VERSION ""

NS_ :

BS_:

BU_: VMCU TECU OBDScanT2 IC3 HPCU EMS ECUspare2 ECUspare1 DACU CIOM BBM

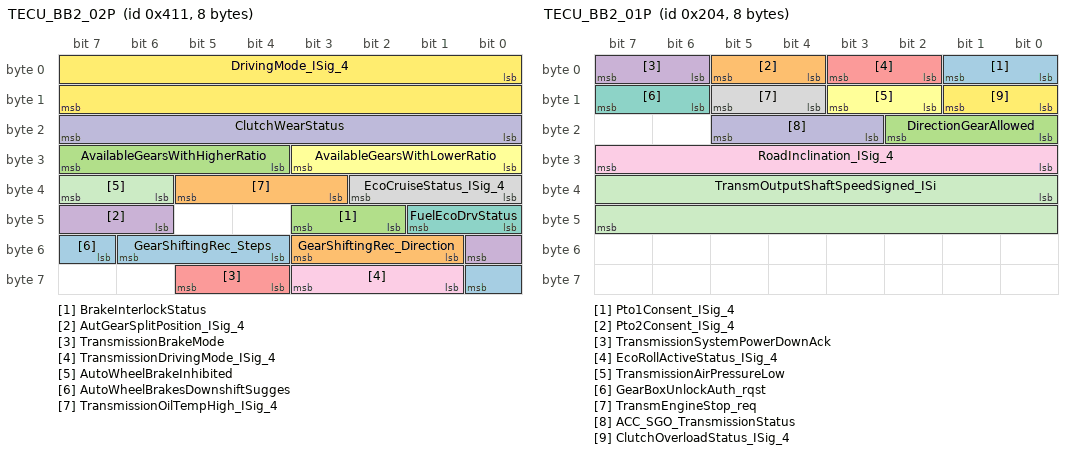
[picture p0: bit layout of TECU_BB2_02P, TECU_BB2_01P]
BO_ 1041 TECU_BB2_02P: 8 TECU
 SG_ GearShiftingRec_Steps : 52|3@1+ (1,0) [0|0] ""  IC3
 SG_ GearShiftingRec_Direction : 49|3@1+ (1,0) [0|0] ""  IC3
 SG_ BrakeInterlockStatus : 42|2@1+ (1,0) [0|0] ""  IC3,VMCU
 SG_ AutGearSplitPosition_ISig_4 : 46|3@1+ (1,0) [0|0] ""  IC3,BBM
 SG_ TransmissionBrakeMode : 60|2@1+ (1,0) [0|0] ""  IC3
 SG_ AvailableGearsWithLowerRatio : 24|4@1+ (1,0) [0|15] "Count"  IC3
 SG_ FuelEcoDrvStatus : 40|2@1+ (1,0) [0|0] ""  VMCU
 SG_ EcoCruiseStatus_ISig_4 : 32|3@1+ (1,0) [0|0] ""  IC3,EMS
 SG_ TransmissionDrivingMode_ISig_4 : 57|3@1+ (1,0) [0|0] ""  VMCU,DACU,IC3
 SG_ ClutchWearStatus : 16|8@1+ (0.4,0) [0|102] "Percent"  VMCU
 SG_ AutoWheelBrakeInhibited : 38|2@1+ (1,0) [0|0] ""  EMS
 SG_ DrivingMode_ISig_4 : 0|16@1+ (1,0) [0|0] ""  VMCU,IC3
 SG_ AutoWheelBrakesDownshiftSugges : 55|2@1+ (1,0) [0|0] ""  IC3
 SG_ TransmissionOilTempHigh_ISig_4 : 35|3@1+ (1,0) [0|0] ""  BBM,IC3
 SG_ AvailableGearsWithHigherRatio : 28|4@1+ (1,0) [0|15] "Count"  VMCU,IC3

BO_ 516 TECU_BB2_01P: 8 TECU
 SG_ Pto1Consent_ISig_4 : 0|2@1+ (1,0) [0|0] ""  BBM,VMCU
 SG_ Pto2Consent_ISig_4 : 4|2@1+ (1,0) [0|0] ""  BBM,VMCU
 SG_ DirectionGearAllowed : 16|3@1+ (1,0) [0|0] ""  VMCU
 SG_ TransmissionSystemPowerDownAck : 6|2@1+ (1,0) [0|0] ""  VMCU
 SG_ EcoRollActiveStatus_ISig_4 : 2|2@1+ (1,0) [0|0] ""  IC3,VMCU
 SG_ TransmissionAirPressureLow : 10|2@1+ (1,0) [0|0] ""  IC3
 SG_ GearBoxUnlockAuth_rqst : 14|2@1+ (1,0) [0|0] ""  CIOM
 SG_ TransmEngineStop_req : 12|2@1+ (1,0) [0|0] ""  EMS
 SG_ RoadInclination_ISig_4 : 24|8@1+ (0.2,-25) [-25|26] "Percent"  IC3,VMCU,EMS,DACU
 SG_ ACC_SGO_TransmissionStatus : 19|3@1+ (1,0) [0|0] ""  EMS,DACU
 SG_ TransmOutputShaftSpeedSigned_ISi : 32|16@1+ (0.125,-4000) [-4000|4191.875] "rpm"  DACU,VMCU
 SG_ ClutchOverloadStatus_ISig_4 : 8|2@1+ (1,0) [0|0] ""  IC3,BBM

BO_ 1792 Reserved_LogSync_BB2_01S: 8 Vector__XXX

BO_ 2365530173 Reserved_CANid_02_BB2: 8 Vector__XXX

BO_ 2365530429 Reserved_CANid_01_BB2: 8 Vector__XXX

BO_ 2671834660 PhysDiagRespMsg_F6_24_BB2: 8 VMCU
 SG_ PhysDiagRespSig_F6_24_ISig_4 : 0|64@1+ (1,0) [0|0] ""  CIOM

BO_ 2671834640 PhysDiagRespMsg_F6_10_BB2: 8 EMS
 SG_ PhysDiagRespSig_F6_10_ISig_4 : 0|64@1+ (1,0) [0|0] ""  CIOM

BO_ 2671833839 PhysDiagRespMsg_F2_EF_BB2: 8 HPCU
 SG_ PhysDiagRespSig_F2_EF_ISig_4 : 0|64@1+ (1,0) [0|0] ""  VMCU

BO_ 2671833830 PhysDiagRespMsg_F2_E6_BB2: 8 BBM
 SG_ PhysDiagRespSig_F2_E6_ISig_4 : 0|64@1+ (1,0) [0|0] ""  VMCU

BO_ 2671833829 PhysDiagRespMsg_F2_E5_BB2: 8 BBM
 SG_ PhysDiagRespSig_F2_E5_ISig_4 : 0|64@1+ (1,0) [0|0] ""  VMCU

BO_ 2671833794 PhysDiagRespMsg_F2_C2_BB2: 8 HPCU
 SG_ PhysDiagRespSig_F2_C2_ISig_4 : 0|64@1+ (1,0) [0|0] ""  VMCU

BO_ 2671833792 PhysDiagRespMsg_F2_C0_BB2: 8 CIOM
 SG_ PhysDiagRespSig_F2_C0_ISig_4 : 0|64@1+ (1,0) [0|0] ""  VMCU

BO_ 2671833762 PhysDiagRespMsg_F2_A2_BB2: 8 CIOM
 SG_ PhysDiagRespSig_F2_A2_ISig_4 : 0|64@1+ (1,0) [0|0] ""  VMCU

BO_ 2671833761 PhysDiagRespMsg_F2_A1_BB2: 8 CIOM
 SG_ PhysDiagRespSig_F2_A1_ISig_4 : 0|64@1+ (1,0) [0|0] ""  VMCU

BO_ 2671833760 PhysDiagRespMsg_F2_A0_BB2: 8 CIOM
 SG_ PhysDiagRespSig_F2_A0_ISig_4 : 0|64@1+ (1,0) [0|0] ""  VMCU

BO_ 2671833752 PhysDiagRespMsg_F2_98_BB2: 8 CIOM
 SG_ PhysDiagRespSig_F2_98_ISig_4 : 0|64@1+ (1,0) [0|0] ""  VMCU

BO_ 2671833740 PhysDiagRespMsg_F2_8C_BB2: 8 DACU
 SG_ PhysDiagRespSig_F2_8C_ISig_4 : 0|64@1+ (1,0) [0|0] ""  VMCU

BO_ 2671833731 PhysDiagRespMsg_F2_83_BB2: 8 IC3
 SG_ PhysDiagRespSig_F2_83_ISig_4 : 0|64@1+ (1,0) [0|0] ""  VMCU

BO_ 2671833730 PhysDiagRespMsg_F2_82_BB2: 8 IC3
 SG_ PhysDiagRespSig_F2_82_ISig_4 : 0|64@1+ (1,0) [0|0] ""  VMCU

BO_ 2671833700 PhysDiagRespMsg_F2_64_BB2: 8 IC3
 SG_ PhysDiagRespSig_F2_64_ISig_4 : 0|64@1+ (1,0) [0|0] ""  VMCU

BO_ 2671833697 PhysDiagRespMsg_F2_61_BB2: 8 IC3
 SG_ PhysDiagRespSig_F2_61_ISig_4 : 0|64@1+ (1,0) [0|0] ""  VMCU

BO_ 2671833696 PhysDiagRespMsg_F2_60_BB2: 8 IC3
 SG_ PhysDiagRespSig_F2_60_ISig_4 : 0|64@1+ (1,0) [0|0] ""  VMCU

BO_ 2671833683 PhysDiagRespMsg_F2_53_BB2: 8 CIOM
 SG_ PhysDiagRespSig_F2_53_ISig_4 : 0|64@1+ (1,0) [0|0] ""  VMCU

BO_ 2671833682 PhysDiagRespMsg_F2_52_BB2: 8 DACU
 SG_ PhysDiagRespSig_F2_52_ISig_4 : 0|64@1+ (1,0) [0|0] ""  VMCU

BO_ 2671833681 PhysDiagRespMsg_F2_51_BB2: 8 DACU
 SG_ PhysDiagRespSig_F2_51_ISig_4 : 0|64@1+ (1,0) [0|0] ""  VMCU

BO_ 2671833680 PhysDiagRespMsg_F2_50_BB2: 8 DACU
 SG_ PhysDiagRespSig_F2_50_ISig_4 : 0|64@1+ (1,0) [0|0] ""  VMCU

BO_ 2671833665 PhysDiagRespMsg_F2_41_BB2: 8 IC3
 SG_ PhysDiagRespSig_F2_41_ISig_4 : 0|64@1+ (1,0) [0|0] ""  VMCU

BO_ 2671833664 PhysDiagRespMsg_F2_40_BB2: 8 CIOM
 SG_ PhysDiagRespSig_F2_40_ISig_4 : 0|64@1+ (1,0) [0|0] ""  VMCU

BO_ 2671833638 PhysDiagRespMsg_F2_26_BB2: 8 CIOM
 SG_ PhysDiagRespSig_F2_26_ISig_4 : 0|64@1+ (1,0) [0|0] ""  VMCU

BO_ 2671833624 PhysDiagRespMsg_F2_18_BB2: 8 TECU
 SG_ PhysDiagRespSig_F2_18_ISig_4 : 0|64@1+ (1,0) [0|0] ""  VMCU

BO_ 2671833616 PhysDiagRespMsg_F2_10_BB2: 8 EMS
 SG_ PhysDiagRespSig_F2_10_ISig_4 : 0|64@1+ (1,0) [0|0] ""  VMCU

BO_ 2564485459 PhysDiagRespMsg_F1_53_BB2: 8 CIOM
 SG_ PhysDiagRespSig_F1_53_ISig_4 : 0|64@1+ (1,0) [0|0] ""  VMCU

BO_ 2564485392 PhysDiagRespMsg_F1_10_BB2_extra: 8 EMS
 SG_ PhysDiagRespSig_F1_10_extra : 0|64@1+ (1,0) [0|0] ""  OBDScanT2

BO_ 2671833360 PhysDiagRespMsg_F1_10_BB2: 8 EMS
 SG_ PhysDiagRespSig_F1_10_ISig_4 : 0|64@1+ (1,0) [0|0] ""  VMCU

BO_ 2671833074 PhysDiagReqMsg_EF_F2_BB2: 8 VMCU
 SG_ PhysDiagReqSig_EF_F2_ISig_4 : 0|64@1+ (1,0) [0|0] ""  HPCU

BO_ 2671830770 PhysDiagReqMsg_E6_F2_BB2: 8 VMCU
 SG_ PhysDiagReqSig_E6_F2_ISig_4 : 0|64@1+ (1,0) [0|0] ""  BBM

BO_ 2671830514 PhysDiagReqMsg_E5_F2_BB2: 8 VMCU
 SG_ PhysDiagReqSig_E5_F2_ISig_4 : 0|64@1+ (1,0) [0|0] ""  BBM

BO_ 2671821554 PhysDiagReqMsg_C2_F2_BB2: 8 VMCU
 SG_ PhysDiagReqSig_C2_F2_ISig_4 : 0|64@1+ (1,0) [0|0] ""  HPCU

BO_ 2671821042 PhysDiagReqMsg_C0_F2_BB2: 8 VMCU
 SG_ PhysDiagReqSig_C0_F2_ISig_4 : 0|64@1+ (1,0) [0|0] ""  CIOM

BO_ 2671813362 PhysDiagReqMsg_A2_F2_BB2: 8 VMCU
 SG_ PhysDiagReqSig_A2_F2_ISig_4 : 0|64@1+ (1,0) [0|0] ""  CIOM

BO_ 2671813106 PhysDiagReqMsg_A1_F2_BB2: 8 VMCU
 SG_ PhysDiagReqSig_A1_F2_ISig_4 : 0|64@1+ (1,0) [0|0] ""  CIOM

BO_ 2671812850 PhysDiagReqMsg_A0_F2_BB2: 8 VMCU
 SG_ PhysDiagReqSig_A0_F2_ISig_4 : 0|64@1+ (1,0) [0|0] ""  CIOM

BO_ 2671810802 PhysDiagReqMsg_98_F2_BB2: 8 VMCU
 SG_ PhysDiagReqSig_98_F2_ISig_4 : 0|64@1+ (1,0) [0|0] ""  CIOM

BO_ 2671807730 PhysDiagReqMsg_8C_F2_BB2: 8 VMCU
 SG_ PhysDiagReqSig_8C_F2_ISig_4 : 0|64@1+ (1,0) [0|0] ""  DACU

BO_ 2671805426 PhysDiagReqMsg_83_F2_BB2: 8 VMCU
 SG_ PhysDiagReqSig_83_F2_ISig_4 : 0|64@1+ (1,0) [0|0] ""  IC3

BO_ 2671805170 PhysDiagReqMsg_82_F2_BB2: 8 VMCU
 SG_ PhysDiagReqSig_82_F2_ISig_4 : 0|64@1+ (1,0) [0|0] ""  IC3

BO_ 2671797490 PhysDiagReqMsg_64_F2_BB2: 8 VMCU
 SG_ PhysDiagReqSig_64_F2_ISig_4 : 0|64@1+ (1,0) [0|0] ""  IC3

BO_ 2671796722 PhysDiagReqMsg_61_F2_BB2: 8 VMCU
 SG_ PhysDiagReqSig_61_F2_ISig_4 : 0|64@1+ (1,0) [0|0] ""  IC3

BO_ 2671796466 PhysDiagReqMsg_60_F2_BB2: 8 VMCU
 SG_ PhysDiagReqSig_60_F2_ISig_4 : 0|64@1+ (1,0) [0|0] ""  IC3

BO_ 2671793138 PhysDiagReqMsg_53_F2_BB2: 8 VMCU
 SG_ PhysDiagReqSig_53_F2_ISig_4 : 0|64@1+ (1,0) [0|0] ""  CIOM

BO_ 2564445169 PhysDiagReqMsg_53_F1_BB2: 8 VMCU
 SG_ PhysDiagReqSig_53_F1_ISig_4 : 0|64@1+ (1,0) [0|0] ""  CIOM

BO_ 2671792882 PhysDiagReqMsg_52_F2_BB2: 8 VMCU
 SG_ PhysDiagReqSig_52_F2_ISig_4 : 0|64@1+ (1,0) [0|0] ""  DACU

BO_ 2671792626 PhysDiagReqMsg_51_F2_BB2: 8 VMCU
 SG_ PhysDiagReqSig_51_F2_ISig_4 : 0|64@1+ (1,0) [0|0] ""  DACU

BO_ 2671792370 PhysDiagReqMsg_50_F2_BB2: 8 VMCU
 SG_ PhysDiagReqSig_50_F2_ISig_4 : 0|64@1+ (1,0) [0|0] ""  DACU

BO_ 2671788530 PhysDiagReqMsg_41_F2_BB2: 8 VMCU
 SG_ PhysDiagReqSig_41_F2_ISig_4 : 0|64@1+ (1,0) [0|0] ""  IC3

BO_ 2671788274 PhysDiagReqMsg_40_F2_BB2: 8 VMCU
 SG_ PhysDiagReqSig_40_F2_ISig_4 : 0|64@1+ (1,0) [0|0] ""  CIOM

BO_ 2671781618 PhysDiagReqMsg_26_F2_BB2: 8 VMCU
 SG_ PhysDiagReqSig_26_F2_ISig_4 : 0|64@1+ (1,0) [0|0] ""  CIOM

BO_ 2671781110 PhysDiagReqMsg_24_F6_BB2: 8 CIOM
 SG_ PhysDiagReqSig_24_F6_ISig_4 : 0|64@1+ (1,0) [0|0] ""  VMCU

BO_ 2671778034 PhysDiagReqMsg_18_F2_BB2: 8 VMCU
 SG_ PhysDiagReqSig_18_F2_ISig_4 : 0|64@1+ (1,0) [0|0] ""  TECU

BO_ 2671775990 PhysDiagReqMsg_10_F6_BB2: 8 CIOM
 SG_ PhysDiagReqSig_10_F6_ISig_4 : 0|64@1+ (1,0) [0|0] ""  EMS

BO_ 2671775986 PhysDiagReqMsg_10_F2_BB2: 8 VMCU
 SG_ PhysDiagReqSig_10_F2_ISig_4 : 0|64@1+ (1,0) [0|0] ""  EMS

BO_ 2564428017 PhysDiagReqMsg_10_F1_BB2_extra: 8 OBDScanT2
 SG_ PhysDiagReqSig_10_F1_extra : 0|64@1+ (1,0) [0|0] ""  EMS

BO_ 2671775985 PhysDiagReqMsg_10_F1_BB2: 8 VMCU
 SG_ PhysDiagReqSig_10_F1_ISig_4 : 0|64@1+ (1,0) [0|0] ""  EMS

BO_ 2564502513 OBDFuncDiagMsg_BB2_extra: 8 OBDScanT2
 SG_ FuncDiagDataOBD_extra : 0|64@1+ (1,0) [0|0] ""  EMS

BO_ 2671850481 OBDFuncDiagMsg_BB2: 8 VMCU
 SG_ FuncDiagDataOBD_ISig_4 : 0|64@1+ (1,0) [0|0] ""  EMS

BO_ 2671850486 OBDFuncDiagMsgF6_BB2: 8 CIOM
 SG_ FuncDiagDataOBDF6_ISig_4 : 0|64@1+ (1,0) [0|0] ""  EMS,VMCU

BO_ 2633990180 NmAsr_VMCU_BB2: 1 VMCU

BO_ 2633990168 NmAsr_TECU_BB2: 1 TECU

BO_ 2633990383 NmAsr_HPCU_BB2: 1 HPCU

BO_ 2633990240 NmAsr_HMIIOM_BB2: 1 IC3

BO_ 2633990160 NmAsr_EMS_BB2: 1 EMS

BO_ 2633990224 NmAsr_DACU_BB2: 1 DACU

BO_ 2633990208 NmAsr_CIOM_BB2: 1 CIOM

BO_ 2633990374 NmAsr_BBM_BB2: 1 BBM

BO_ 2671902708 IntTesterTGW2FuncDiagMsg_BB2: 8 IC3
 SG_ FuncDiagDataIntTesterTGW2_ISig_4 : 0|64@1+ (1,0) [0|0] ""  EMS,HPCU,BBM,DACU,CIOM,TECU,VMCU

BO_ 1280 IC3_BB2_FAKE1: 8 IC3
 SG_ ExteriorLightsAFSAllowedFAKE : 2|2@1+ (1,0) [0|0] ""  VMCU
 SG_ CamerasPowerSupply_rqstFAKE : 0|2@1+ (1,0) [0|0] ""  VMCU

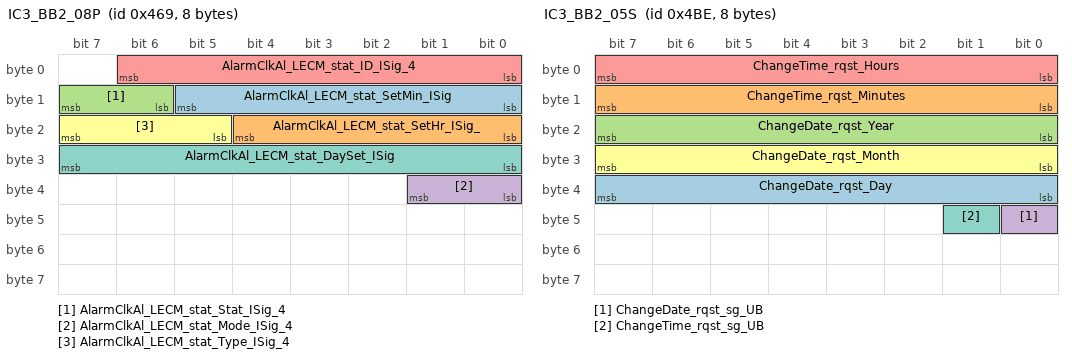
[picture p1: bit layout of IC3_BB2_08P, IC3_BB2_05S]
BO_ 1129 IC3_BB2_08P: 8 IC3
 SG_ AlarmClkAl_LECM_stat_SetMin_ISig : 8|6@1+ (1,0) [0|63] "min"  CIOM
 SG_ AlarmClkAl_LECM_stat_SetHr_ISig_ : 16|5@1+ (1,0) [0|31] "h"  CIOM
 SG_ AlarmClkAl_LECM_stat_Stat_ISig_4 : 14|2@1+ (1,0) [0|0] ""  CIOM
 SG_ AlarmClkAl_LECM_stat_Mode_ISig_4 : 32|2@1+ (1,0) [0|0] ""  CIOM
 SG_ AlarmClkAl_LECM_stat_ID_ISig_4 : 0|7@1+ (1,0) [0|0] ""  CIOM
 SG_ AlarmClkAl_LECM_stat_Type_ISig_4 : 21|3@1+ (1,0) [0|0] ""  CIOM
 SG_ AlarmClkAl_LECM_stat_DaySet_ISig : 24|8@1+ (1,0) [0|255] ""  CIOM

BO_ 1395 IC3_BB2_07S_FCM: 8 CIOM
 SG_ IC3_BB2_07S_FCS : 0|64@1+ (1,0) [0|0] ""  IC3

BO_ 1394 IC3_BB2_07S: 36 IC3
 SG_ DisplayText_stat_ISig_4 : 0|288@1+ (1,0) [0|0] ""  CIOM

BO_ 1444 IC3_BB2_06S_FCM: 8 VMCU
 SG_ IC3_BB2_06S_FCS : 0|64@1+ (1,0) [0|0] ""  IC3

BO_ 1443 IC3_BB2_06S: 21 IC3
 SG_ SaveTrlrName_rqst_Request : 160|2@1+ (1,0) [0|0] ""  VMCU
 SG_ SaveTrlrName_rqst_sg_UB : 167|1@1+ (1,0) [0|0] ""  VMCU
 SG_ SaveTrlrName_rqst_NewName : 0|160@1+ (1,0) [0|0] ""  VMCU
 SG_ SaveTrlrName_rqst_Position : 162|5@1+ (1,0) [0|0] ""  VMCU

BO_ 1214 IC3_BB2_05S: 8 IC3
 SG_ ChangeDate_rqst_Day : 32|8@1+ (1,0) [0|255] "Days"  VMCU
 SG_ ChangeTime_rqst_Minutes : 8|8@1+ (1,0) [0|255] "min"  VMCU
 SG_ ChangeDate_rqst_Year : 16|8@1+ (1,1985) [1985|2240] "Years"  VMCU
 SG_ ChangeDate_rqst_sg_UB : 40|1@1+ (1,0) [0|0] ""  VMCU
 SG_ ChangeTime_rqst_Hours : 0|8@1+ (1,0) [0|255] "h"  VMCU
 SG_ ChangeDate_rqst_Month : 24|8@1+ (1,0) [0|255] "Months"  VMCU
 SG_ ChangeTime_rqst_sg_UB : 41|1@1+ (1,0) [0|0] ""  VMCU

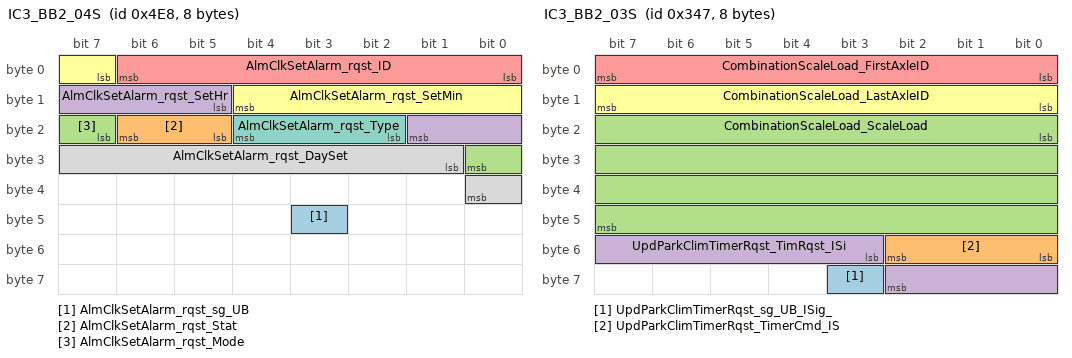
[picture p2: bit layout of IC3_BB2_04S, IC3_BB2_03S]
BO_ 1256 IC3_BB2_04S: 8 IC3
 SG_ AlmClkSetAlarm_rqst_sg_UB : 43|1@1+ (1,0) [0|0] ""  VMCU
 SG_ AlmClkSetAlarm_rqst_Stat : 21|2@1+ (1,0) [0|0] ""  VMCU
 SG_ AlmClkSetAlarm_rqst_Mode : 23|2@1+ (1,0) [0|0] ""  VMCU
 SG_ AlmClkSetAlarm_rqst_SetHr : 13|5@1+ (1,0) [0|31] "h"  VMCU
 SG_ AlmClkSetAlarm_rqst_ID : 0|7@1+ (1,0) [0|0] ""  VMCU
 SG_ AlmClkSetAlarm_rqst_SetMin : 7|6@1+ (1,0) [0|63] "min"  VMCU
 SG_ AlmClkSetAlarm_rqst_Type : 18|3@1+ (1,0) [0|0] ""  VMCU
 SG_ AlmClkSetAlarm_rqst_DaySet : 25|8@1+ (1,0) [0|255] ""  VMCU

BO_ 839 IC3_BB2_03S: 8 IC3
 SG_ UpdParkClimTimerRqst_sg_UB_ISig_ : 59|1@1+ (1,0) [0|0] ""  CIOM
 SG_ UpdParkClimTimerRqst_TimerCmd_IS : 48|3@1+ (1,0) [0|0] ""  CIOM
 SG_ CombinationScaleLoad_ScaleLoad : 16|32@1+ (1,0) [0|4294967295] "kg"  VMCU
 SG_ UpdParkClimTimerRqst_TimRqst_ISi : 51|8@1+ (1,0) [0|0] ""  CIOM
 SG_ CombinationScaleLoad_FirstAxleID : 0|8@1+ (1,0) [0|255] "NotApplicable"  VMCU
 SG_ CombinationScaleLoad_LastAxleID : 8|8@1+ (1,0) [0|255] "NotApplicable"  VMCU

BO_ 838 IC3_BB2_02P: 8 IC3
 SG_ PhoneButtonIndication_cmd : 39|2@1+ (1,0) [0|0] ""  CIOM
 SG_ AirbagTelltale_stat_ISig_4 : 17|2@1+ (1,0) [0|0] ""  CIOM
 SG_ AudioSystemStatus_ISig_4 : 52|2@1+ (1,0) [0|0] ""  CIOM
 SG_ AudioSourceUsbAvailable_ISig_4 : 21|2@1+ (1,0) [0|0] ""  CIOM
 SG_ AQSModeRqst_ISig_4 : 9|3@1+ (1,0) [0|0] ""  CIOM
 SG_ PresetIndicationCmd_ISig_4 : 41|6@1+ (1,0) [0|63] "Enumeration"  CIOM
 SG_ AudioSourceCdAvailable_ISig_4 : 50|2@1+ (1,0) [0|0] ""  CIOM
 SG_ AudioVolumeIndicationCmd_ISig_4 : 31|6@1+ (1,0) [0|63] "Step"  CIOM
 SG_ AudioSourceStatus2_ISig_4 : 59|4@1+ (1,0) [0|0] ""  CIOM
 SG_ BTStatus : 54|2@1+ (1,0) [0|0] ""  CIOM
 SG_ VCSystPowerSupply_rqst : 15|2@1+ (1,0) [0|0] ""  VMCU
 SG_ AudioSourceBtStreamAvailable_ISi : 37|2@1+ (1,0) [0|0] ""  CIOM
 SG_ AudioMuteStat_ISig_4 : 56|3@1+ (1,0) [0|0] ""  CIOM
 SG_ ISeeEnableRequest : 19|2@1+ (1,0) [0|0] ""  TECU
 SG_ ACModeRqst_ISig_4 : 0|3@1+ (1,0) [0|0] ""  CIOM
 SG_ AudioSourceStatus_ISig_4 : 47|3@1+ (1,0) [0|0] ""  CIOM
 SG_ CalDataLoad_rqst_VehicleID : 28|3@1+ (1,0) [0|0] ""  VMCU
 SG_ AudioSourceIpodAvailable_ISig_4 : 3|2@1+ (1,0) [0|0] ""  CIOM
 SG_ CalDataLoad_rqst_AxleID : 24|4@1+ (1,0) [0|0] ""  VMCU
 SG_ AutoBlowerLevelRqst_ISig_4 : 12|3@1+ (1,0) [0|0] ""  CIOM
 SG_ AutoDefogModeRqst_ISig_4 : 6|3@1+ (1,0) [0|0] ""  CIOM

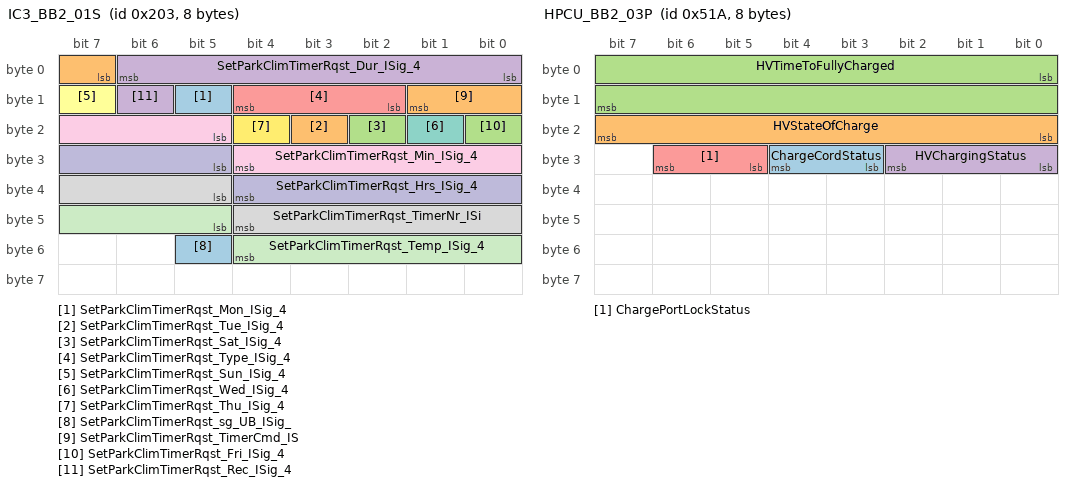
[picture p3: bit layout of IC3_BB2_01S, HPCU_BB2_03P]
BO_ 515 IC3_BB2_01S: 8 IC3
 SG_ SetParkClimTimerRqst_Mon_ISig_4 : 13|1@1+ (1,0) [0|0] ""  CIOM
 SG_ SetParkClimTimerRqst_Tue_ISig_4 : 19|1@1+ (1,0) [0|0] ""  CIOM
 SG_ SetParkClimTimerRqst_Sat_ISig_4 : 18|1@1+ (1,0) [0|0] ""  CIOM
 SG_ SetParkClimTimerRqst_Dur_ISig_4 : 0|7@1+ (1,0) [0|127] "min"  CIOM
 SG_ SetParkClimTimerRqst_Type_ISig_4 : 10|3@1+ (1,0) [0|0] ""  CIOM
 SG_ SetParkClimTimerRqst_Sun_ISig_4 : 15|1@1+ (1,0) [0|0] ""  CIOM
 SG_ SetParkClimTimerRqst_Wed_ISig_4 : 17|1@1+ (1,0) [0|0] ""  CIOM
 SG_ SetParkClimTimerRqst_TimerNr_ISi : 37|8@1+ (1,0) [0|0] ""  CIOM
 SG_ SetParkClimTimerRqst_Min_ISig_4 : 21|8@1+ (1,0) [0|255] "min"  CIOM
 SG_ SetParkClimTimerRqst_Hrs_ISig_4 : 29|8@1+ (1,0) [0|255] "h"  CIOM
 SG_ SetParkClimTimerRqst_Temp_ISig_4 : 45|8@1+ (0.5,0) [0|127.5] "DegreeC"  CIOM
 SG_ SetParkClimTimerRqst_Thu_ISig_4 : 20|1@1+ (1,0) [0|0] ""  CIOM
 SG_ SetParkClimTimerRqst_sg_UB_ISig_ : 53|1@1+ (1,0) [0|0] ""  CIOM
 SG_ SetParkClimTimerRqst_TimerCmd_IS : 7|3@1+ (1,0) [0|0] ""  CIOM
 SG_ SetParkClimTimerRqst_Fri_ISig_4 : 16|1@1+ (1,0) [0|0] ""  CIOM
 SG_ SetParkClimTimerRqst_Rec_ISig_4 : 14|1@1+ (1,0) [0|0] ""  CIOM

BO_ 1306 HPCU_BB2_03P: 8 HPCU
 SG_ ChargeCordStatus : 27|2@1+ (1,0) [0|0] ""  IC3,VMCU
 SG_ HVStateOfCharge : 16|8@1+ (1,0) [0|255] "Percent"  IC3
 SG_ HVTimeToFullyCharged : 0|16@1+ (1,0) [0|65535] "s"  IC3
 SG_ HVChargingStatus : 24|3@1+ (1,0) [0|0] ""  IC3
 SG_ ChargePortLockStatus : 29|2@1+ (1,0) [0|0] ""  IC3

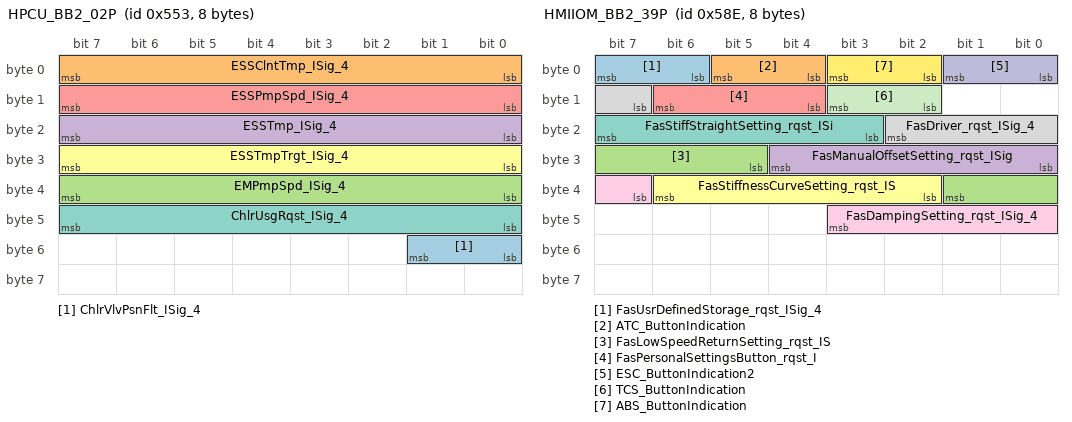
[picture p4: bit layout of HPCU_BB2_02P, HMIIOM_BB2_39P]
BO_ 1363 HPCU_BB2_02P: 8 HPCU
 SG_ ChlrVlvPsnFlt_ISig_4 : 48|2@1+ (1,0) [0|0] ""  CIOM
 SG_ ESSClntTmp_ISig_4 : 0|8@1+ (1,0) [0|255] "DegreeC"  CIOM
 SG_ EMPmpSpd_ISig_4 : 32|8@1+ (1,0) [0|255] "Percent"  CIOM
 SG_ ESSTmp_ISig_4 : 16|8@1+ (1,-60) [-60|195] "DegreeC"  CIOM
 SG_ ESSPmpSpd_ISig_4 : 8|8@1+ (1,0) [0|255] "Percent"  CIOM
 SG_ ESSTmpTrgt_ISig_4 : 24|8@1+ (1,0) [0|255] "DegreeC"  CIOM
 SG_ ChlrUsgRqst_ISig_4 : 40|8@1+ (1,0) [0|255] "Percent"  CIOM

BO_ 1110 HPCU_BB2_01P: 8 HPCU
 SG_ EpsPowerSupplyAck : 2|2@1+ (1,0) [0|0] ""  VMCU
 SG_ ReqEpsAlive : 0|2@1+ (1,0) [0|0] ""  VMCU

BO_ 1477 HMIIOM_BB2_S28_FCM: 8 TECU
 SG_ HMIIOM_BB2_S28_FCS : 0|64@1+ (1,0) [0|0] ""  IC3

BO_ 1422 HMIIOM_BB2_39P: 8 IC3
 SG_ FasUsrDefinedStorage_rqst_ISig_4 : 6|2@1+ (1,0) [0|0] ""  VMCU
 SG_ ATC_ButtonIndication : 4|2@1+ (1,0) [0|0] ""  CIOM
 SG_ FasLowSpeedReturnSetting_rqst_IS : 29|5@1+ (1,-10) [-10|21] ""  VMCU
 SG_ FasManualOffsetSetting_rqst_ISig : 24|5@1+ (1,-10) [-10|21] ""  VMCU
 SG_ FasPersonalSettingsButton_rqst_I : 12|3@1+ (1,0) [0|0] ""  VMCU
 SG_ FasStiffnessCurveSetting_rqst_IS : 34|5@1+ (1,-10) [-10|21] ""  VMCU
 SG_ FasStiffStraightSetting_rqst_ISi : 19|5@1+ (1,-10) [-10|21] ""  VMCU
 SG_ FasDriver_rqst_ISig_4 : 15|4@1+ (1,0) [0|0] ""  VMCU
 SG_ FasDampingSetting_rqst_ISig_4 : 39|5@1+ (1,-10) [-10|21] ""  VMCU
 SG_ ESC_ButtonIndication2 : 0|2@1+ (1,0) [0|0] ""  CIOM
 SG_ TCS_ButtonIndication : 10|2@1+ (1,0) [0|0] ""  CIOM
 SG_ ABS_ButtonIndication : 2|2@1+ (1,0) [0|0] ""  CIOM

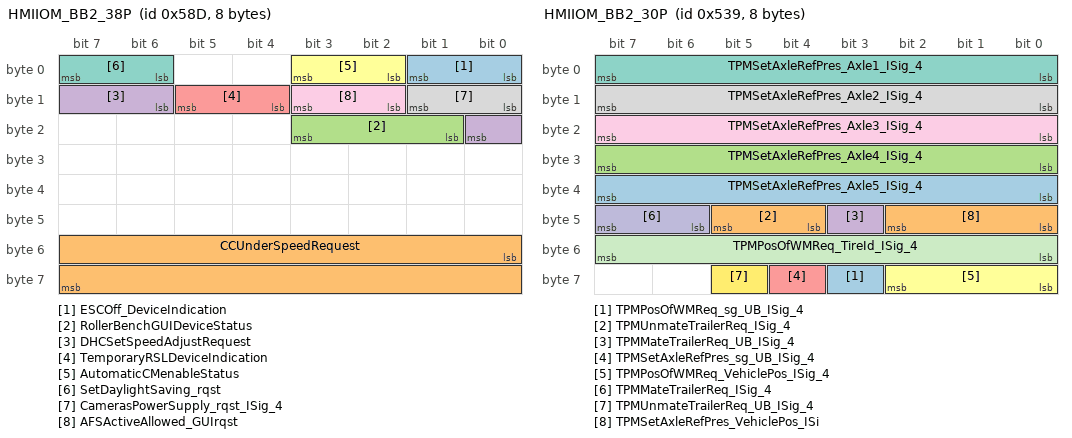
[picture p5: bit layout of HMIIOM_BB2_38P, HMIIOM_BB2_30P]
BO_ 1421 HMIIOM_BB2_38P: 8 IC3
 SG_ ESCOff_DeviceIndication : 0|2@1+ (1,0) [0|0] ""  CIOM
 SG_ CCUnderSpeedRequest : 48|16@1+ (0.00390625,0) [0|255.99609375] "Km_per_h"  VMCU
 SG_ RollerBenchGUIDeviceStatus : 17|3@1+ (1,0) [0|0] ""  CIOM
 SG_ DHCSetSpeedAdjustRequest : 14|3@1+ (1,0) [0|0] ""  VMCU
 SG_ TemporaryRSLDeviceIndication : 12|2@1+ (1,0) [0|0] ""  CIOM
 SG_ AutomaticCMenableStatus : 2|2@1+ (1,0) [0|0] ""  DACU
 SG_ SetDaylightSaving_rqst : 6|2@1+ (1,0) [0|0] ""  VMCU
 SG_ CamerasPowerSupply_rqst_ISig_4 : 8|2@1+ (1,0) [0|0] ""  VMCU
 SG_ AFSActiveAllowed_GUIrqst : 10|2@1+ (1,0) [0|0] ""  VMCU

BO_ 518 HMIIOM_BB2_37S: 8 IC3
 SG_ AdasisMapData_ISig_4 : 7|64@0+ (1,0) [0|0] ""  TECU,DACU

BO_ 1397 HMIIOM_BB2_36S_FCM: 8 CIOM
 SG_ HMIIOM_BB2_36S_FCS : 0|64@1+ (1,0) [0|0] ""  IC3

BO_ 1396 HMIIOM_BB2_36S: 36 IC3
 SG_ SEM_DisplayText_stat_ISig_4 : 0|288@1+ (1,0) [0|0] ""  CIOM

BO_ 952 HMIIOM_BB2_35S_FCM: 8 CIOM
 SG_ HMIIOM_BB2_35S_FCS : 0|64@1+ (1,0) [0|0] ""  IC3

BO_ 949 HMIIOM_BB2_35S: 98 IC3
 SG_ MediaSourcesListRsp_sg_UB_ISig_4 : 782|1@1+ (1,0) [0|0] ""  CIOM
 SG_ MediaSourcesListRsp_SrcAttrib_IS : 392|384@1+ (1,0) [0|0] ""  CIOM
 SG_ MediaSourcesListRsp_SInfo_ISig_4 : 780|2@1+ (1,0) [0|0] ""  CIOM
 SG_ MediaSourcesListRsp_Name_ISig_4 : 8|384@1+ (1,0) [0|0] ""  CIOM
 SG_ MediaSourcesListRsp_PCI_ISig_4 : 0|8@1+ (1,0) [0|255] ""  CIOM
 SG_ MediaSourcesListRsp_ItemID_ISig_ : 776|4@1+ (1,0) [0|0] ""  CIOM

BO_ 967 HMIIOM_BB2_34S: 8 IC3
 SG_ MediaSourcesListNPRsp_ISig_4 : 0|8@1+ (1,0) [0|255] ""  CIOM
 SG_ MediaSourcesListNPRsp_UB_ISig_4 : 8|1@1+ (1,0) [0|0] ""  CIOM

BO_ 822 HMIIOM_BB2_33P: 8 IC3
 SG_ SEMMediaSourceAvail_Source04_ISi : 4|1@1+ (1,0) [0|0] ""  CIOM
 SG_ SEMMediaSourceAvail_Source10_ISi : 10|1@1+ (1,0) [0|0] ""  CIOM
 SG_ SEMMediaSourceAvail_SInfo_ISig_4 : 14|2@1+ (1,0) [0|0] ""  CIOM
 SG_ SEM_PresetIndicationCmd_ISig_4 : 25|6@1+ (1,0) [0|63] "Enumeration"  CIOM
 SG_ SEMMediaSourceAvail_Source09_ISi : 9|1@1+ (1,0) [0|0] ""  CIOM
 SG_ SEMMediaSourceAvail_Source12_ISi : 12|1@1+ (1,0) [0|0] ""  CIOM
 SG_ SEMMediaSourceAvail_Source07_ISi : 7|1@1+ (1,0) [0|0] ""  CIOM
 SG_ SEMMediaSourceAvail_Source03_ISi : 3|1@1+ (1,0) [0|0] ""  CIOM
 SG_ SEMMediaSourceAvail_Source11_ISi : 11|1@1+ (1,0) [0|0] ""  CIOM
 SG_ SEM_AudioVolValIndCmd_ISig_4 : 19|6@1+ (1,0) [0|63] "Step"  CIOM
 SG_ SEMMediaSourceAvail_Source02_ISi : 2|1@1+ (1,0) [0|0] ""  CIOM
 SG_ AudioSourceStat_ISig_4 : 31|4@1+ (1,0) [0|0] ""  CIOM
 SG_ SEMMediaSourceAvail_Source06_ISi : 6|1@1+ (1,0) [0|0] ""  CIOM
 SG_ SEMMediaSourceAvail_Source00_ISi : 0|1@1+ (1,0) [0|0] ""  CIOM
 SG_ SEMMediaSourceAvail_Source01_ISi : 1|1@1+ (1,0) [0|0] ""  CIOM
 SG_ SEMMediaSourceAvail_Source08_ISi : 8|1@1+ (1,0) [0|0] ""  CIOM
 SG_ SEM_AudioMuteStat_ISig_4 : 16|3@1+ (1,0) [0|0] ""  CIOM
 SG_ SEMMediaSourceAvail_Source13_ISi : 13|1@1+ (1,0) [0|0] ""  CIOM
 SG_ SEMMediaSourceAvail_Source05_ISi : 5|1@1+ (1,0) [0|0] ""  CIOM

BO_ 1337 HMIIOM_BB2_30P: 8 IC3
 SG_ TPMPosOfWMReq_sg_UB_ISig_4 : 59|1@1+ (1,0) [0|0] ""  VMCU
 SG_ TPMUnmateTrailerReq_ISig_4 : 44|2@1+ (1,0) [0|0] ""  VMCU
 SG_ TPMSetAxleRefPres_Axle4_ISig_4 : 24|8@1+ (10,0) [0|2550] "kPa"  VMCU
 SG_ TPMMateTrailerReq_UB_ISig_4 : 43|1@1+ (1,0) [0|0] ""  VMCU
 SG_ TPMSetAxleRefPres_sg_UB_ISig_4 : 60|1@1+ (1,0) [0|0] ""  VMCU
 SG_ TPMPosOfWMReq_VehiclePos_ISig_4 : 56|3@1+ (1,0) [0|0] ""  VMCU
 SG_ TPMSetAxleRefPres_Axle1_ISig_4 : 0|8@1+ (10,0) [0|2550] "kPa"  VMCU
 SG_ TPMSetAxleRefPres_Axle2_ISig_4 : 8|8@1+ (10,0) [0|2550] "kPa"  VMCU
 SG_ TPMSetAxleRefPres_Axle3_ISig_4 : 16|8@1+ (10,0) [0|2550] "kPa"  VMCU
 SG_ TPMMateTrailerReq_ISig_4 : 46|2@1+ (1,0) [0|0] ""  VMCU
 SG_ TPMPosOfWMReq_TireId_ISig_4 : 48|8@1+ (1,0) [0|255] "NotApplicable"  VMCU
 SG_ TPMUnmateTrailerReq_UB_ISig_4 : 61|1@1+ (1,0) [0|0] ""  VMCU
 SG_ TPMSetAxleRefPres_Axle5_ISig_4 : 32|8@1+ (10,0) [0|2550] "kPa"  VMCU
 SG_ TPMSetAxleRefPres_VehiclePos_ISi : 40|3@1+ (1,0) [0|0] ""  VMCU

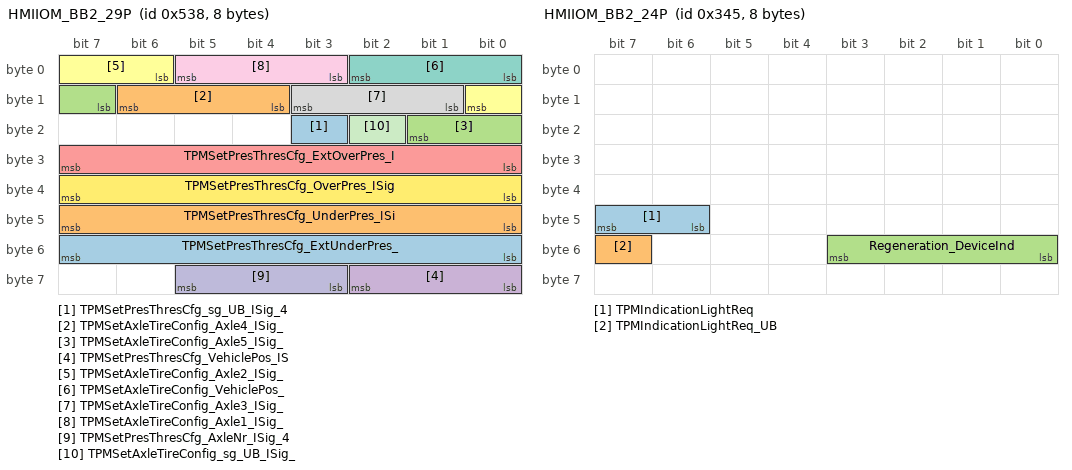
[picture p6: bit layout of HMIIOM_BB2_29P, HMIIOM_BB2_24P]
BO_ 1336 HMIIOM_BB2_29P: 8 IC3
 SG_ TPMSetPresThresCfg_sg_UB_ISig_4 : 19|1@1+ (1,0) [0|0] ""  VMCU
 SG_ TPMSetAxleTireConfig_Axle4_ISig_ : 12|3@1+ (1,0) [0|0] ""  VMCU
 SG_ TPMSetAxleTireConfig_Axle5_ISig_ : 15|3@1+ (1,0) [0|0] ""  VMCU
 SG_ TPMSetPresThresCfg_VehiclePos_IS : 56|3@1+ (1,0) [0|0] ""  VMCU
 SG_ TPMSetPresThresCfg_ExtOverPres_I : 24|8@1+ (1,-125) [-125|130] "Percent"  VMCU
 SG_ TPMSetAxleTireConfig_Axle2_ISig_ : 6|3@1+ (1,0) [0|0] ""  VMCU
 SG_ TPMSetAxleTireConfig_VehiclePos_ : 0|3@1+ (1,0) [0|0] ""  VMCU
 SG_ TPMSetAxleTireConfig_Axle3_ISig_ : 9|3@1+ (1,0) [0|0] ""  VMCU
 SG_ TPMSetAxleTireConfig_Axle1_ISig_ : 3|3@1+ (1,0) [0|0] ""  VMCU
 SG_ TPMSetPresThresCfg_AxleNr_ISig_4 : 59|3@1+ (1,0) [0|0] ""  VMCU
 SG_ TPMSetAxleTireConfig_sg_UB_ISig_ : 18|1@1+ (1,0) [0|0] ""  VMCU
 SG_ TPMSetPresThresCfg_OverPres_ISig : 32|8@1+ (1,-125) [-125|130] "Percent"  VMCU
 SG_ TPMSetPresThresCfg_ExtUnderPres_ : 48|8@1+ (1,-125) [-125|130] "Percent"  VMCU
 SG_ TPMSetPresThresCfg_UnderPres_ISi : 40|8@1+ (1,-125) [-125|130] "Percent"  VMCU

BO_ 1476 HMIIOM_BB2_28S: 284 IC3
 SG_ HillDataPkgTGW_ISig_4 : 0|2272@1+ (1,0) [0|0] ""  TECU

BO_ 837 HMIIOM_BB2_24P: 8 IC3
 SG_ TPMIndicationLightReq : 46|2@1+ (1,0) [0|0] ""  VMCU
 SG_ TPMIndicationLightReq_UB : 55|1@1+ (1,0) [0|0] ""  VMCU
 SG_ Regeneration_DeviceInd : 48|4@1+ (1,0) [0|0] ""  CIOM

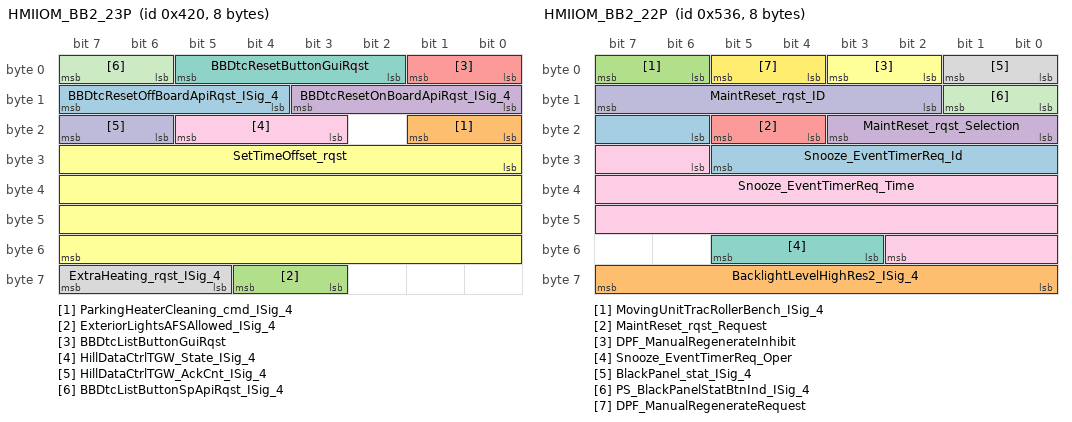
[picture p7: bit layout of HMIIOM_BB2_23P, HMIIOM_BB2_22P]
BO_ 1056 HMIIOM_BB2_23P: 8 IC3
 SG_ BBDtcResetOffBoardApiRqst_ISig_4 : 12|4@1+ (1,0) [0|0] ""  BBM
 SG_ ParkingHeaterCleaning_cmd_ISig_4 : 16|2@1+ (1,0) [0|0] ""  CIOM
 SG_ ExteriorLightsAFSAllowed_ISig_4 : 59|2@1+ (1,0) [0|0] ""  VMCU
 SG_ BBDtcResetOnBoardApiRqst_ISig_4 : 8|4@1+ (1,0) [0|0] ""  BBM
 SG_ BBDtcListButtonGuiRqst : 0|2@1+ (1,0) [0|0] ""  BBM
 SG_ SetTimeOffset_rqst : 24|32@1+ (1,-86400) [-86400|4294880895] "s"  VMCU
 SG_ BBDtcResetButtonGuiRqst : 2|4@1+ (1,0) [0|0] ""  BBM
 SG_ ExtraHeating_rqst_ISig_4 : 61|3@1+ (1,0) [0|0] ""  CIOM
 SG_ HillDataCtrlTGW_State_ISig_4 : 19|3@1+ (1,0) [0|0] ""  TECU
 SG_ HillDataCtrlTGW_AckCnt_ISig_4 : 22|2@1+ (1,0) [0|3] ""  TECU
 SG_ BBDtcListButtonSpApiRqst_ISig_4 : 6|2@1+ (1,0) [0|0] ""  BBM

BO_ 1334 HMIIOM_BB2_22P: 8 IC3
 SG_ Snooze_EventTimerReq_Id : 22|8@1+ (1,0) [0|0] ""  VMCU
 SG_ BacklightLevelHighRes2_ISig_4 : 56|8@1+ (0.4,0) [0|102] "Percent"  CIOM,BBM,VMCU
 SG_ MovingUnitTracRollerBench_ISig_4 : 6|2@1+ (1,0) [0|0] ""  CIOM
 SG_ MaintReset_rqst_Selection : 16|4@1+ (1,0) [0|15] "Enumeration"  VMCU
 SG_ MaintReset_rqst_Request : 20|2@1+ (1,0) [0|0] ""  VMCU
 SG_ DPF_ManualRegenerateInhibit : 2|2@1+ (1,0) [0|0] ""  EMS
 SG_ Snooze_EventTimerReq_Oper : 51|3@1+ (1,0) [0|0] ""  VMCU
 SG_ BlackPanel_stat_ISig_4 : 0|2@1+ (1,0) [0|0] ""  VMCU,CIOM
 SG_ Snooze_EventTimerReq_Time : 30|21@1+ (1,0) [0|2097151] "s"  VMCU
 SG_ MaintReset_rqst_ID : 10|6@1+ (1,0) [0|63] "Enumeration"  VMCU
 SG_ PS_BlackPanelStatBtnInd_ISig_4 : 8|2@1+ (1,0) [0|0] ""  CIOM
 SG_ DPF_ManualRegenerateRequest : 4|2@1+ (1,0) [0|0] ""  EMS

BO_ 1344 HMIIOM_BB2_20S_FCM: 8 CIOM
 SG_ HMIIOM_BB2_20S_FCS : 0|64@1+ (1,0) [0|0] ""  IC3

BO_ 1343 HMIIOM_BB2_20S: 11 IC3
 SG_ ECU3VIN_stat : 0|88@1+ (1,0) [0|0] ""  CIOM

BO_ 1379 HMIIOM_BB2_19P_VMCU_FCM: 8 VMCU
 SG_ HMIIOM_BB2_19P_FCS_563 : 0|64@1+ (1,0) [0|0] ""  IC3

BO_ 1377 HMIIOM_BB2_19P_VMCU: 21 IC3
 SG_ GPSData_Longitude_ISig_4_561 : 0|32@1+ (1E-007,-210) [-210|219.4967295] "deg"  VMCU
 SG_ GPSData_sg_UB_ISig_4_561 : 163|1@1+ (1,0) [0|1] ""  VMCU
 SG_ GPSData_Direction_ISig_4_561 : 96|16@1+ (0.0078125,0) [0|511.9921875] "deg"  VMCU
 SG_ GPSData_Latitude_ISig_4_561 : 32|32@1+ (1E-007,-210) [-210|219.4967295] "deg"  VMCU
 SG_ GPSData_Altitude_ISig_4_561 : 144|16@1+ (0.125,-2500) [-2500|5691.875] "m"  VMCU
 SG_ GPSData_HDOP_ISig_4_561 : 112|16@1+ (0.01,0) [0|655.35] ""  VMCU
 SG_ GPSData_Time_ISig_4_561 : 64|32@1+ (1,0) [0|4294967295] "s"  VMCU
 SG_ GPSData_VehSpeed_ISig_4_561 : 128|16@1+ (0.00390625,0) [0|255.99609375] "Km_per_h"  VMCU
 SG_ GPSData_AntennaStat_ISig_4_561 : 160|3@1+ (1,0) [0|0] ""  VMCU

BO_ 1376 HMIIOM_BB2_19P_TECU_FCM: 8 TECU
 SG_ HMIIOM_BB2_19P_FCS_560 : 0|64@1+ (1,0) [0|0] ""  IC3

BO_ 1375 HMIIOM_BB2_19P_TECU: 21 IC3
 SG_ GPSData_HDOP_ISig_4_55f : 112|16@1+ (0.01,0) [0|655.35] ""  TECU
 SG_ GPSData_VehSpeed_ISig_4_55f : 128|16@1+ (0.00390625,0) [0|255.99609375] "Km_per_h"  TECU
 SG_ GPSData_Direction_ISig_4_55f : 96|16@1+ (0.0078125,0) [0|511.9921875] "deg"  TECU
 SG_ GPSData_Longitude_ISig_4_55f : 0|32@1+ (1E-007,-210) [-210|219.4967295] "deg"  TECU
 SG_ GPSData_sg_UB_ISig_4_55f : 163|1@1+ (1,0) [0|1] ""  TECU
 SG_ GPSData_Time_ISig_4_55f : 64|32@1+ (1,0) [0|4294967295] "s"  TECU
 SG_ GPSData_Latitude_ISig_4_55f : 32|32@1+ (1E-007,-210) [-210|219.4967295] "deg"  TECU
 SG_ GPSData_AntennaStat_ISig_4_55f : 160|3@1+ (1,0) [0|0] ""  TECU
 SG_ GPSData_Altitude_ISig_4_55f : 144|16@1+ (0.125,-2500) [-2500|5691.875] "m"  TECU

BO_ 1415 HMIIOM_BB2_19P_EMS_FCM: 8 EMS
 SG_ HMIIOM_BB2_19P_FCS_587 : 0|64@1+ (1,0) [0|0] ""  IC3

CM_ SG_ 1041 AvailableGearsWithLowerRatio "14 Error ; 15 Not available";
CM_ SG_ 1041 ClutchWearStatus "254 Error ; 255 Not available";
CM_ SG_ 1041 AvailableGearsWithHigherRatio "14 Error ; 15 Not available";
CM_ SG_ 516 RoadInclination_ISig_4 "254 Error ; 255 Not available";
CM_ BO_ 2365530173 "Request to reserve CANid from Powertrain (ACM ECU)";
CM_ BO_ 2365530429 "Request to reserve CANid from Powertrain (ACM ECU)";
CM_ BO_ 2671833696 "Note: old interface for HMIIOM, can be deleted when IC3 is configured with address 0x61.";
CM_ BO_ 2671796466 "Note: old interface for HMIIOM, can be deleted when IC3 is configured with address 0x61.";
CM_ SG_ 838 PresetIndicationCmd_ISig_4 "62 Error ; 63 Not Available";
CM_ SG_ 1422 FasLowSpeedReturnSetting_rqst_IS "21-29 spare
30 Error
31 NotAvailbale";
CM_ SG_ 1422 FasManualOffsetSetting_rqst_ISig "21-29 spare
30 Error
31 NotAvailbale";
CM_ SG_ 1422 FasStiffnessCurveSetting_rqst_IS "21-29 spare
30 Error
31 NotAvailbale";
CM_ SG_ 1422 FasStiffStraightSetting_rqst_ISi "21-29 spare
30 Error
31 NotAvailbale";
CM_ SG_ 1422 FasDampingSetting_rqst_ISig_4 "21-29 spare
30 Error
31 NotAvailbale";
CM_ SG_ 1377 GPSData_Longitude_ISig_4_561 "4261412864-4278190079 Error ; 4278190080-4294967295 Not available";
CM_ SG_ 1377 GPSData_Latitude_ISig_4_561 "4261412864-4278190079 Error ; 4278190080-4294967295 Not available";
CM_ SG_ 1377 GPSData_Time_ISig_4_561 "4261412864 - 4278190079 Error ; 4278190080 - 4294967295 Not available";
CM_ SG_ 1377 GPSData_VehSpeed_ISig_4_561 "65024 - 65279 Error ; 65280 - 65535 Not available";
CM_ SG_ 1375 GPSData_VehSpeed_ISig_4_55f "65024 - 65279 Error ; 65280 - 65535 Not available";
CM_ SG_ 1375 GPSData_Longitude_ISig_4_55f "4261412864-4278190079 Error ; 4278190080-4294967295 Not available";
CM_ SG_ 1375 GPSData_Time_ISig_4_55f "4261412864 - 4278190079 Error ; 4278190080 - 4294967295 Not available";
CM_ SG_ 1375 GPSData_Latitude_ISig_4_55f "4261412864-4278190079 Error ; 4278190080-4294967295 Not available";
BA_DEF_ BO_  "GenMsgStartDelayTime" INT 0 0;
BA_DEF_ BO_  "GenMsgDelayTime" INT 0 0;
BA_DEF_ BO_  "GenMsgCycleTime" INT 0 0;
BA_DEF_ BO_  "GenMsgSendType" ENUM  "Cyclic","NotUsed","NotUsed","NotUsed","NotUsed","NotUsed","NotUsed","IfActive","NoMsgSendType","NotUsed";
BA_DEF_ SG_  "GenSigStartValue" INT 0 0;
BA_DEF_ SG_  "GenSigCycleTimeActive" INT 0 0;
BA_DEF_ SG_  "GenSigCycleTime" INT 0 0;
BA_DEF_ SG_  "GenSigSendType" ENUM  "Cyclic","OnWrite","OnWriteWithRepetition","OnChange","OnChangeWithRepetition","IfActive","IfActiveWithRepetition","NoSigSendType","NotUsed","NotUsed","NotUsed","NotUsed","NotUsed";
BA_DEF_ BO_  "VFrameFormat" ENUM  "StandardCAN","ExtendedCAN","reserved","J1939PG","reserved","reserved","reserved","reserved","reserved","reserved","reserved","reserved","reserved","reserved","StandardCAN_FD","ExtendedCAN_FD";
BA_DEF_ SG_  "SigType" ENUM  "Default","Range","RangeSigned","ASCII","Discrete","Control","ReferencePGN","DTC","StringDelimiter","StringLength","StringLengthControl";
BA_DEF_ SG_  "SeToolVersion_SIGNAL" STRING ;
BA_DEF_ SG_  "SeToolUniqueID_SIGNAL" STRING ;
BA_DEF_ SG_  "SeToolOwnerSigGroup_SIGNAL" STRING ;
BA_DEF_ SG_  "SeToolOwnerSigGroupID_SIGNAL" STRING ;
BA_DEF_ SG_  "SeToolName_SIGNAL" STRING ;
BA_DEF_ SG_  "SeToolItemID_SIGNAL" STRING ;
BA_DEF_ SG_  "SeToolAncestorID_SIGNAL" STRING ;
BA_DEF_ SG_  "Platform_VMCU1_Sig" ENUM  "No","Yes";
BA_DEF_ SG_  "Platform_FactoryIf_Sig" ENUM  "No","Yes";
BA_DEF_ BO_  "NmAsrMessage" ENUM  "No","Yes";
BA_DEF_ SG_  "NeedsUpdateBit" ENUM  "No","Yes";
BA_DEF_ SG_  "MmAnSignal" ENUM  "No","Yes";
BA_DEF_ SG_  "GenSigMaxLatency" INT 0 65535;
BA_DEF_ SG_  "GenSigILSupport" ENUM  "Yes","No";
BA_DEF_ BO_  "GenMsgILSupport" ENUM  "No","Yes";
BA_DEF_ BO_  "DiagUUDTResponse" ENUM  "No","Yes";
BA_DEF_ BO_  "DiagState" ENUM  "No","Yes";
BA_DEF_ BO_  "DiagResponse" ENUM  "No","Yes";
BA_DEF_ BO_  "DiagRequest" ENUM  "No","Yes";
BA_DEF_ BO_  "DiagConnection" HEX 0 65535;
BA_DEF_ BO_  "CanTpSTmin" INT 0 255;
BA_DEF_ BO_  "CanTpFcFrameId" HEX 0 2147483647;
BA_DEF_ BO_  "CanTpBs" INT 0 255;
BA_DEF_ SG_  "SystemSignalLongSymbol" STRING ;
BA_DEF_REL_ BU_SG_REL_  "GenSigTimeoutTime" INT 0 65535;
BA_DEF_REL_ BU_SG_REL_  "GenSigFirstTimeoutTime" INT 0 65535;
BA_DEF_DEF_  "GenMsgStartDelayTime" 0;
BA_DEF_DEF_  "GenMsgDelayTime" 0;
BA_DEF_DEF_  "GenMsgCycleTime" 0;
BA_DEF_DEF_  "GenMsgSendType" "Cyclic";
BA_DEF_DEF_  "GenSigStartValue" 0;
BA_DEF_DEF_  "GenSigCycleTimeActive" 0;
BA_DEF_DEF_  "GenSigCycleTime" 0;
BA_DEF_DEF_  "GenSigSendType" "Cyclic";
BA_DEF_DEF_  "VFrameFormat" "ExtendedCAN";
BA_DEF_DEF_  "SigType" "Default";
BA_DEF_DEF_  "SeToolVersion_SIGNAL" "";
BA_DEF_DEF_  "SeToolUniqueID_SIGNAL" "";
BA_DEF_DEF_  "SeToolOwnerSigGroup_SIGNAL" "";
BA_DEF_DEF_  "SeToolOwnerSigGroupID_SIGNAL" "";
BA_DEF_DEF_  "SeToolName_SIGNAL" "";
BA_DEF_DEF_  "SeToolItemID_SIGNAL" "";
BA_DEF_DEF_  "SeToolAncestorID_SIGNAL" "";
BA_DEF_DEF_  "Platform_VMCU1_Sig" "No";
BA_DEF_DEF_  "Platform_FactoryIf_Sig" "No";
BA_DEF_DEF_  "NmAsrMessage" "No";
BA_DEF_DEF_  "NeedsUpdateBit" "No";
BA_DEF_DEF_  "MmAnSignal" "No";
BA_DEF_DEF_  "GenSigMaxLatency" 0;
BA_DEF_DEF_  "GenSigILSupport" "Yes";
BA_DEF_DEF_  "GenMsgILSupport" "Yes";
BA_DEF_DEF_  "DiagUUDTResponse" "No";
BA_DEF_DEF_  "DiagState" "No";
BA_DEF_DEF_  "DiagResponse" "No";
BA_DEF_DEF_  "DiagRequest" "No";
BA_DEF_DEF_  "DiagConnection" 0;
BA_DEF_DEF_  "CanTpSTmin" 0;
BA_DEF_DEF_  "CanTpFcFrameId" 2147483647;
BA_DEF_DEF_  "CanTpBs" 255;
BA_DEF_DEF_REL_ "GenSigTimeoutTime" 0;
BA_DEF_DEF_REL_ "GenSigFirstTimeoutTime" 0;
BA_DEF_DEF_  "SystemSignalLongSymbol" "";
BA_ "VFrameFormat" BO_ 1041 0;
BA_ "GenMsgCycleTime" BO_ 1041 100;
BA_ "GenMsgStartDelayTime" BO_ 1041 10;
BA_ "VFrameFormat" BO_ 516 0;
BA_ "GenMsgCycleTime" BO_ 516 25;
BA_ "GenMsgStartDelayTime" BO_ 516 5;
BA_ "VFrameFormat" BO_ 1792 0;
BA_ "DiagConnection" BO_ 2671834660 63012;
BA_ "DiagResponse" BO_ 2671834660 1;
BA_ "GenMsgILSupport" BO_ 2671834660 0;
BA_ "GenMsgSendType" BO_ 2671834660 8;
BA_ "DiagConnection" BO_ 2671834640 62992;
BA_ "DiagResponse" BO_ 2671834640 1;
BA_ "GenMsgILSupport" BO_ 2671834640 0;
BA_ "GenMsgSendType" BO_ 2671834640 8;
BA_ "DiagConnection" BO_ 2671833839 62191;
BA_ "DiagResponse" BO_ 2671833839 1;
BA_ "GenMsgILSupport" BO_ 2671833839 0;
BA_ "GenMsgSendType" BO_ 2671833839 8;
BA_ "DiagConnection" BO_ 2671833830 62182;
BA_ "DiagResponse" BO_ 2671833830 1;
BA_ "GenMsgILSupport" BO_ 2671833830 0;
BA_ "GenMsgSendType" BO_ 2671833830 8;
BA_ "DiagConnection" BO_ 2671833829 62181;
BA_ "DiagResponse" BO_ 2671833829 1;
BA_ "GenMsgILSupport" BO_ 2671833829 0;
BA_ "GenMsgSendType" BO_ 2671833829 8;
BA_ "DiagConnection" BO_ 2671833794 62146;
BA_ "DiagResponse" BO_ 2671833794 1;
BA_ "GenMsgILSupport" BO_ 2671833794 0;
BA_ "GenMsgSendType" BO_ 2671833794 8;
BA_ "DiagConnection" BO_ 2671833792 62144;
BA_ "DiagResponse" BO_ 2671833792 1;
BA_ "GenMsgILSupport" BO_ 2671833792 0;
BA_ "GenMsgSendType" BO_ 2671833792 8;
BA_ "DiagConnection" BO_ 2671833762 62114;
BA_ "DiagResponse" BO_ 2671833762 1;
BA_ "GenMsgILSupport" BO_ 2671833762 0;
BA_ "GenMsgSendType" BO_ 2671833762 8;
BA_ "DiagConnection" BO_ 2671833761 62113;
BA_ "DiagResponse" BO_ 2671833761 1;
BA_ "GenMsgILSupport" BO_ 2671833761 0;
BA_ "GenMsgSendType" BO_ 2671833761 8;
BA_ "DiagConnection" BO_ 2671833760 62112;
BA_ "DiagResponse" BO_ 2671833760 1;
BA_ "GenMsgILSupport" BO_ 2671833760 0;
BA_ "GenMsgSendType" BO_ 2671833760 8;
BA_ "DiagConnection" BO_ 2671833752 62104;
BA_ "DiagResponse" BO_ 2671833752 1;
BA_ "GenMsgILSupport" BO_ 2671833752 0;
BA_ "GenMsgSendType" BO_ 2671833752 8;
BA_ "DiagConnection" BO_ 2671833740 62092;
BA_ "DiagResponse" BO_ 2671833740 1;
BA_ "GenMsgILSupport" BO_ 2671833740 0;
BA_ "GenMsgSendType" BO_ 2671833740 8;
BA_ "DiagConnection" BO_ 2671833731 62083;
BA_ "DiagResponse" BO_ 2671833731 1;
BA_ "GenMsgILSupport" BO_ 2671833731 0;
BA_ "GenMsgSendType" BO_ 2671833731 8;
BA_ "DiagConnection" BO_ 2671833730 62082;
BA_ "DiagResponse" BO_ 2671833730 1;
BA_ "GenMsgILSupport" BO_ 2671833730 0;
BA_ "GenMsgSendType" BO_ 2671833730 8;
BA_ "DiagConnection" BO_ 2671833700 62052;
BA_ "DiagResponse" BO_ 2671833700 1;
BA_ "GenMsgILSupport" BO_ 2671833700 0;
BA_ "GenMsgSendType" BO_ 2671833700 8;
BA_ "DiagConnection" BO_ 2671833697 62049;
BA_ "DiagResponse" BO_ 2671833697 1;
BA_ "GenMsgILSupport" BO_ 2671833697 0;
BA_ "GenMsgSendType" BO_ 2671833697 8;
BA_ "DiagConnection" BO_ 2671833696 62048;
BA_ "DiagResponse" BO_ 2671833696 1;
BA_ "GenMsgILSupport" BO_ 2671833696 0;
BA_ "GenMsgSendType" BO_ 2671833696 8;
BA_ "DiagConnection" BO_ 2671833683 62035;
BA_ "DiagResponse" BO_ 2671833683 1;
BA_ "GenMsgILSupport" BO_ 2671833683 0;
BA_ "GenMsgSendType" BO_ 2671833683 8;
BA_ "DiagConnection" BO_ 2671833682 62034;
BA_ "DiagResponse" BO_ 2671833682 1;
BA_ "GenMsgILSupport" BO_ 2671833682 0;
BA_ "GenMsgSendType" BO_ 2671833682 8;
BA_ "DiagConnection" BO_ 2671833681 62033;
BA_ "DiagResponse" BO_ 2671833681 1;
BA_ "GenMsgILSupport" BO_ 2671833681 0;
BA_ "GenMsgSendType" BO_ 2671833681 8;
BA_ "DiagConnection" BO_ 2671833680 62032;
BA_ "DiagResponse" BO_ 2671833680 1;
BA_ "GenMsgILSupport" BO_ 2671833680 0;
BA_ "GenMsgSendType" BO_ 2671833680 8;
BA_ "DiagConnection" BO_ 2671833665 62017;
BA_ "DiagResponse" BO_ 2671833665 1;
BA_ "GenMsgILSupport" BO_ 2671833665 0;
BA_ "GenMsgSendType" BO_ 2671833665 8;
BA_ "DiagConnection" BO_ 2671833664 62016;
BA_ "DiagResponse" BO_ 2671833664 1;
BA_ "GenMsgILSupport" BO_ 2671833664 0;
BA_ "GenMsgSendType" BO_ 2671833664 8;
BA_ "DiagConnection" BO_ 2671833638 61990;
BA_ "DiagResponse" BO_ 2671833638 1;
BA_ "GenMsgILSupport" BO_ 2671833638 0;
BA_ "GenMsgSendType" BO_ 2671833638 8;
BA_ "DiagConnection" BO_ 2671833624 61976;
BA_ "DiagResponse" BO_ 2671833624 1;
BA_ "GenMsgILSupport" BO_ 2671833624 0;
BA_ "GenMsgSendType" BO_ 2671833624 8;
BA_ "DiagConnection" BO_ 2671833616 61968;
BA_ "DiagResponse" BO_ 2671833616 1;
BA_ "GenMsgILSupport" BO_ 2671833616 0;
BA_ "GenMsgSendType" BO_ 2671833616 8;
BA_ "DiagConnection" BO_ 2564485459 61779;
BA_ "DiagResponse" BO_ 2564485459 1;
BA_ "GenMsgILSupport" BO_ 2564485459 0;
BA_ "GenMsgSendType" BO_ 2564485459 8;
BA_ "DiagConnection" BO_ 2564485392 63504;
BA_ "DiagResponse" BO_ 2564485392 1;
BA_ "GenMsgILSupport" BO_ 2564485392 0;
BA_ "GenMsgSendType" BO_ 2564485392 8;
BA_ "DiagConnection" BO_ 2671833360 61712;
BA_ "DiagResponse" BO_ 2671833360 1;
BA_ "GenMsgILSupport" BO_ 2671833360 0;
BA_ "GenMsgSendType" BO_ 2671833360 8;
BA_ "DiagConnection" BO_ 2671833074 62191;
BA_ "DiagRequest" BO_ 2671833074 1;
BA_ "GenMsgILSupport" BO_ 2671833074 0;
BA_ "GenMsgSendType" BO_ 2671833074 8;
BA_ "DiagConnection" BO_ 2671830770 62182;
BA_ "DiagRequest" BO_ 2671830770 1;
BA_ "GenMsgILSupport" BO_ 2671830770 0;
BA_ "GenMsgSendType" BO_ 2671830770 8;
BA_ "DiagConnection" BO_ 2671830514 62181;
BA_ "DiagRequest" BO_ 2671830514 1;
BA_ "GenMsgILSupport" BO_ 2671830514 0;
BA_ "GenMsgSendType" BO_ 2671830514 8;
BA_ "DiagConnection" BO_ 2671821554 62146;
BA_ "DiagRequest" BO_ 2671821554 1;
BA_ "GenMsgILSupport" BO_ 2671821554 0;
BA_ "GenMsgSendType" BO_ 2671821554 8;
BA_ "DiagConnection" BO_ 2671821042 62144;
BA_ "DiagRequest" BO_ 2671821042 1;
BA_ "GenMsgILSupport" BO_ 2671821042 0;
BA_ "GenMsgSendType" BO_ 2671821042 8;
BA_ "DiagConnection" BO_ 2671813362 62114;
BA_ "DiagRequest" BO_ 2671813362 1;
BA_ "GenMsgILSupport" BO_ 2671813362 0;
BA_ "GenMsgSendType" BO_ 2671813362 8;
BA_ "DiagConnection" BO_ 2671813106 62113;
BA_ "DiagRequest" BO_ 2671813106 1;
BA_ "GenMsgILSupport" BO_ 2671813106 0;
BA_ "GenMsgSendType" BO_ 2671813106 8;
BA_ "DiagConnection" BO_ 2671812850 62112;
BA_ "DiagRequest" BO_ 2671812850 1;
BA_ "GenMsgILSupport" BO_ 2671812850 0;
BA_ "GenMsgSendType" BO_ 2671812850 8;
BA_ "DiagConnection" BO_ 2671810802 62104;
BA_ "DiagRequest" BO_ 2671810802 1;
BA_ "GenMsgILSupport" BO_ 2671810802 0;
BA_ "GenMsgSendType" BO_ 2671810802 8;
BA_ "DiagConnection" BO_ 2671807730 62092;
BA_ "DiagRequest" BO_ 2671807730 1;
BA_ "GenMsgILSupport" BO_ 2671807730 0;
BA_ "GenMsgSendType" BO_ 2671807730 8;
BA_ "DiagConnection" BO_ 2671805426 62083;
BA_ "DiagRequest" BO_ 2671805426 1;
BA_ "GenMsgILSupport" BO_ 2671805426 0;
BA_ "GenMsgSendType" BO_ 2671805426 8;
BA_ "DiagConnection" BO_ 2671805170 62082;
BA_ "DiagRequest" BO_ 2671805170 1;
BA_ "GenMsgILSupport" BO_ 2671805170 0;
BA_ "GenMsgSendType" BO_ 2671805170 8;
BA_ "DiagConnection" BO_ 2671797490 62052;
BA_ "DiagRequest" BO_ 2671797490 1;
BA_ "GenMsgILSupport" BO_ 2671797490 0;
BA_ "GenMsgSendType" BO_ 2671797490 8;
BA_ "DiagConnection" BO_ 2671796722 62049;
BA_ "DiagRequest" BO_ 2671796722 1;
BA_ "GenMsgILSupport" BO_ 2671796722 0;
BA_ "GenMsgSendType" BO_ 2671796722 8;
BA_ "DiagConnection" BO_ 2671796466 62048;
BA_ "DiagRequest" BO_ 2671796466 1;
BA_ "GenMsgILSupport" BO_ 2671796466 0;
BA_ "GenMsgSendType" BO_ 2671796466 8;
BA_ "DiagConnection" BO_ 2671793138 62035;
BA_ "DiagRequest" BO_ 2671793138 1;
BA_ "GenMsgILSupport" BO_ 2671793138 0;
BA_ "GenMsgSendType" BO_ 2671793138 8;
BA_ "DiagConnection" BO_ 2564445169 61779;
BA_ "DiagRequest" BO_ 2564445169 1;
BA_ "GenMsgILSupport" BO_ 2564445169 0;
BA_ "GenMsgSendType" BO_ 2564445169 8;
BA_ "DiagConnection" BO_ 2671792882 62034;
BA_ "DiagRequest" BO_ 2671792882 1;
BA_ "GenMsgILSupport" BO_ 2671792882 0;
BA_ "GenMsgSendType" BO_ 2671792882 8;
BA_ "DiagConnection" BO_ 2671792626 62033;
BA_ "DiagRequest" BO_ 2671792626 1;
BA_ "GenMsgILSupport" BO_ 2671792626 0;
BA_ "GenMsgSendType" BO_ 2671792626 8;
BA_ "DiagConnection" BO_ 2671792370 62032;
BA_ "DiagRequest" BO_ 2671792370 1;
BA_ "GenMsgILSupport" BO_ 2671792370 0;
BA_ "GenMsgSendType" BO_ 2671792370 8;
BA_ "DiagConnection" BO_ 2671788530 62017;
BA_ "DiagRequest" BO_ 2671788530 1;
BA_ "GenMsgILSupport" BO_ 2671788530 0;
BA_ "GenMsgSendType" BO_ 2671788530 8;
BA_ "DiagConnection" BO_ 2671788274 62016;
BA_ "DiagRequest" BO_ 2671788274 1;
BA_ "GenMsgILSupport" BO_ 2671788274 0;
BA_ "GenMsgSendType" BO_ 2671788274 8;
BA_ "DiagConnection" BO_ 2671781618 61990;
BA_ "DiagRequest" BO_ 2671781618 1;
BA_ "GenMsgILSupport" BO_ 2671781618 0;
BA_ "GenMsgSendType" BO_ 2671781618 8;
BA_ "DiagConnection" BO_ 2671781110 63012;
BA_ "DiagRequest" BO_ 2671781110 1;
BA_ "GenMsgILSupport" BO_ 2671781110 0;
BA_ "GenMsgSendType" BO_ 2671781110 8;
BA_ "DiagConnection" BO_ 2671778034 61976;
BA_ "DiagRequest" BO_ 2671778034 1;
BA_ "GenMsgILSupport" BO_ 2671778034 0;
BA_ "GenMsgSendType" BO_ 2671778034 8;
BA_ "DiagConnection" BO_ 2671775990 62992;
BA_ "DiagRequest" BO_ 2671775990 1;
BA_ "GenMsgILSupport" BO_ 2671775990 0;
BA_ "GenMsgSendType" BO_ 2671775990 8;
BA_ "DiagConnection" BO_ 2671775986 61968;
BA_ "DiagRequest" BO_ 2671775986 1;
BA_ "GenMsgILSupport" BO_ 2671775986 0;
BA_ "GenMsgSendType" BO_ 2671775986 8;
BA_ "DiagConnection" BO_ 2564428017 63504;
BA_ "DiagRequest" BO_ 2564428017 1;
BA_ "GenMsgILSupport" BO_ 2564428017 0;
BA_ "GenMsgSendType" BO_ 2564428017 8;
BA_ "DiagConnection" BO_ 2671775985 61712;
BA_ "DiagRequest" BO_ 2671775985 1;
BA_ "GenMsgILSupport" BO_ 2671775985 0;
BA_ "GenMsgSendType" BO_ 2671775985 8;
BA_ "DiagConnection" BO_ 2564502513 63504;
BA_ "DiagState" BO_ 2564502513 1;
BA_ "GenMsgILSupport" BO_ 2564502513 0;
BA_ "GenMsgSendType" BO_ 2564502513 8;
BA_ "DiagConnection" BO_ 2671850481 61712;
BA_ "DiagState" BO_ 2671850481 1;
BA_ "GenMsgILSupport" BO_ 2671850481 0;
BA_ "GenMsgSendType" BO_ 2671850481 8;
BA_ "DiagConnection" BO_ 2671850486 62992;
BA_ "DiagState" BO_ 2671850486 1;
BA_ "GenMsgILSupport" BO_ 2671850486 0;
BA_ "GenMsgSendType" BO_ 2671850486 8;
BA_ "GenMsgILSupport" BO_ 2633990180 0;
BA_ "NmAsrMessage" BO_ 2633990180 1;
BA_ "GenMsgSendType" BO_ 2633990180 8;
BA_ "GenMsgILSupport" BO_ 2633990168 0;
BA_ "NmAsrMessage" BO_ 2633990168 1;
BA_ "GenMsgSendType" BO_ 2633990168 8;
BA_ "GenMsgILSupport" BO_ 2633990383 0;
BA_ "NmAsrMessage" BO_ 2633990383 1;
BA_ "GenMsgSendType" BO_ 2633990383 8;
BA_ "GenMsgILSupport" BO_ 2633990240 0;
BA_ "NmAsrMessage" BO_ 2633990240 1;
BA_ "GenMsgSendType" BO_ 2633990240 8;
BA_ "GenMsgILSupport" BO_ 2633990160 0;
BA_ "NmAsrMessage" BO_ 2633990160 1;
BA_ "GenMsgSendType" BO_ 2633990160 8;
BA_ "GenMsgILSupport" BO_ 2633990224 0;
BA_ "NmAsrMessage" BO_ 2633990224 1;
BA_ "GenMsgSendType" BO_ 2633990224 8;
BA_ "GenMsgILSupport" BO_ 2633990208 0;
BA_ "NmAsrMessage" BO_ 2633990208 1;
BA_ "GenMsgSendType" BO_ 2633990208 8;
BA_ "GenMsgILSupport" BO_ 2633990374 0;
BA_ "NmAsrMessage" BO_ 2633990374 1;
BA_ "GenMsgSendType" BO_ 2633990374 8;
BA_ "DiagConnection" BO_ 2671902708 62468;
BA_ "DiagState" BO_ 2671902708 1;
BA_ "GenMsgILSupport" BO_ 2671902708 0;
BA_ "GenMsgSendType" BO_ 2671902708 8;
BA_ "VFrameFormat" BO_ 1280 0;
BA_ "GenMsgCycleTime" BO_ 1280 500;
BA_ "GenMsgStartDelayTime" BO_ 1280 125;
BA_ "VFrameFormat" BO_ 1129 0;
BA_ "GenMsgCycleTime" BO_ 1129 150;
BA_ "GenMsgILSupport" BO_ 1395 0;
BA_ "VFrameFormat" BO_ 1395 0;
BA_ "GenMsgSendType" BO_ 1395 8;
BA_ "CanTpFcFrameId" BO_ 1394 1395;
BA_ "VFrameFormat" BO_ 1394 0;
BA_ "GenMsgSendType" BO_ 1394 8;
BA_ "GenMsgDelayTime" BO_ 1394 150;
BA_ "GenMsgStartDelayTime" BO_ 1394 50;
BA_ "GenMsgILSupport" BO_ 1444 0;
BA_ "VFrameFormat" BO_ 1444 0;
BA_ "GenMsgSendType" BO_ 1444 8;
BA_ "CanTpFcFrameId" BO_ 1443 1444;
BA_ "VFrameFormat" BO_ 1443 0;
BA_ "GenMsgSendType" BO_ 1443 8;
BA_ "GenMsgDelayTime" BO_ 1443 200;
BA_ "VFrameFormat" BO_ 1214 0;
BA_ "GenMsgSendType" BO_ 1214 8;
BA_ "GenMsgDelayTime" BO_ 1214 200;
BA_ "VFrameFormat" BO_ 1256 0;
BA_ "GenMsgSendType" BO_ 1256 8;
BA_ "GenMsgDelayTime" BO_ 1256 200;
BA_ "VFrameFormat" BO_ 839 0;
BA_ "GenMsgCycleTime" BO_ 839 250;
BA_ "GenMsgStartDelayTime" BO_ 839 20;
BA_ "VFrameFormat" BO_ 838 0;
BA_ "GenMsgCycleTime" BO_ 838 50;
BA_ "GenMsgStartDelayTime" BO_ 838 10;
BA_ "VFrameFormat" BO_ 515 0;
BA_ "GenMsgSendType" BO_ 515 8;
BA_ "GenMsgStartDelayTime" BO_ 515 20;
BA_ "VFrameFormat" BO_ 1306 0;
BA_ "GenMsgCycleTime" BO_ 1306 500;
BA_ "GenMsgStartDelayTime" BO_ 1306 10;
BA_ "VFrameFormat" BO_ 1363 0;
BA_ "GenMsgCycleTime" BO_ 1363 1000;
BA_ "GenMsgStartDelayTime" BO_ 1363 25;
BA_ "VFrameFormat" BO_ 1110 0;
BA_ "GenMsgCycleTime" BO_ 1110 100;
BA_ "GenMsgStartDelayTime" BO_ 1110 5;
BA_ "CanTpSTmin" BO_ 1477 5;
BA_ "GenMsgILSupport" BO_ 1477 0;
BA_ "VFrameFormat" BO_ 1477 0;
BA_ "GenMsgSendType" BO_ 1477 8;
BA_ "VFrameFormat" BO_ 1422 0;
BA_ "GenMsgCycleTime" BO_ 1422 1000;
BA_ "GenMsgStartDelayTime" BO_ 1422 50;
BA_ "VFrameFormat" BO_ 1421 0;
BA_ "GenMsgCycleTime" BO_ 1421 100;
BA_ "GenMsgStartDelayTime" BO_ 1421 50;
BA_ "VFrameFormat" BO_ 518 0;
BA_ "GenMsgSendType" BO_ 518 8;
BA_ "GenMsgDelayTime" BO_ 518 20;
BA_ "GenMsgILSupport" BO_ 1397 0;
BA_ "VFrameFormat" BO_ 1397 0;
BA_ "GenMsgSendType" BO_ 1397 8;
BA_ "CanTpFcFrameId" BO_ 1396 1397;
BA_ "VFrameFormat" BO_ 1396 0;
BA_ "GenMsgSendType" BO_ 1396 8;
BA_ "GenMsgDelayTime" BO_ 1396 150;
BA_ "GenMsgILSupport" BO_ 952 0;
BA_ "VFrameFormat" BO_ 952 0;
BA_ "GenMsgSendType" BO_ 952 8;
BA_ "CanTpFcFrameId" BO_ 949 952;
BA_ "VFrameFormat" BO_ 949 0;
BA_ "GenMsgSendType" BO_ 949 8;
BA_ "GenMsgDelayTime" BO_ 949 100;
BA_ "VFrameFormat" BO_ 967 0;
BA_ "GenMsgSendType" BO_ 967 8;
BA_ "GenMsgDelayTime" BO_ 967 50;
BA_ "VFrameFormat" BO_ 822 0;
BA_ "GenMsgCycleTime" BO_ 822 50;
BA_ "GenMsgStartDelayTime" BO_ 822 25;
BA_ "VFrameFormat" BO_ 1337 0;
BA_ "GenMsgCycleTime" BO_ 1337 500;
BA_ "GenMsgStartDelayTime" BO_ 1337 285;
BA_ "VFrameFormat" BO_ 1336 0;
BA_ "GenMsgCycleTime" BO_ 1336 500;
BA_ "GenMsgStartDelayTime" BO_ 1336 100;
BA_ "CanTpFcFrameId" BO_ 1476 1477;
BA_ "CanTpSTmin" BO_ 1476 5;
BA_ "VFrameFormat" BO_ 1476 0;
BA_ "GenMsgSendType" BO_ 1476 8;
BA_ "GenMsgDelayTime" BO_ 1476 2400;
BA_ "GenMsgStartDelayTime" BO_ 1476 50;
BA_ "VFrameFormat" BO_ 837 0;
BA_ "GenMsgCycleTime" BO_ 837 50;
BA_ "VFrameFormat" BO_ 1056 0;
BA_ "GenMsgCycleTime" BO_ 1056 150;
BA_ "GenMsgStartDelayTime" BO_ 1056 35;
BA_ "VFrameFormat" BO_ 1334 0;
BA_ "GenMsgCycleTime" BO_ 1334 500;
BA_ "GenMsgDelayTime" BO_ 1334 100;
BA_ "GenMsgStartDelayTime" BO_ 1334 250;
BA_ "GenMsgILSupport" BO_ 1344 0;
BA_ "VFrameFormat" BO_ 1344 0;
BA_ "GenMsgSendType" BO_ 1344 8;
BA_ "CanTpFcFrameId" BO_ 1343 1344;
BA_ "VFrameFormat" BO_ 1343 0;
BA_ "GenMsgSendType" BO_ 1343 8;
BA_ "GenMsgDelayTime" BO_ 1343 110;
BA_ "GenMsgStartDelayTime" BO_ 1343 50;
BA_ "GenMsgILSupport" BO_ 1379 0;
BA_ "VFrameFormat" BO_ 1379 0;
BA_ "GenMsgSendType" BO_ 1379 8;
BA_ "CanTpFcFrameId" BO_ 1377 1379;
BA_ "VFrameFormat" BO_ 1377 0;
BA_ "GenMsgSendType" BO_ 1377 8;
BA_ "GenMsgDelayTime" BO_ 1377 50;
BA_ "GenMsgStartDelayTime" BO_ 1377 5;
BA_ "GenMsgILSupport" BO_ 1376 0;
BA_ "VFrameFormat" BO_ 1376 0;
BA_ "GenMsgSendType" BO_ 1376 8;
BA_ "CanTpFcFrameId" BO_ 1375 1376;
BA_ "VFrameFormat" BO_ 1375 0;
BA_ "GenMsgSendType" BO_ 1375 8;
BA_ "GenMsgDelayTime" BO_ 1375 50;
BA_ "GenMsgStartDelayTime" BO_ 1375 5;
BA_ "GenMsgILSupport" BO_ 1415 0;
BA_ "VFrameFormat" BO_ 1415 0;
BA_ "GenMsgSendType" BO_ 1415 8;
BA_ "GenSigCycleTime" SG_ 1041 GearShiftingRec_Steps 100;
BA_ "GenSigCycleTimeActive" SG_ 1041 GearShiftingRec_Steps 100;
BA_ "GenSigStartValue" SG_ 1041 GearShiftingRec_Steps 7;
BA_ "GenSigCycleTime" SG_ 1041 GearShiftingRec_Direction 100;
BA_ "GenSigCycleTimeActive" SG_ 1041 GearShiftingRec_Direction 100;
BA_ "GenSigStartValue" SG_ 1041 GearShiftingRec_Direction 7;
BA_ "GenSigCycleTime" SG_ 1041 BrakeInterlockStatus 100;
BA_ "GenSigCycleTimeActive" SG_ 1041 BrakeInterlockStatus 100;
BA_ "Platform_VMCU1_Sig" SG_ 1041 BrakeInterlockStatus 1;
BA_ "GenSigCycleTime" SG_ 1041 AutGearSplitPosition_ISig_4 100;
BA_ "GenSigCycleTimeActive" SG_ 1041 AutGearSplitPosition_ISig_4 100;
BA_ "GenSigStartValue" SG_ 1041 AutGearSplitPosition_ISig_4 7;
BA_ "Platform_VMCU1_Sig" SG_ 1041 AutGearSplitPosition_ISig_4 1;
BA_ "GenSigCycleTime" SG_ 1041 TransmissionBrakeMode 100;
BA_ "GenSigCycleTimeActive" SG_ 1041 TransmissionBrakeMode 100;
BA_ "GenSigStartValue" SG_ 1041 TransmissionBrakeMode 3;
BA_ "GenSigCycleTime" SG_ 1041 AvailableGearsWithLowerRatio 100;
BA_ "GenSigCycleTimeActive" SG_ 1041 AvailableGearsWithLowerRatio 100;
BA_ "GenSigStartValue" SG_ 1041 AvailableGearsWithLowerRatio 15;
BA_ "GenSigMaxLatency" SG_ 1041 AvailableGearsWithLowerRatio 26;
BA_ "Platform_VMCU1_Sig" SG_ 1041 AvailableGearsWithLowerRatio 1;
BA_ "SeToolAncestorID_SIGNAL" SG_ 1041 AvailableGearsWithLowerRatio "x0000001D0416F544";
BA_ "SeToolItemID_SIGNAL" SG_ 1041 AvailableGearsWithLowerRatio "x0000001D0436DC28";
BA_ "SeToolName_SIGNAL" SG_ 1041 AvailableGearsWithLowerRatio "NumberOfAvailableGearsWithLowerRatio";
BA_ "SeToolVersion_SIGNAL" SG_ 1041 AvailableGearsWithLowerRatio "2";
BA_ "GenSigCycleTime" SG_ 1041 FuelEcoDrvStatus 100;
BA_ "GenSigCycleTimeActive" SG_ 1041 FuelEcoDrvStatus 100;
BA_ "GenSigStartValue" SG_ 1041 FuelEcoDrvStatus 3;
BA_ "Platform_VMCU1_Sig" SG_ 1041 FuelEcoDrvStatus 1;
BA_ "GenSigCycleTime" SG_ 1041 EcoCruiseStatus_ISig_4 100;
BA_ "GenSigCycleTimeActive" SG_ 1041 EcoCruiseStatus_ISig_4 100;
BA_ "GenSigStartValue" SG_ 1041 EcoCruiseStatus_ISig_4 7;
BA_ "Platform_VMCU1_Sig" SG_ 1041 EcoCruiseStatus_ISig_4 1;
BA_ "GenSigCycleTime" SG_ 1041 TransmissionDrivingMode_ISig_4 100;
BA_ "GenSigCycleTimeActive" SG_ 1041 TransmissionDrivingMode_ISig_4 100;
BA_ "GenSigStartValue" SG_ 1041 TransmissionDrivingMode_ISig_4 7;
BA_ "GenSigCycleTime" SG_ 1041 ClutchWearStatus 100;
BA_ "GenSigCycleTimeActive" SG_ 1041 ClutchWearStatus 100;
BA_ "GenSigStartValue" SG_ 1041 ClutchWearStatus 255;
BA_ "GenSigMaxLatency" SG_ 1041 ClutchWearStatus 26;
BA_ "Platform_VMCU1_Sig" SG_ 1041 ClutchWearStatus 1;
BA_ "SeToolAncestorID_SIGNAL" SG_ 1041 ClutchWearStatus "x0000001D0419DCE7";
BA_ "SeToolItemID_SIGNAL" SG_ 1041 ClutchWearStatus "x0000001D0419DCE7";
BA_ "SeToolName_SIGNAL" SG_ 1041 ClutchWearStatus "ClutchWearStatus";
BA_ "SeToolVersion_SIGNAL" SG_ 1041 ClutchWearStatus "1";
BA_ "GenSigCycleTime" SG_ 1041 AutoWheelBrakeInhibited 100;
BA_ "GenSigCycleTimeActive" SG_ 1041 AutoWheelBrakeInhibited 100;
BA_ "GenSigStartValue" SG_ 1041 AutoWheelBrakeInhibited 3;
BA_ "Platform_VMCU1_Sig" SG_ 1041 AutoWheelBrakeInhibited 1;
BA_ "GenSigCycleTime" SG_ 1041 DrivingMode_ISig_4 100;
BA_ "GenSigCycleTimeActive" SG_ 1041 DrivingMode_ISig_4 100;
BA_ "GenSigMaxLatency" SG_ 1041 DrivingMode_ISig_4 26;
BA_ "Platform_VMCU1_Sig" SG_ 1041 DrivingMode_ISig_4 1;
BA_ "SigType" SG_ 1041 DrivingMode_ISig_4 3;
BA_ "SeToolAncestorID_SIGNAL" SG_ 1041 DrivingMode_ISig_4 "x0000001D0413D7DC";
BA_ "SeToolItemID_SIGNAL" SG_ 1041 DrivingMode_ISig_4 "x0000001D0435EBD7";
BA_ "SeToolName_SIGNAL" SG_ 1041 DrivingMode_ISig_4 "DrivingMode";
BA_ "SeToolVersion_SIGNAL" SG_ 1041 DrivingMode_ISig_4 "4";
BA_ "GenSigCycleTime" SG_ 1041 AutoWheelBrakesDownshiftSugges 100;
BA_ "GenSigCycleTimeActive" SG_ 1041 AutoWheelBrakesDownshiftSugges 100;
BA_ "GenSigStartValue" SG_ 1041 AutoWheelBrakesDownshiftSugges 3;
BA_ "GenSigCycleTime" SG_ 1041 TransmissionOilTempHigh_ISig_4 100;
BA_ "GenSigCycleTimeActive" SG_ 1041 TransmissionOilTempHigh_ISig_4 100;
BA_ "GenSigStartValue" SG_ 1041 TransmissionOilTempHigh_ISig_4 7;
BA_ "GenSigMaxLatency" SG_ 1041 TransmissionOilTempHigh_ISig_4 26;
BA_ "Platform_VMCU1_Sig" SG_ 1041 TransmissionOilTempHigh_ISig_4 1;
BA_ "SeToolAncestorID_SIGNAL" SG_ 1041 TransmissionOilTempHigh_ISig_4 "x0000001D0415A8B5";
BA_ "SeToolItemID_SIGNAL" SG_ 1041 TransmissionOilTempHigh_ISig_4 "x0000001D04239BC4";
BA_ "SeToolName_SIGNAL" SG_ 1041 TransmissionOilTempHigh_ISig_4 "TransmissionOilTempHigh";
BA_ "SeToolVersion_SIGNAL" SG_ 1041 TransmissionOilTempHigh_ISig_4 "2";
BA_ "GenSigCycleTime" SG_ 1041 AvailableGearsWithHigherRatio 100;
BA_ "GenSigCycleTimeActive" SG_ 1041 AvailableGearsWithHigherRatio 100;
BA_ "GenSigStartValue" SG_ 1041 AvailableGearsWithHigherRatio 15;
BA_ "GenSigMaxLatency" SG_ 1041 AvailableGearsWithHigherRatio 26;
BA_ "Platform_VMCU1_Sig" SG_ 1041 AvailableGearsWithHigherRatio 1;
BA_ "SeToolAncestorID_SIGNAL" SG_ 1041 AvailableGearsWithHigherRatio "x0000001D0416F542";
BA_ "SeToolItemID_SIGNAL" SG_ 1041 AvailableGearsWithHigherRatio "x0000001D0436D7D6";
BA_ "SeToolName_SIGNAL" SG_ 1041 AvailableGearsWithHigherRatio "NumberOfAvailableGearsWithHigherRatio";
BA_ "SeToolVersion_SIGNAL" SG_ 1041 AvailableGearsWithHigherRatio "2";
BA_ "GenSigCycleTime" SG_ 516 Pto1Consent_ISig_4 100;
BA_ "GenSigCycleTimeActive" SG_ 516 Pto1Consent_ISig_4 100;
BA_ "GenSigStartValue" SG_ 516 Pto1Consent_ISig_4 3;
BA_ "GenSigMaxLatency" SG_ 516 Pto1Consent_ISig_4 26;
BA_ "Platform_VMCU1_Sig" SG_ 516 Pto1Consent_ISig_4 1;
BA_ "SeToolAncestorID_SIGNAL" SG_ 516 Pto1Consent_ISig_4 "x0000001D04156EBD";
BA_ "SeToolItemID_SIGNAL" SG_ 516 Pto1Consent_ISig_4 "x0000001D043A5CEC";
BA_ "SeToolName_SIGNAL" SG_ 516 Pto1Consent_ISig_4 "Pto1Consent";
BA_ "SeToolVersion_SIGNAL" SG_ 516 Pto1Consent_ISig_4 "2";
BA_ "GenSigCycleTime" SG_ 516 Pto2Consent_ISig_4 100;
BA_ "GenSigCycleTimeActive" SG_ 516 Pto2Consent_ISig_4 100;
BA_ "GenSigStartValue" SG_ 516 Pto2Consent_ISig_4 3;
BA_ "GenSigMaxLatency" SG_ 516 Pto2Consent_ISig_4 26;
BA_ "Platform_VMCU1_Sig" SG_ 516 Pto2Consent_ISig_4 1;
BA_ "SeToolAncestorID_SIGNAL" SG_ 516 Pto2Consent_ISig_4 "x0000001D04156EBF";
BA_ "SeToolItemID_SIGNAL" SG_ 516 Pto2Consent_ISig_4 "x0000001D043A5D14";
BA_ "SeToolName_SIGNAL" SG_ 516 Pto2Consent_ISig_4 "Pto2Consent";
BA_ "SeToolVersion_SIGNAL" SG_ 516 Pto2Consent_ISig_4 "2";
BA_ "GenSigCycleTime" SG_ 516 DirectionGearAllowed 100;
BA_ "GenSigCycleTimeActive" SG_ 516 DirectionGearAllowed 100;
BA_ "GenSigStartValue" SG_ 516 DirectionGearAllowed 7;
BA_ "GenSigMaxLatency" SG_ 516 DirectionGearAllowed 26;
BA_ "Platform_VMCU1_Sig" SG_ 516 DirectionGearAllowed 1;
BA_ "SeToolAncestorID_SIGNAL" SG_ 516 DirectionGearAllowed "x0000001D0416F6B7";
BA_ "SeToolItemID_SIGNAL" SG_ 516 DirectionGearAllowed "x0000001D0416F6B7";
BA_ "SeToolName_SIGNAL" SG_ 516 DirectionGearAllowed "DirectionGearAllowed";
BA_ "SeToolVersion_SIGNAL" SG_ 516 DirectionGearAllowed "1";
BA_ "GenSigCycleTime" SG_ 516 TransmissionSystemPowerDownAck 100;
BA_ "GenSigCycleTimeActive" SG_ 516 TransmissionSystemPowerDownAck 100;
BA_ "GenSigStartValue" SG_ 516 TransmissionSystemPowerDownAck 3;
BA_ "GenSigMaxLatency" SG_ 516 TransmissionSystemPowerDownAck 26;
BA_ "Platform_VMCU1_Sig" SG_ 516 TransmissionSystemPowerDownAck 1;
BA_ "SeToolAncestorID_SIGNAL" SG_ 516 TransmissionSystemPowerDownAck "x0000001D0437CB4B";
BA_ "SeToolItemID_SIGNAL" SG_ 516 TransmissionSystemPowerDownAck "x0000001D0437CB4B";
BA_ "SeToolName_SIGNAL" SG_ 516 TransmissionSystemPowerDownAck "TransmissionSystemPowerDownAck";
BA_ "SeToolVersion_SIGNAL" SG_ 516 TransmissionSystemPowerDownAck "1";
BA_ "GenSigCycleTime" SG_ 516 EcoRollActiveStatus_ISig_4 100;
BA_ "GenSigCycleTimeActive" SG_ 516 EcoRollActiveStatus_ISig_4 100;
BA_ "GenSigStartValue" SG_ 516 EcoRollActiveStatus_ISig_4 3;
BA_ "GenSigMaxLatency" SG_ 516 EcoRollActiveStatus_ISig_4 26;
BA_ "Platform_VMCU1_Sig" SG_ 516 EcoRollActiveStatus_ISig_4 1;
BA_ "SeToolAncestorID_SIGNAL" SG_ 516 EcoRollActiveStatus_ISig_4 "x0000001D043EEFC6";
BA_ "SeToolItemID_SIGNAL" SG_ 516 EcoRollActiveStatus_ISig_4 "x0000001D043EEFC6";
BA_ "SeToolName_SIGNAL" SG_ 516 EcoRollActiveStatus_ISig_4 "Eco-RollActiveStatus";
BA_ "SeToolVersion_SIGNAL" SG_ 516 EcoRollActiveStatus_ISig_4 "1";
BA_ "GenSigCycleTime" SG_ 516 TransmissionAirPressureLow 100;
BA_ "GenSigCycleTimeActive" SG_ 516 TransmissionAirPressureLow 100;
BA_ "GenSigStartValue" SG_ 516 TransmissionAirPressureLow 3;
BA_ "GenSigMaxLatency" SG_ 516 TransmissionAirPressureLow 26;
BA_ "Platform_VMCU1_Sig" SG_ 516 TransmissionAirPressureLow 1;
BA_ "SeToolAncestorID_SIGNAL" SG_ 516 TransmissionAirPressureLow "x0000001D04215F7D";
BA_ "SeToolItemID_SIGNAL" SG_ 516 TransmissionAirPressureLow "x0000001D04215F7D";
BA_ "SeToolName_SIGNAL" SG_ 516 TransmissionAirPressureLow "TransmissionAirPressureLow";
BA_ "SeToolVersion_SIGNAL" SG_ 516 TransmissionAirPressureLow "1";
BA_ "GenSigCycleTime" SG_ 516 GearBoxUnlockAuth_rqst 100;
BA_ "GenSigCycleTimeActive" SG_ 516 GearBoxUnlockAuth_rqst 100;
BA_ "GenSigStartValue" SG_ 516 GearBoxUnlockAuth_rqst 3;
BA_ "GenSigCycleTime" SG_ 516 TransmEngineStop_req 100;
BA_ "GenSigCycleTimeActive" SG_ 516 TransmEngineStop_req 100;
BA_ "GenSigStartValue" SG_ 516 TransmEngineStop_req 3;
BA_ "GenSigMaxLatency" SG_ 516 TransmEngineStop_req 26;
BA_ "Platform_VMCU1_Sig" SG_ 516 TransmEngineStop_req 1;
BA_ "GenSigCycleTime" SG_ 516 RoadInclination_ISig_4 100;
BA_ "GenSigCycleTimeActive" SG_ 516 RoadInclination_ISig_4 100;
BA_ "GenSigStartValue" SG_ 516 RoadInclination_ISig_4 255;
BA_ "GenSigMaxLatency" SG_ 516 RoadInclination_ISig_4 26;
BA_ "Platform_VMCU1_Sig" SG_ 516 RoadInclination_ISig_4 1;
BA_ "SeToolAncestorID_SIGNAL" SG_ 516 RoadInclination_ISig_4 "x0000001D043FA322";
BA_ "SeToolItemID_SIGNAL" SG_ 516 RoadInclination_ISig_4 "x0000001D043FA322";
BA_ "SeToolName_SIGNAL" SG_ 516 RoadInclination_ISig_4 "RoadInclination";
BA_ "SeToolVersion_SIGNAL" SG_ 516 RoadInclination_ISig_4 "1";
BA_ "GenSigCycleTime" SG_ 516 ACC_SGO_TransmissionStatus 100;
BA_ "GenSigCycleTimeActive" SG_ 516 ACC_SGO_TransmissionStatus 100;
BA_ "GenSigStartValue" SG_ 516 ACC_SGO_TransmissionStatus 7;
BA_ "Platform_VMCU1_Sig" SG_ 516 ACC_SGO_TransmissionStatus 1;
BA_ "GenSigCycleTime" SG_ 516 TransmOutputShaftSpeedSigned_ISi 100;
BA_ "GenSigCycleTimeActive" SG_ 516 TransmOutputShaftSpeedSigned_ISi 100;
BA_ "GenSigStartValue" SG_ 516 TransmOutputShaftSpeedSigned_ISi 65535;
BA_ "SystemSignalLongSymbol" SG_ 516 TransmOutputShaftSpeedSigned_ISi "TransmOutputShaftSpeedSigned_ISig_4";
BA_ "GenSigCycleTime" SG_ 516 ClutchOverloadStatus_ISig_4 100;
BA_ "GenSigCycleTimeActive" SG_ 516 ClutchOverloadStatus_ISig_4 100;
BA_ "GenSigStartValue" SG_ 516 ClutchOverloadStatus_ISig_4 3;
BA_ "GenSigMaxLatency" SG_ 516 ClutchOverloadStatus_ISig_4 26;
BA_ "Platform_VMCU1_Sig" SG_ 516 ClutchOverloadStatus_ISig_4 1;
BA_ "SeToolAncestorID_SIGNAL" SG_ 516 ClutchOverloadStatus_ISig_4 "x0000001D041744A1";
BA_ "SeToolItemID_SIGNAL" SG_ 516 ClutchOverloadStatus_ISig_4 "x0000001D041744A1";
BA_ "SeToolName_SIGNAL" SG_ 516 ClutchOverloadStatus_ISig_4 "ClutchOverloadStatus";
BA_ "SeToolVersion_SIGNAL" SG_ 516 ClutchOverloadStatus_ISig_4 "1";
BA_ "GenSigSendType" SG_ 2671834660 PhysDiagRespSig_F6_24_ISig_4 7;
BA_ "GenSigSendType" SG_ 2671834640 PhysDiagRespSig_F6_10_ISig_4 7;
BA_ "GenSigSendType" SG_ 2671833839 PhysDiagRespSig_F2_EF_ISig_4 7;
BA_ "GenSigSendType" SG_ 2671833830 PhysDiagRespSig_F2_E6_ISig_4 7;
BA_ "Platform_VMCU1_Sig" SG_ 2671833830 PhysDiagRespSig_F2_E6_ISig_4 1;
BA_ "GenSigSendType" SG_ 2671833829 PhysDiagRespSig_F2_E5_ISig_4 7;
BA_ "GenSigSendType" SG_ 2671833794 PhysDiagRespSig_F2_C2_ISig_4 7;
BA_ "GenSigSendType" SG_ 2671833792 PhysDiagRespSig_F2_C0_ISig_4 7;
BA_ "Platform_VMCU1_Sig" SG_ 2671833792 PhysDiagRespSig_F2_C0_ISig_4 1;
BA_ "GenSigSendType" SG_ 2671833762 PhysDiagRespSig_F2_A2_ISig_4 7;
BA_ "Platform_VMCU1_Sig" SG_ 2671833762 PhysDiagRespSig_F2_A2_ISig_4 1;
BA_ "GenSigSendType" SG_ 2671833761 PhysDiagRespSig_F2_A1_ISig_4 7;
BA_ "Platform_VMCU1_Sig" SG_ 2671833761 PhysDiagRespSig_F2_A1_ISig_4 1;
BA_ "GenSigSendType" SG_ 2671833760 PhysDiagRespSig_F2_A0_ISig_4 7;
BA_ "Platform_VMCU1_Sig" SG_ 2671833760 PhysDiagRespSig_F2_A0_ISig_4 1;
BA_ "GenSigSendType" SG_ 2671833752 PhysDiagRespSig_F2_98_ISig_4 7;
BA_ "Platform_VMCU1_Sig" SG_ 2671833752 PhysDiagRespSig_F2_98_ISig_4 1;
BA_ "GenSigSendType" SG_ 2671833740 PhysDiagRespSig_F2_8C_ISig_4 7;
BA_ "GenSigSendType" SG_ 2671833731 PhysDiagRespSig_F2_83_ISig_4 7;
BA_ "GenSigSendType" SG_ 2671833730 PhysDiagRespSig_F2_82_ISig_4 7;
BA_ "Platform_VMCU1_Sig" SG_ 2671833730 PhysDiagRespSig_F2_82_ISig_4 1;
BA_ "GenSigSendType" SG_ 2671833700 PhysDiagRespSig_F2_64_ISig_4 7;
BA_ "GenSigSendType" SG_ 2671833697 PhysDiagRespSig_F2_61_ISig_4 7;
BA_ "Platform_VMCU1_Sig" SG_ 2671833697 PhysDiagRespSig_F2_61_ISig_4 1;
BA_ "GenSigSendType" SG_ 2671833696 PhysDiagRespSig_F2_60_ISig_4 7;
BA_ "Platform_VMCU1_Sig" SG_ 2671833696 PhysDiagRespSig_F2_60_ISig_4 1;
BA_ "GenSigSendType" SG_ 2671833683 PhysDiagRespSig_F2_53_ISig_4 7;
BA_ "Platform_VMCU1_Sig" SG_ 2671833683 PhysDiagRespSig_F2_53_ISig_4 1;
BA_ "GenSigSendType" SG_ 2671833682 PhysDiagRespSig_F2_52_ISig_4 7;
BA_ "Platform_VMCU1_Sig" SG_ 2671833682 PhysDiagRespSig_F2_52_ISig_4 1;
BA_ "GenSigSendType" SG_ 2671833681 PhysDiagRespSig_F2_51_ISig_4 7;
BA_ "Platform_VMCU1_Sig" SG_ 2671833681 PhysDiagRespSig_F2_51_ISig_4 1;
BA_ "GenSigSendType" SG_ 2671833680 PhysDiagRespSig_F2_50_ISig_4 7;
BA_ "Platform_VMCU1_Sig" SG_ 2671833680 PhysDiagRespSig_F2_50_ISig_4 1;
BA_ "GenSigSendType" SG_ 2671833665 PhysDiagRespSig_F2_41_ISig_4 7;
BA_ "Platform_VMCU1_Sig" SG_ 2671833665 PhysDiagRespSig_F2_41_ISig_4 1;
BA_ "GenSigSendType" SG_ 2671833664 PhysDiagRespSig_F2_40_ISig_4 7;
BA_ "Platform_VMCU1_Sig" SG_ 2671833664 PhysDiagRespSig_F2_40_ISig_4 1;
BA_ "GenSigSendType" SG_ 2671833638 PhysDiagRespSig_F2_26_ISig_4 7;
BA_ "Platform_VMCU1_Sig" SG_ 2671833638 PhysDiagRespSig_F2_26_ISig_4 1;
BA_ "GenSigSendType" SG_ 2671833624 PhysDiagRespSig_F2_18_ISig_4 7;
BA_ "Platform_VMCU1_Sig" SG_ 2671833624 PhysDiagRespSig_F2_18_ISig_4 1;
BA_ "GenSigSendType" SG_ 2671833616 PhysDiagRespSig_F2_10_ISig_4 7;
BA_ "Platform_VMCU1_Sig" SG_ 2671833616 PhysDiagRespSig_F2_10_ISig_4 1;
BA_ "GenSigSendType" SG_ 2564485459 PhysDiagRespSig_F1_53_ISig_4 7;
BA_ "Platform_VMCU1_Sig" SG_ 2564485459 PhysDiagRespSig_F1_53_ISig_4 1;
BA_ "GenSigSendType" SG_ 2564485392 PhysDiagRespSig_F1_10_extra 7;
BA_ "Platform_VMCU1_Sig" SG_ 2564485392 PhysDiagRespSig_F1_10_extra 1;
BA_ "GenSigSendType" SG_ 2671833360 PhysDiagRespSig_F1_10_ISig_4 7;
BA_ "Platform_VMCU1_Sig" SG_ 2671833360 PhysDiagRespSig_F1_10_ISig_4 1;
BA_ "GenSigSendType" SG_ 2671833074 PhysDiagReqSig_EF_F2_ISig_4 7;
BA_ "GenSigSendType" SG_ 2671830770 PhysDiagReqSig_E6_F2_ISig_4 7;
BA_ "Platform_VMCU1_Sig" SG_ 2671830770 PhysDiagReqSig_E6_F2_ISig_4 1;
BA_ "GenSigSendType" SG_ 2671830514 PhysDiagReqSig_E5_F2_ISig_4 7;
BA_ "GenSigSendType" SG_ 2671821554 PhysDiagReqSig_C2_F2_ISig_4 7;
BA_ "GenSigSendType" SG_ 2671821042 PhysDiagReqSig_C0_F2_ISig_4 7;
BA_ "Platform_VMCU1_Sig" SG_ 2671821042 PhysDiagReqSig_C0_F2_ISig_4 1;
BA_ "GenSigSendType" SG_ 2671813362 PhysDiagReqSig_A2_F2_ISig_4 7;
BA_ "Platform_VMCU1_Sig" SG_ 2671813362 PhysDiagReqSig_A2_F2_ISig_4 1;
BA_ "GenSigSendType" SG_ 2671813106 PhysDiagReqSig_A1_F2_ISig_4 7;
BA_ "Platform_VMCU1_Sig" SG_ 2671813106 PhysDiagReqSig_A1_F2_ISig_4 1;
BA_ "GenSigSendType" SG_ 2671812850 PhysDiagReqSig_A0_F2_ISig_4 7;
BA_ "Platform_VMCU1_Sig" SG_ 2671812850 PhysDiagReqSig_A0_F2_ISig_4 1;
BA_ "GenSigSendType" SG_ 2671810802 PhysDiagReqSig_98_F2_ISig_4 7;
BA_ "Platform_VMCU1_Sig" SG_ 2671810802 PhysDiagReqSig_98_F2_ISig_4 1;
BA_ "GenSigSendType" SG_ 2671807730 PhysDiagReqSig_8C_F2_ISig_4 7;
BA_ "GenSigSendType" SG_ 2671805426 PhysDiagReqSig_83_F2_ISig_4 7;
BA_ "GenSigSendType" SG_ 2671805170 PhysDiagReqSig_82_F2_ISig_4 7;
BA_ "Platform_VMCU1_Sig" SG_ 2671805170 PhysDiagReqSig_82_F2_ISig_4 1;
BA_ "GenSigSendType" SG_ 2671797490 PhysDiagReqSig_64_F2_ISig_4 7;
BA_ "GenSigSendType" SG_ 2671796722 PhysDiagReqSig_61_F2_ISig_4 7;
BA_ "Platform_VMCU1_Sig" SG_ 2671796722 PhysDiagReqSig_61_F2_ISig_4 1;
BA_ "GenSigSendType" SG_ 2671796466 PhysDiagReqSig_60_F2_ISig_4 7;
BA_ "Platform_VMCU1_Sig" SG_ 2671796466 PhysDiagReqSig_60_F2_ISig_4 1;
BA_ "GenSigSendType" SG_ 2671793138 PhysDiagReqSig_53_F2_ISig_4 7;
BA_ "Platform_VMCU1_Sig" SG_ 2671793138 PhysDiagReqSig_53_F2_ISig_4 1;
BA_ "GenSigSendType" SG_ 2564445169 PhysDiagReqSig_53_F1_ISig_4 7;
BA_ "Platform_VMCU1_Sig" SG_ 2564445169 PhysDiagReqSig_53_F1_ISig_4 1;
BA_ "GenSigSendType" SG_ 2671792882 PhysDiagReqSig_52_F2_ISig_4 7;
BA_ "Platform_VMCU1_Sig" SG_ 2671792882 PhysDiagReqSig_52_F2_ISig_4 1;
BA_ "GenSigSendType" SG_ 2671792626 PhysDiagReqSig_51_F2_ISig_4 7;
BA_ "Platform_VMCU1_Sig" SG_ 2671792626 PhysDiagReqSig_51_F2_ISig_4 1;
BA_ "GenSigSendType" SG_ 2671792370 PhysDiagReqSig_50_F2_ISig_4 7;
BA_ "Platform_VMCU1_Sig" SG_ 2671792370 PhysDiagReqSig_50_F2_ISig_4 1;
BA_ "GenSigSendType" SG_ 2671788530 PhysDiagReqSig_41_F2_ISig_4 7;
BA_ "Platform_VMCU1_Sig" SG_ 2671788530 PhysDiagReqSig_41_F2_ISig_4 1;
BA_ "GenSigSendType" SG_ 2671788274 PhysDiagReqSig_40_F2_ISig_4 7;
BA_ "Platform_VMCU1_Sig" SG_ 2671788274 PhysDiagReqSig_40_F2_ISig_4 1;
BA_ "GenSigSendType" SG_ 2671781618 PhysDiagReqSig_26_F2_ISig_4 7;
BA_ "Platform_VMCU1_Sig" SG_ 2671781618 PhysDiagReqSig_26_F2_ISig_4 1;
BA_ "GenSigSendType" SG_ 2671781110 PhysDiagReqSig_24_F6_ISig_4 7;
BA_ "GenSigSendType" SG_ 2671778034 PhysDiagReqSig_18_F2_ISig_4 7;
BA_ "Platform_VMCU1_Sig" SG_ 2671778034 PhysDiagReqSig_18_F2_ISig_4 1;
BA_ "GenSigSendType" SG_ 2671775990 PhysDiagReqSig_10_F6_ISig_4 7;
BA_ "GenSigSendType" SG_ 2671775986 PhysDiagReqSig_10_F2_ISig_4 7;
BA_ "Platform_VMCU1_Sig" SG_ 2671775986 PhysDiagReqSig_10_F2_ISig_4 1;
BA_ "GenSigSendType" SG_ 2564428017 PhysDiagReqSig_10_F1_extra 7;
BA_ "Platform_VMCU1_Sig" SG_ 2564428017 PhysDiagReqSig_10_F1_extra 1;
BA_ "GenSigSendType" SG_ 2671775985 PhysDiagReqSig_10_F1_ISig_4 7;
BA_ "Platform_VMCU1_Sig" SG_ 2671775985 PhysDiagReqSig_10_F1_ISig_4 1;
BA_ "GenSigSendType" SG_ 2564502513 FuncDiagDataOBD_extra 7;
BA_ "Platform_VMCU1_Sig" SG_ 2564502513 FuncDiagDataOBD_extra 1;
BA_ "GenSigSendType" SG_ 2671850481 FuncDiagDataOBD_ISig_4 7;
BA_ "Platform_VMCU1_Sig" SG_ 2671850481 FuncDiagDataOBD_ISig_4 1;
BA_ "GenSigSendType" SG_ 2671850486 FuncDiagDataOBDF6_ISig_4 7;
BA_ "GenSigSendType" SG_ 2671902708 FuncDiagDataIntTesterTGW2_ISig_4 7;
BA_ "Platform_VMCU1_Sig" SG_ 2671902708 FuncDiagDataIntTesterTGW2_ISig_4 1;
BA_ "GenSigCycleTime" SG_ 1280 ExteriorLightsAFSAllowedFAKE 100;
BA_ "GenSigCycleTimeActive" SG_ 1280 ExteriorLightsAFSAllowedFAKE 100;
BA_ "GenSigStartValue" SG_ 1280 ExteriorLightsAFSAllowedFAKE 3;
BA_ "GenSigCycleTime" SG_ 1280 CamerasPowerSupply_rqstFAKE 100;
BA_ "GenSigCycleTimeActive" SG_ 1280 CamerasPowerSupply_rqstFAKE 100;
BA_ "GenSigStartValue" SG_ 1280 CamerasPowerSupply_rqstFAKE 3;
BA_ "GenSigCycleTime" SG_ 1129 AlarmClkAl_LECM_stat_SetMin_ISig 100;
BA_ "GenSigCycleTimeActive" SG_ 1129 AlarmClkAl_LECM_stat_SetMin_ISig 100;
BA_ "GenSigStartValue" SG_ 1129 AlarmClkAl_LECM_stat_SetMin_ISig 63;
BA_ "SystemSignalLongSymbol" SG_ 1129 AlarmClkAl_LECM_stat_SetMin_ISig "AlarmClkAl_LECM_stat_SetMin_ISig_4";
BA_ "GenSigCycleTime" SG_ 1129 AlarmClkAl_LECM_stat_SetHr_ISig_ 100;
BA_ "GenSigCycleTimeActive" SG_ 1129 AlarmClkAl_LECM_stat_SetHr_ISig_ 100;
BA_ "GenSigStartValue" SG_ 1129 AlarmClkAl_LECM_stat_SetHr_ISig_ 31;
BA_ "SystemSignalLongSymbol" SG_ 1129 AlarmClkAl_LECM_stat_SetHr_ISig_ "AlarmClkAl_LECM_stat_SetHr_ISig_4";
BA_ "GenSigCycleTime" SG_ 1129 AlarmClkAl_LECM_stat_Stat_ISig_4 100;
BA_ "GenSigCycleTimeActive" SG_ 1129 AlarmClkAl_LECM_stat_Stat_ISig_4 100;
BA_ "GenSigCycleTime" SG_ 1129 AlarmClkAl_LECM_stat_Mode_ISig_4 100;
BA_ "GenSigCycleTimeActive" SG_ 1129 AlarmClkAl_LECM_stat_Mode_ISig_4 100;
BA_ "GenSigCycleTime" SG_ 1129 AlarmClkAl_LECM_stat_ID_ISig_4 100;
BA_ "GenSigCycleTimeActive" SG_ 1129 AlarmClkAl_LECM_stat_ID_ISig_4 100;
BA_ "GenSigStartValue" SG_ 1129 AlarmClkAl_LECM_stat_ID_ISig_4 127;
BA_ "GenSigCycleTime" SG_ 1129 AlarmClkAl_LECM_stat_Type_ISig_4 100;
BA_ "GenSigCycleTimeActive" SG_ 1129 AlarmClkAl_LECM_stat_Type_ISig_4 100;
BA_ "GenSigStartValue" SG_ 1129 AlarmClkAl_LECM_stat_Type_ISig_4 7;
BA_ "GenSigCycleTime" SG_ 1129 AlarmClkAl_LECM_stat_DaySet_ISig 100;
BA_ "GenSigCycleTimeActive" SG_ 1129 AlarmClkAl_LECM_stat_DaySet_ISig 100;
BA_ "SystemSignalLongSymbol" SG_ 1129 AlarmClkAl_LECM_stat_DaySet_ISig "AlarmClkAl_LECM_stat_DaySet_ISig_4";
BA_ "GenSigSendType" SG_ 1395 IC3_BB2_07S_FCS 7;
BA_ "GenSigSendType" SG_ 1394 DisplayText_stat_ISig_4 1;
BA_ "GenSigMaxLatency" SG_ 1394 DisplayText_stat_ISig_4 77;
BA_ "GenSigSendType" SG_ 1444 IC3_BB2_06S_FCS 7;
BA_ "GenSigSendType" SG_ 1443 SaveTrlrName_rqst_Request 1;
BA_ "GenSigStartValue" SG_ 1443 SaveTrlrName_rqst_Request 3;
BA_ "GenSigMaxLatency" SG_ 1443 SaveTrlrName_rqst_Request 1000;
BA_ "NeedsUpdateBit" SG_ 1443 SaveTrlrName_rqst_Request 1;
BA_ "GenSigSendType" SG_ 1443 SaveTrlrName_rqst_sg_UB 7;
BA_ "GenSigSendType" SG_ 1443 SaveTrlrName_rqst_NewName 1;
BA_ "GenSigMaxLatency" SG_ 1443 SaveTrlrName_rqst_NewName 1000;
BA_ "NeedsUpdateBit" SG_ 1443 SaveTrlrName_rqst_NewName 1;
BA_ "GenSigSendType" SG_ 1443 SaveTrlrName_rqst_Position 1;
BA_ "GenSigStartValue" SG_ 1443 SaveTrlrName_rqst_Position 31;
BA_ "GenSigMaxLatency" SG_ 1443 SaveTrlrName_rqst_Position 1000;
BA_ "NeedsUpdateBit" SG_ 1443 SaveTrlrName_rqst_Position 1;
BA_ "GenSigSendType" SG_ 1214 ChangeDate_rqst_Day 1;
BA_ "GenSigCycleTime" SG_ 1214 ChangeDate_rqst_Day 100;
BA_ "GenSigCycleTimeActive" SG_ 1214 ChangeDate_rqst_Day 100;
BA_ "GenSigStartValue" SG_ 1214 ChangeDate_rqst_Day 255;
BA_ "GenSigMaxLatency" SG_ 1214 ChangeDate_rqst_Day 200;
BA_ "NeedsUpdateBit" SG_ 1214 ChangeDate_rqst_Day 1;
BA_ "GenSigSendType" SG_ 1214 ChangeTime_rqst_Minutes 1;
BA_ "GenSigCycleTime" SG_ 1214 ChangeTime_rqst_Minutes 100;
BA_ "GenSigCycleTimeActive" SG_ 1214 ChangeTime_rqst_Minutes 100;
BA_ "GenSigStartValue" SG_ 1214 ChangeTime_rqst_Minutes 255;
BA_ "GenSigSendType" SG_ 1214 ChangeDate_rqst_Year 1;
BA_ "GenSigCycleTime" SG_ 1214 ChangeDate_rqst_Year 100;
BA_ "GenSigCycleTimeActive" SG_ 1214 ChangeDate_rqst_Year 100;
BA_ "GenSigStartValue" SG_ 1214 ChangeDate_rqst_Year 255;
BA_ "GenSigMaxLatency" SG_ 1214 ChangeDate_rqst_Year 200;
BA_ "NeedsUpdateBit" SG_ 1214 ChangeDate_rqst_Year 1;
BA_ "GenSigSendType" SG_ 1214 ChangeDate_rqst_sg_UB 7;
BA_ "GenSigSendType" SG_ 1214 ChangeTime_rqst_Hours 1;
BA_ "GenSigCycleTime" SG_ 1214 ChangeTime_rqst_Hours 100;
BA_ "GenSigCycleTimeActive" SG_ 1214 ChangeTime_rqst_Hours 100;
BA_ "GenSigStartValue" SG_ 1214 ChangeTime_rqst_Hours 255;
BA_ "GenSigSendType" SG_ 1214 ChangeDate_rqst_Month 1;
BA_ "GenSigCycleTime" SG_ 1214 ChangeDate_rqst_Month 100;
BA_ "GenSigCycleTimeActive" SG_ 1214 ChangeDate_rqst_Month 100;
BA_ "GenSigStartValue" SG_ 1214 ChangeDate_rqst_Month 255;
BA_ "GenSigMaxLatency" SG_ 1214 ChangeDate_rqst_Month 200;
BA_ "NeedsUpdateBit" SG_ 1214 ChangeDate_rqst_Month 1;
BA_ "GenSigSendType" SG_ 1214 ChangeTime_rqst_sg_UB 7;
BA_ "GenSigSendType" SG_ 1256 AlmClkSetAlarm_rqst_sg_UB 7;
BA_ "GenSigSendType" SG_ 1256 AlmClkSetAlarm_rqst_Stat 1;
BA_ "GenSigCycleTime" SG_ 1256 AlmClkSetAlarm_rqst_Stat 100;
BA_ "GenSigCycleTimeActive" SG_ 1256 AlmClkSetAlarm_rqst_Stat 100;
BA_ "GenSigStartValue" SG_ 1256 AlmClkSetAlarm_rqst_Stat 3;
BA_ "GenSigMaxLatency" SG_ 1256 AlmClkSetAlarm_rqst_Stat 210;
BA_ "NeedsUpdateBit" SG_ 1256 AlmClkSetAlarm_rqst_Stat 1;
BA_ "GenSigSendType" SG_ 1256 AlmClkSetAlarm_rqst_Mode 1;
BA_ "GenSigCycleTime" SG_ 1256 AlmClkSetAlarm_rqst_Mode 100;
BA_ "GenSigCycleTimeActive" SG_ 1256 AlmClkSetAlarm_rqst_Mode 100;
BA_ "GenSigStartValue" SG_ 1256 AlmClkSetAlarm_rqst_Mode 3;
BA_ "GenSigMaxLatency" SG_ 1256 AlmClkSetAlarm_rqst_Mode 210;
BA_ "NeedsUpdateBit" SG_ 1256 AlmClkSetAlarm_rqst_Mode 1;
BA_ "GenSigSendType" SG_ 1256 AlmClkSetAlarm_rqst_SetHr 1;
BA_ "GenSigCycleTime" SG_ 1256 AlmClkSetAlarm_rqst_SetHr 100;
BA_ "GenSigCycleTimeActive" SG_ 1256 AlmClkSetAlarm_rqst_SetHr 100;
BA_ "GenSigStartValue" SG_ 1256 AlmClkSetAlarm_rqst_SetHr 31;
BA_ "GenSigMaxLatency" SG_ 1256 AlmClkSetAlarm_rqst_SetHr 210;
BA_ "NeedsUpdateBit" SG_ 1256 AlmClkSetAlarm_rqst_SetHr 1;
BA_ "GenSigSendType" SG_ 1256 AlmClkSetAlarm_rqst_ID 1;
BA_ "GenSigCycleTime" SG_ 1256 AlmClkSetAlarm_rqst_ID 100;
BA_ "GenSigCycleTimeActive" SG_ 1256 AlmClkSetAlarm_rqst_ID 100;
BA_ "GenSigStartValue" SG_ 1256 AlmClkSetAlarm_rqst_ID 127;
BA_ "GenSigMaxLatency" SG_ 1256 AlmClkSetAlarm_rqst_ID 210;
BA_ "NeedsUpdateBit" SG_ 1256 AlmClkSetAlarm_rqst_ID 1;
BA_ "GenSigSendType" SG_ 1256 AlmClkSetAlarm_rqst_SetMin 1;
BA_ "GenSigCycleTime" SG_ 1256 AlmClkSetAlarm_rqst_SetMin 100;
BA_ "GenSigCycleTimeActive" SG_ 1256 AlmClkSetAlarm_rqst_SetMin 100;
BA_ "GenSigStartValue" SG_ 1256 AlmClkSetAlarm_rqst_SetMin 63;
BA_ "GenSigMaxLatency" SG_ 1256 AlmClkSetAlarm_rqst_SetMin 210;
BA_ "NeedsUpdateBit" SG_ 1256 AlmClkSetAlarm_rqst_SetMin 1;
BA_ "GenSigSendType" SG_ 1256 AlmClkSetAlarm_rqst_Type 1;
BA_ "GenSigCycleTime" SG_ 1256 AlmClkSetAlarm_rqst_Type 100;
BA_ "GenSigCycleTimeActive" SG_ 1256 AlmClkSetAlarm_rqst_Type 100;
BA_ "GenSigStartValue" SG_ 1256 AlmClkSetAlarm_rqst_Type 7;
BA_ "GenSigMaxLatency" SG_ 1256 AlmClkSetAlarm_rqst_Type 210;
BA_ "NeedsUpdateBit" SG_ 1256 AlmClkSetAlarm_rqst_Type 1;
BA_ "GenSigSendType" SG_ 1256 AlmClkSetAlarm_rqst_DaySet 1;
BA_ "GenSigCycleTime" SG_ 1256 AlmClkSetAlarm_rqst_DaySet 100;
BA_ "GenSigCycleTimeActive" SG_ 1256 AlmClkSetAlarm_rqst_DaySet 100;
BA_ "GenSigStartValue" SG_ 1256 AlmClkSetAlarm_rqst_DaySet 255;
BA_ "GenSigMaxLatency" SG_ 1256 AlmClkSetAlarm_rqst_DaySet 210;
BA_ "NeedsUpdateBit" SG_ 1256 AlmClkSetAlarm_rqst_DaySet 1;
BA_ "GenSigSendType" SG_ 839 UpdParkClimTimerRqst_sg_UB_ISig_ 7;
BA_ "SystemSignalLongSymbol" SG_ 839 UpdParkClimTimerRqst_sg_UB_ISig_ "UpdParkClimTimerRqst_sg_UB_ISig_4";
BA_ "GenSigSendType" SG_ 839 UpdParkClimTimerRqst_TimerCmd_IS 1;
BA_ "GenSigStartValue" SG_ 839 UpdParkClimTimerRqst_TimerCmd_IS 7;
BA_ "NeedsUpdateBit" SG_ 839 UpdParkClimTimerRqst_TimerCmd_IS 1;
BA_ "SystemSignalLongSymbol" SG_ 839 UpdParkClimTimerRqst_TimerCmd_IS "UpdParkClimTimerRqst_TimerCmd_ISig_4";
BA_ "GenSigCycleTime" SG_ 839 CombinationScaleLoad_ScaleLoad 100;
BA_ "GenSigCycleTimeActive" SG_ 839 CombinationScaleLoad_ScaleLoad 100;
BA_ "GenSigStartValue" SG_ 839 CombinationScaleLoad_ScaleLoad 4294967295;
BA_ "GenSigSendType" SG_ 839 UpdParkClimTimerRqst_TimRqst_ISi 1;
BA_ "GenSigStartValue" SG_ 839 UpdParkClimTimerRqst_TimRqst_ISi 255;
BA_ "NeedsUpdateBit" SG_ 839 UpdParkClimTimerRqst_TimRqst_ISi 1;
BA_ "SystemSignalLongSymbol" SG_ 839 UpdParkClimTimerRqst_TimRqst_ISi "UpdParkClimTimerRqst_TimRqst_ISig_4";
BA_ "GenSigCycleTime" SG_ 839 CombinationScaleLoad_FirstAxleID 100;
BA_ "GenSigCycleTimeActive" SG_ 839 CombinationScaleLoad_FirstAxleID 100;
BA_ "GenSigStartValue" SG_ 839 CombinationScaleLoad_FirstAxleID 255;
BA_ "GenSigCycleTime" SG_ 839 CombinationScaleLoad_LastAxleID 100;
BA_ "GenSigCycleTimeActive" SG_ 839 CombinationScaleLoad_LastAxleID 100;
BA_ "GenSigStartValue" SG_ 839 CombinationScaleLoad_LastAxleID 255;
BA_ "GenSigCycleTime" SG_ 838 PhoneButtonIndication_cmd 100;
BA_ "GenSigCycleTimeActive" SG_ 838 PhoneButtonIndication_cmd 100;
BA_ "GenSigStartValue" SG_ 838 PhoneButtonIndication_cmd 3;
BA_ "GenSigCycleTime" SG_ 838 AirbagTelltale_stat_ISig_4 100;
BA_ "GenSigCycleTimeActive" SG_ 838 AirbagTelltale_stat_ISig_4 100;
BA_ "GenSigStartValue" SG_ 838 AirbagTelltale_stat_ISig_4 3;
BA_ "GenSigCycleTime" SG_ 838 AudioSystemStatus_ISig_4 100;
BA_ "GenSigCycleTimeActive" SG_ 838 AudioSystemStatus_ISig_4 100;
BA_ "GenSigStartValue" SG_ 838 AudioSystemStatus_ISig_4 3;
BA_ "GenSigCycleTime" SG_ 838 AudioSourceUsbAvailable_ISig_4 100;
BA_ "GenSigCycleTimeActive" SG_ 838 AudioSourceUsbAvailable_ISig_4 100;
BA_ "GenSigStartValue" SG_ 838 AudioSourceUsbAvailable_ISig_4 3;
BA_ "GenSigCycleTime" SG_ 838 AQSModeRqst_ISig_4 100;
BA_ "GenSigCycleTimeActive" SG_ 838 AQSModeRqst_ISig_4 100;
BA_ "GenSigStartValue" SG_ 838 AQSModeRqst_ISig_4 7;
BA_ "GenSigCycleTime" SG_ 838 PresetIndicationCmd_ISig_4 100;
BA_ "GenSigCycleTimeActive" SG_ 838 PresetIndicationCmd_ISig_4 100;
BA_ "GenSigStartValue" SG_ 838 PresetIndicationCmd_ISig_4 63;
BA_ "GenSigCycleTime" SG_ 838 AudioSourceCdAvailable_ISig_4 100;
BA_ "GenSigCycleTimeActive" SG_ 838 AudioSourceCdAvailable_ISig_4 100;
BA_ "GenSigStartValue" SG_ 838 AudioSourceCdAvailable_ISig_4 3;
BA_ "GenSigCycleTime" SG_ 838 AudioVolumeIndicationCmd_ISig_4 100;
BA_ "GenSigCycleTimeActive" SG_ 838 AudioVolumeIndicationCmd_ISig_4 100;
BA_ "GenSigCycleTime" SG_ 838 AudioSourceStatus2_ISig_4 100;
BA_ "GenSigCycleTimeActive" SG_ 838 AudioSourceStatus2_ISig_4 100;
BA_ "GenSigStartValue" SG_ 838 AudioSourceStatus2_ISig_4 15;
BA_ "GenSigCycleTime" SG_ 838 BTStatus 100;
BA_ "GenSigCycleTimeActive" SG_ 838 BTStatus 100;
BA_ "GenSigStartValue" SG_ 838 BTStatus 3;
BA_ "GenSigCycleTime" SG_ 838 VCSystPowerSupply_rqst 100;
BA_ "GenSigCycleTimeActive" SG_ 838 VCSystPowerSupply_rqst 100;
BA_ "GenSigStartValue" SG_ 838 VCSystPowerSupply_rqst 3;
BA_ "GenSigCycleTime" SG_ 838 AudioSourceBtStreamAvailable_ISi 100;
BA_ "GenSigCycleTimeActive" SG_ 838 AudioSourceBtStreamAvailable_ISi 100;
BA_ "GenSigStartValue" SG_ 838 AudioSourceBtStreamAvailable_ISi 3;
BA_ "SystemSignalLongSymbol" SG_ 838 AudioSourceBtStreamAvailable_ISi "AudioSourceBtStreamAvailable_ISig_4";
BA_ "GenSigCycleTime" SG_ 838 AudioMuteStat_ISig_4 100;
BA_ "GenSigCycleTimeActive" SG_ 838 AudioMuteStat_ISig_4 100;
BA_ "GenSigStartValue" SG_ 838 AudioMuteStat_ISig_4 7;
BA_ "SeToolAncestorID_SIGNAL" SG_ 838 AudioMuteStat_ISig_4 "x0000001D043278F0";
BA_ "SeToolItemID_SIGNAL" SG_ 838 AudioMuteStat_ISig_4 "x0000001D043278F0";
BA_ "SeToolName_SIGNAL" SG_ 838 AudioMuteStat_ISig_4 "AudioMuteStat";
BA_ "SeToolVersion_SIGNAL" SG_ 838 AudioMuteStat_ISig_4 "1";
BA_ "GenSigCycleTime" SG_ 838 ISeeEnableRequest 100;
BA_ "GenSigCycleTimeActive" SG_ 838 ISeeEnableRequest 100;
BA_ "GenSigStartValue" SG_ 838 ISeeEnableRequest 3;
BA_ "GenSigCycleTime" SG_ 838 ACModeRqst_ISig_4 100;
BA_ "GenSigCycleTimeActive" SG_ 838 ACModeRqst_ISig_4 100;
BA_ "GenSigStartValue" SG_ 838 ACModeRqst_ISig_4 7;
BA_ "GenSigCycleTime" SG_ 838 AudioSourceStatus_ISig_4 100;
BA_ "GenSigCycleTimeActive" SG_ 838 AudioSourceStatus_ISig_4 100;
BA_ "GenSigStartValue" SG_ 838 AudioSourceStatus_ISig_4 7;
BA_ "GenSigCycleTime" SG_ 838 CalDataLoad_rqst_VehicleID 100;
BA_ "GenSigCycleTimeActive" SG_ 838 CalDataLoad_rqst_VehicleID 100;
BA_ "GenSigStartValue" SG_ 838 CalDataLoad_rqst_VehicleID 7;
BA_ "GenSigCycleTime" SG_ 838 AudioSourceIpodAvailable_ISig_4 100;
BA_ "GenSigCycleTimeActive" SG_ 838 AudioSourceIpodAvailable_ISig_4 100;
BA_ "GenSigStartValue" SG_ 838 AudioSourceIpodAvailable_ISig_4 3;
BA_ "GenSigCycleTime" SG_ 838 CalDataLoad_rqst_AxleID 100;
BA_ "GenSigCycleTimeActive" SG_ 838 CalDataLoad_rqst_AxleID 100;
BA_ "GenSigStartValue" SG_ 838 CalDataLoad_rqst_AxleID 15;
BA_ "GenSigCycleTime" SG_ 838 AutoBlowerLevelRqst_ISig_4 100;
BA_ "GenSigCycleTimeActive" SG_ 838 AutoBlowerLevelRqst_ISig_4 100;
BA_ "GenSigStartValue" SG_ 838 AutoBlowerLevelRqst_ISig_4 7;
BA_ "GenSigCycleTime" SG_ 838 AutoDefogModeRqst_ISig_4 100;
BA_ "GenSigCycleTimeActive" SG_ 838 AutoDefogModeRqst_ISig_4 100;
BA_ "GenSigStartValue" SG_ 838 AutoDefogModeRqst_ISig_4 7;
BA_ "GenSigSendType" SG_ 515 SetParkClimTimerRqst_Mon_ISig_4 1;
BA_ "NeedsUpdateBit" SG_ 515 SetParkClimTimerRqst_Mon_ISig_4 1;
BA_ "GenSigSendType" SG_ 515 SetParkClimTimerRqst_Tue_ISig_4 1;
BA_ "NeedsUpdateBit" SG_ 515 SetParkClimTimerRqst_Tue_ISig_4 1;
BA_ "GenSigSendType" SG_ 515 SetParkClimTimerRqst_Sat_ISig_4 1;
BA_ "NeedsUpdateBit" SG_ 515 SetParkClimTimerRqst_Sat_ISig_4 1;
BA_ "GenSigSendType" SG_ 515 SetParkClimTimerRqst_Dur_ISig_4 1;
BA_ "GenSigStartValue" SG_ 515 SetParkClimTimerRqst_Dur_ISig_4 127;
BA_ "NeedsUpdateBit" SG_ 515 SetParkClimTimerRqst_Dur_ISig_4 1;
BA_ "GenSigSendType" SG_ 515 SetParkClimTimerRqst_Type_ISig_4 1;
BA_ "GenSigStartValue" SG_ 515 SetParkClimTimerRqst_Type_ISig_4 7;
BA_ "NeedsUpdateBit" SG_ 515 SetParkClimTimerRqst_Type_ISig_4 1;
BA_ "GenSigSendType" SG_ 515 SetParkClimTimerRqst_Sun_ISig_4 1;
BA_ "NeedsUpdateBit" SG_ 515 SetParkClimTimerRqst_Sun_ISig_4 1;
BA_ "GenSigSendType" SG_ 515 SetParkClimTimerRqst_Wed_ISig_4 1;
BA_ "NeedsUpdateBit" SG_ 515 SetParkClimTimerRqst_Wed_ISig_4 1;
BA_ "GenSigSendType" SG_ 515 SetParkClimTimerRqst_TimerNr_ISi 1;
BA_ "GenSigStartValue" SG_ 515 SetParkClimTimerRqst_TimerNr_ISi 255;
BA_ "NeedsUpdateBit" SG_ 515 SetParkClimTimerRqst_TimerNr_ISi 1;
BA_ "SystemSignalLongSymbol" SG_ 515 SetParkClimTimerRqst_TimerNr_ISi "SetParkClimTimerRqst_TimerNr_ISig_4";
BA_ "GenSigSendType" SG_ 515 SetParkClimTimerRqst_Min_ISig_4 1;
BA_ "GenSigStartValue" SG_ 515 SetParkClimTimerRqst_Min_ISig_4 255;
BA_ "NeedsUpdateBit" SG_ 515 SetParkClimTimerRqst_Min_ISig_4 1;
BA_ "GenSigSendType" SG_ 515 SetParkClimTimerRqst_Hrs_ISig_4 1;
BA_ "GenSigStartValue" SG_ 515 SetParkClimTimerRqst_Hrs_ISig_4 255;
BA_ "NeedsUpdateBit" SG_ 515 SetParkClimTimerRqst_Hrs_ISig_4 1;
BA_ "GenSigSendType" SG_ 515 SetParkClimTimerRqst_Temp_ISig_4 1;
BA_ "GenSigStartValue" SG_ 515 SetParkClimTimerRqst_Temp_ISig_4 255;
BA_ "NeedsUpdateBit" SG_ 515 SetParkClimTimerRqst_Temp_ISig_4 1;
BA_ "GenSigSendType" SG_ 515 SetParkClimTimerRqst_Thu_ISig_4 1;
BA_ "NeedsUpdateBit" SG_ 515 SetParkClimTimerRqst_Thu_ISig_4 1;
BA_ "GenSigSendType" SG_ 515 SetParkClimTimerRqst_sg_UB_ISig_ 7;
BA_ "SystemSignalLongSymbol" SG_ 515 SetParkClimTimerRqst_sg_UB_ISig_ "SetParkClimTimerRqst_sg_UB_ISig_4";
BA_ "GenSigSendType" SG_ 515 SetParkClimTimerRqst_TimerCmd_IS 1;
BA_ "GenSigStartValue" SG_ 515 SetParkClimTimerRqst_TimerCmd_IS 7;
BA_ "NeedsUpdateBit" SG_ 515 SetParkClimTimerRqst_TimerCmd_IS 1;
BA_ "SystemSignalLongSymbol" SG_ 515 SetParkClimTimerRqst_TimerCmd_IS "SetParkClimTimerRqst_TimerCmd_ISig_4";
BA_ "GenSigSendType" SG_ 515 SetParkClimTimerRqst_Fri_ISig_4 1;
BA_ "NeedsUpdateBit" SG_ 515 SetParkClimTimerRqst_Fri_ISig_4 1;
BA_ "GenSigSendType" SG_ 515 SetParkClimTimerRqst_Rec_ISig_4 1;
BA_ "NeedsUpdateBit" SG_ 515 SetParkClimTimerRqst_Rec_ISig_4 1;
BA_ "GenSigCycleTime" SG_ 1306 ChargeCordStatus 100;
BA_ "GenSigCycleTimeActive" SG_ 1306 ChargeCordStatus 100;
BA_ "GenSigStartValue" SG_ 1306 ChargeCordStatus 3;
BA_ "GenSigCycleTime" SG_ 1306 HVStateOfCharge 100;
BA_ "GenSigCycleTimeActive" SG_ 1306 HVStateOfCharge 100;
BA_ "GenSigStartValue" SG_ 1306 HVStateOfCharge 255;
BA_ "GenSigCycleTime" SG_ 1306 HVTimeToFullyCharged 100;
BA_ "GenSigCycleTimeActive" SG_ 1306 HVTimeToFullyCharged 100;
BA_ "GenSigStartValue" SG_ 1306 HVTimeToFullyCharged 65535;
BA_ "GenSigCycleTime" SG_ 1306 HVChargingStatus 100;
BA_ "GenSigCycleTimeActive" SG_ 1306 HVChargingStatus 100;
BA_ "GenSigStartValue" SG_ 1306 HVChargingStatus 7;
BA_ "GenSigCycleTime" SG_ 1306 ChargePortLockStatus 100;
BA_ "GenSigCycleTimeActive" SG_ 1306 ChargePortLockStatus 100;
BA_ "GenSigStartValue" SG_ 1306 ChargePortLockStatus 3;
BA_ "GenSigCycleTime" SG_ 1363 ChlrVlvPsnFlt_ISig_4 100;
BA_ "GenSigCycleTimeActive" SG_ 1363 ChlrVlvPsnFlt_ISig_4 100;
BA_ "GenSigStartValue" SG_ 1363 ChlrVlvPsnFlt_ISig_4 3;
BA_ "GenSigCycleTime" SG_ 1363 ESSClntTmp_ISig_4 100;
BA_ "GenSigCycleTimeActive" SG_ 1363 ESSClntTmp_ISig_4 100;
BA_ "GenSigStartValue" SG_ 1363 ESSClntTmp_ISig_4 255;
BA_ "GenSigCycleTime" SG_ 1363 EMPmpSpd_ISig_4 100;
BA_ "GenSigCycleTimeActive" SG_ 1363 EMPmpSpd_ISig_4 100;
BA_ "GenSigStartValue" SG_ 1363 EMPmpSpd_ISig_4 255;
BA_ "GenSigCycleTime" SG_ 1363 ESSTmp_ISig_4 100;
BA_ "GenSigCycleTimeActive" SG_ 1363 ESSTmp_ISig_4 100;
BA_ "GenSigStartValue" SG_ 1363 ESSTmp_ISig_4 255;
BA_ "GenSigCycleTime" SG_ 1363 ESSPmpSpd_ISig_4 100;
BA_ "GenSigCycleTimeActive" SG_ 1363 ESSPmpSpd_ISig_4 100;
BA_ "GenSigStartValue" SG_ 1363 ESSPmpSpd_ISig_4 255;
BA_ "GenSigCycleTime" SG_ 1363 ESSTmpTrgt_ISig_4 100;
BA_ "GenSigCycleTimeActive" SG_ 1363 ESSTmpTrgt_ISig_4 100;
BA_ "GenSigStartValue" SG_ 1363 ESSTmpTrgt_ISig_4 255;
BA_ "GenSigCycleTime" SG_ 1363 ChlrUsgRqst_ISig_4 100;
BA_ "GenSigCycleTimeActive" SG_ 1363 ChlrUsgRqst_ISig_4 100;
BA_ "GenSigStartValue" SG_ 1363 ChlrUsgRqst_ISig_4 255;
BA_ "GenSigCycleTime" SG_ 1110 EpsPowerSupplyAck 100;
BA_ "GenSigCycleTimeActive" SG_ 1110 EpsPowerSupplyAck 100;
BA_ "GenSigStartValue" SG_ 1110 EpsPowerSupplyAck 3;
BA_ "GenSigCycleTime" SG_ 1110 ReqEpsAlive 100;
BA_ "GenSigCycleTimeActive" SG_ 1110 ReqEpsAlive 100;
BA_ "GenSigStartValue" SG_ 1110 ReqEpsAlive 3;
BA_ "GenSigSendType" SG_ 1477 HMIIOM_BB2_S28_FCS 7;
BA_ "Platform_VMCU1_Sig" SG_ 1477 HMIIOM_BB2_S28_FCS 1;
BA_ "GenSigCycleTime" SG_ 1422 FasUsrDefinedStorage_rqst_ISig_4 100;
BA_ "GenSigCycleTimeActive" SG_ 1422 FasUsrDefinedStorage_rqst_ISig_4 100;
BA_ "GenSigStartValue" SG_ 1422 FasUsrDefinedStorage_rqst_ISig_4 3;
BA_ "GenSigMaxLatency" SG_ 1422 FasUsrDefinedStorage_rqst_ISig_4 1037;
BA_ "GenSigCycleTime" SG_ 1422 ATC_ButtonIndication 100;
BA_ "GenSigCycleTimeActive" SG_ 1422 ATC_ButtonIndication 100;
BA_ "GenSigMaxLatency" SG_ 1422 ATC_ButtonIndication 1037;
BA_ "GenSigCycleTime" SG_ 1422 FasLowSpeedReturnSetting_rqst_IS 100;
BA_ "GenSigCycleTimeActive" SG_ 1422 FasLowSpeedReturnSetting_rqst_IS 100;
BA_ "GenSigStartValue" SG_ 1422 FasLowSpeedReturnSetting_rqst_IS 31;
BA_ "GenSigMaxLatency" SG_ 1422 FasLowSpeedReturnSetting_rqst_IS 1037;
BA_ "SystemSignalLongSymbol" SG_ 1422 FasLowSpeedReturnSetting_rqst_IS "FasLowSpeedReturnSetting_rqst_ISig_4";
BA_ "GenSigCycleTime" SG_ 1422 FasManualOffsetSetting_rqst_ISig 100;
BA_ "GenSigCycleTimeActive" SG_ 1422 FasManualOffsetSetting_rqst_ISig 100;
BA_ "GenSigStartValue" SG_ 1422 FasManualOffsetSetting_rqst_ISig 31;
BA_ "GenSigMaxLatency" SG_ 1422 FasManualOffsetSetting_rqst_ISig 1037;
BA_ "SystemSignalLongSymbol" SG_ 1422 FasManualOffsetSetting_rqst_ISig "FasManualOffsetSetting_rqst_ISig_4";
BA_ "GenSigCycleTime" SG_ 1422 FasPersonalSettingsButton_rqst_I 100;
BA_ "GenSigCycleTimeActive" SG_ 1422 FasPersonalSettingsButton_rqst_I 100;
BA_ "GenSigStartValue" SG_ 1422 FasPersonalSettingsButton_rqst_I 7;
BA_ "GenSigMaxLatency" SG_ 1422 FasPersonalSettingsButton_rqst_I 1037;
BA_ "SystemSignalLongSymbol" SG_ 1422 FasPersonalSettingsButton_rqst_I "FasPersonalSettingsButton_rqst_ISig_4";
BA_ "GenSigCycleTime" SG_ 1422 FasStiffnessCurveSetting_rqst_IS 100;
BA_ "GenSigCycleTimeActive" SG_ 1422 FasStiffnessCurveSetting_rqst_IS 100;
BA_ "GenSigStartValue" SG_ 1422 FasStiffnessCurveSetting_rqst_IS 31;
BA_ "GenSigMaxLatency" SG_ 1422 FasStiffnessCurveSetting_rqst_IS 1037;
BA_ "SystemSignalLongSymbol" SG_ 1422 FasStiffnessCurveSetting_rqst_IS "FasStiffnessCurveSetting_rqst_ISig_4";
BA_ "GenSigCycleTime" SG_ 1422 FasStiffStraightSetting_rqst_ISi 100;
BA_ "GenSigCycleTimeActive" SG_ 1422 FasStiffStraightSetting_rqst_ISi 100;
BA_ "GenSigStartValue" SG_ 1422 FasStiffStraightSetting_rqst_ISi 31;
BA_ "GenSigMaxLatency" SG_ 1422 FasStiffStraightSetting_rqst_ISi 1037;
BA_ "SystemSignalLongSymbol" SG_ 1422 FasStiffStraightSetting_rqst_ISi "FasStiffStraightSetting_rqst_ISig_4";
BA_ "GenSigCycleTime" SG_ 1422 FasDriver_rqst_ISig_4 100;
BA_ "GenSigCycleTimeActive" SG_ 1422 FasDriver_rqst_ISig_4 100;
BA_ "GenSigStartValue" SG_ 1422 FasDriver_rqst_ISig_4 15;
BA_ "GenSigMaxLatency" SG_ 1422 FasDriver_rqst_ISig_4 1037;
BA_ "GenSigCycleTime" SG_ 1422 FasDampingSetting_rqst_ISig_4 100;
BA_ "GenSigCycleTimeActive" SG_ 1422 FasDampingSetting_rqst_ISig_4 100;
BA_ "GenSigStartValue" SG_ 1422 FasDampingSetting_rqst_ISig_4 31;
BA_ "GenSigMaxLatency" SG_ 1422 FasDampingSetting_rqst_ISig_4 1037;
BA_ "GenSigCycleTime" SG_ 1422 ESC_ButtonIndication2 100;
BA_ "GenSigCycleTimeActive" SG_ 1422 ESC_ButtonIndication2 100;
BA_ "GenSigMaxLatency" SG_ 1422 ESC_ButtonIndication2 1037;
BA_ "GenSigCycleTime" SG_ 1422 TCS_ButtonIndication 100;
BA_ "GenSigCycleTimeActive" SG_ 1422 TCS_ButtonIndication 100;
BA_ "GenSigMaxLatency" SG_ 1422 TCS_ButtonIndication 1037;
BA_ "GenSigCycleTime" SG_ 1422 ABS_ButtonIndication 100;
BA_ "GenSigCycleTimeActive" SG_ 1422 ABS_ButtonIndication 100;
BA_ "GenSigMaxLatency" SG_ 1422 ABS_ButtonIndication 1037;
BA_ "GenSigCycleTime" SG_ 1421 ESCOff_DeviceIndication 100;
BA_ "GenSigCycleTimeActive" SG_ 1421 ESCOff_DeviceIndication 100;
BA_ "GenSigStartValue" SG_ 1421 ESCOff_DeviceIndication 3;
BA_ "GenSigMaxLatency" SG_ 1421 ESCOff_DeviceIndication 102;
BA_ "Platform_VMCU1_Sig" SG_ 1421 ESCOff_DeviceIndication 1;
BA_ "GenSigCycleTime" SG_ 1421 CCUnderSpeedRequest 100;
BA_ "GenSigCycleTimeActive" SG_ 1421 CCUnderSpeedRequest 100;
BA_ "GenSigStartValue" SG_ 1421 CCUnderSpeedRequest 65535;
BA_ "GenSigCycleTime" SG_ 1421 RollerBenchGUIDeviceStatus 100;
BA_ "GenSigCycleTimeActive" SG_ 1421 RollerBenchGUIDeviceStatus 100;
BA_ "GenSigStartValue" SG_ 1421 RollerBenchGUIDeviceStatus 7;
BA_ "GenSigMaxLatency" SG_ 1421 RollerBenchGUIDeviceStatus 102;
BA_ "Platform_VMCU1_Sig" SG_ 1421 RollerBenchGUIDeviceStatus 1;
BA_ "GenSigCycleTime" SG_ 1421 DHCSetSpeedAdjustRequest 100;
BA_ "GenSigCycleTimeActive" SG_ 1421 DHCSetSpeedAdjustRequest 100;
BA_ "GenSigStartValue" SG_ 1421 DHCSetSpeedAdjustRequest 7;
BA_ "GenSigCycleTime" SG_ 1421 TemporaryRSLDeviceIndication 100;
BA_ "GenSigCycleTimeActive" SG_ 1421 TemporaryRSLDeviceIndication 100;
BA_ "GenSigStartValue" SG_ 1421 TemporaryRSLDeviceIndication 3;
BA_ "GenSigCycleTime" SG_ 1421 AutomaticCMenableStatus 100;
BA_ "GenSigCycleTimeActive" SG_ 1421 AutomaticCMenableStatus 100;
BA_ "GenSigStartValue" SG_ 1421 AutomaticCMenableStatus 3;
BA_ "GenSigMaxLatency" SG_ 1421 AutomaticCMenableStatus 102;
BA_ "Platform_VMCU1_Sig" SG_ 1421 AutomaticCMenableStatus 1;
BA_ "GenSigCycleTime" SG_ 1421 SetDaylightSaving_rqst 100;
BA_ "GenSigCycleTimeActive" SG_ 1421 SetDaylightSaving_rqst 100;
BA_ "GenSigStartValue" SG_ 1421 SetDaylightSaving_rqst 3;
BA_ "GenSigCycleTime" SG_ 1421 CamerasPowerSupply_rqst_ISig_4 100;
BA_ "GenSigCycleTimeActive" SG_ 1421 CamerasPowerSupply_rqst_ISig_4 100;
BA_ "GenSigStartValue" SG_ 1421 CamerasPowerSupply_rqst_ISig_4 3;
BA_ "GenSigCycleTime" SG_ 1421 AFSActiveAllowed_GUIrqst 100;
BA_ "GenSigCycleTimeActive" SG_ 1421 AFSActiveAllowed_GUIrqst 100;
BA_ "GenSigStartValue" SG_ 1421 AFSActiveAllowed_GUIrqst 3;
BA_ "GenSigSendType" SG_ 518 AdasisMapData_ISig_4 1;
BA_ "GenSigCycleTime" SG_ 518 AdasisMapData_ISig_4 100;
BA_ "GenSigCycleTimeActive" SG_ 518 AdasisMapData_ISig_4 100;
BA_ "Platform_VMCU1_Sig" SG_ 518 AdasisMapData_ISig_4 1;
BA_ "GenSigSendType" SG_ 1397 HMIIOM_BB2_36S_FCS 7;
BA_ "Platform_VMCU1_Sig" SG_ 1397 HMIIOM_BB2_36S_FCS 1;
BA_ "GenSigSendType" SG_ 1396 SEM_DisplayText_stat_ISig_4 1;
BA_ "GenSigMaxLatency" SG_ 1396 SEM_DisplayText_stat_ISig_4 170;
BA_ "Platform_VMCU1_Sig" SG_ 1396 SEM_DisplayText_stat_ISig_4 1;
BA_ "GenSigSendType" SG_ 952 HMIIOM_BB2_35S_FCS 7;
BA_ "Platform_VMCU1_Sig" SG_ 952 HMIIOM_BB2_35S_FCS 1;
BA_ "GenSigSendType" SG_ 949 MediaSourcesListRsp_sg_UB_ISig_4 7;
BA_ "Platform_VMCU1_Sig" SG_ 949 MediaSourcesListRsp_sg_UB_ISig_4 1;
BA_ "GenSigSendType" SG_ 949 MediaSourcesListRsp_SrcAttrib_IS 1;
BA_ "GenSigMaxLatency" SG_ 949 MediaSourcesListRsp_SrcAttrib_IS 100;
BA_ "NeedsUpdateBit" SG_ 949 MediaSourcesListRsp_SrcAttrib_IS 1;
BA_ "Platform_VMCU1_Sig" SG_ 949 MediaSourcesListRsp_SrcAttrib_IS 1;
BA_ "SystemSignalLongSymbol" SG_ 949 MediaSourcesListRsp_SrcAttrib_IS "MediaSourcesListRsp_SrcAttrib_ISig_4";
BA_ "GenSigSendType" SG_ 949 MediaSourcesListRsp_SInfo_ISig_4 1;
BA_ "GenSigStartValue" SG_ 949 MediaSourcesListRsp_SInfo_ISig_4 3;
BA_ "GenSigMaxLatency" SG_ 949 MediaSourcesListRsp_SInfo_ISig_4 100;
BA_ "NeedsUpdateBit" SG_ 949 MediaSourcesListRsp_SInfo_ISig_4 1;
BA_ "Platform_VMCU1_Sig" SG_ 949 MediaSourcesListRsp_SInfo_ISig_4 1;
BA_ "GenSigSendType" SG_ 949 MediaSourcesListRsp_Name_ISig_4 1;
BA_ "GenSigMaxLatency" SG_ 949 MediaSourcesListRsp_Name_ISig_4 100;
BA_ "NeedsUpdateBit" SG_ 949 MediaSourcesListRsp_Name_ISig_4 1;
BA_ "Platform_VMCU1_Sig" SG_ 949 MediaSourcesListRsp_Name_ISig_4 1;
BA_ "GenSigSendType" SG_ 949 MediaSourcesListRsp_PCI_ISig_4 1;
BA_ "GenSigMaxLatency" SG_ 949 MediaSourcesListRsp_PCI_ISig_4 100;
BA_ "NeedsUpdateBit" SG_ 949 MediaSourcesListRsp_PCI_ISig_4 1;
BA_ "Platform_VMCU1_Sig" SG_ 949 MediaSourcesListRsp_PCI_ISig_4 1;
BA_ "GenSigSendType" SG_ 949 MediaSourcesListRsp_ItemID_ISig_ 1;
BA_ "GenSigMaxLatency" SG_ 949 MediaSourcesListRsp_ItemID_ISig_ 100;
BA_ "NeedsUpdateBit" SG_ 949 MediaSourcesListRsp_ItemID_ISig_ 1;
BA_ "Platform_VMCU1_Sig" SG_ 949 MediaSourcesListRsp_ItemID_ISig_ 1;
BA_ "SystemSignalLongSymbol" SG_ 949 MediaSourcesListRsp_ItemID_ISig_ "MediaSourcesListRsp_ItemID_ISig_4";
BA_ "GenSigSendType" SG_ 967 MediaSourcesListNPRsp_ISig_4 1;
BA_ "GenSigMaxLatency" SG_ 967 MediaSourcesListNPRsp_ISig_4 50;
BA_ "NeedsUpdateBit" SG_ 967 MediaSourcesListNPRsp_ISig_4 1;
BA_ "Platform_VMCU1_Sig" SG_ 967 MediaSourcesListNPRsp_ISig_4 1;
BA_ "GenSigSendType" SG_ 967 MediaSourcesListNPRsp_UB_ISig_4 7;
BA_ "Platform_VMCU1_Sig" SG_ 967 MediaSourcesListNPRsp_UB_ISig_4 1;
BA_ "GenSigCycleTime" SG_ 822 SEMMediaSourceAvail_Source04_ISi 100;
BA_ "GenSigCycleTimeActive" SG_ 822 SEMMediaSourceAvail_Source04_ISi 100;
BA_ "Platform_VMCU1_Sig" SG_ 822 SEMMediaSourceAvail_Source04_ISi 1;
BA_ "SystemSignalLongSymbol" SG_ 822 SEMMediaSourceAvail_Source04_ISi "SEMMediaSourceAvail_Source04_ISig_4";
BA_ "GenSigCycleTime" SG_ 822 SEMMediaSourceAvail_Source10_ISi 100;
BA_ "GenSigCycleTimeActive" SG_ 822 SEMMediaSourceAvail_Source10_ISi 100;
BA_ "Platform_VMCU1_Sig" SG_ 822 SEMMediaSourceAvail_Source10_ISi 1;
BA_ "SystemSignalLongSymbol" SG_ 822 SEMMediaSourceAvail_Source10_ISi "SEMMediaSourceAvail_Source10_ISig_4";
BA_ "GenSigCycleTime" SG_ 822 SEMMediaSourceAvail_SInfo_ISig_4 100;
BA_ "GenSigCycleTimeActive" SG_ 822 SEMMediaSourceAvail_SInfo_ISig_4 100;
BA_ "GenSigStartValue" SG_ 822 SEMMediaSourceAvail_SInfo_ISig_4 3;
BA_ "Platform_VMCU1_Sig" SG_ 822 SEMMediaSourceAvail_SInfo_ISig_4 1;
BA_ "GenSigCycleTime" SG_ 822 SEM_PresetIndicationCmd_ISig_4 100;
BA_ "GenSigCycleTimeActive" SG_ 822 SEM_PresetIndicationCmd_ISig_4 100;
BA_ "GenSigStartValue" SG_ 822 SEM_PresetIndicationCmd_ISig_4 63;
BA_ "Platform_VMCU1_Sig" SG_ 822 SEM_PresetIndicationCmd_ISig_4 1;
BA_ "GenSigCycleTime" SG_ 822 SEMMediaSourceAvail_Source09_ISi 100;
BA_ "GenSigCycleTimeActive" SG_ 822 SEMMediaSourceAvail_Source09_ISi 100;
BA_ "Platform_VMCU1_Sig" SG_ 822 SEMMediaSourceAvail_Source09_ISi 1;
BA_ "SystemSignalLongSymbol" SG_ 822 SEMMediaSourceAvail_Source09_ISi "SEMMediaSourceAvail_Source09_ISig_4";
BA_ "GenSigCycleTime" SG_ 822 SEMMediaSourceAvail_Source12_ISi 100;
BA_ "GenSigCycleTimeActive" SG_ 822 SEMMediaSourceAvail_Source12_ISi 100;
BA_ "Platform_VMCU1_Sig" SG_ 822 SEMMediaSourceAvail_Source12_ISi 1;
BA_ "SystemSignalLongSymbol" SG_ 822 SEMMediaSourceAvail_Source12_ISi "SEMMediaSourceAvail_Source12_ISig_4";
BA_ "GenSigCycleTime" SG_ 822 SEMMediaSourceAvail_Source07_ISi 100;
BA_ "GenSigCycleTimeActive" SG_ 822 SEMMediaSourceAvail_Source07_ISi 100;
BA_ "Platform_VMCU1_Sig" SG_ 822 SEMMediaSourceAvail_Source07_ISi 1;
BA_ "SystemSignalLongSymbol" SG_ 822 SEMMediaSourceAvail_Source07_ISi "SEMMediaSourceAvail_Source07_ISig_4";
BA_ "GenSigCycleTime" SG_ 822 SEMMediaSourceAvail_Source03_ISi 100;
BA_ "GenSigCycleTimeActive" SG_ 822 SEMMediaSourceAvail_Source03_ISi 100;
BA_ "Platform_VMCU1_Sig" SG_ 822 SEMMediaSourceAvail_Source03_ISi 1;
BA_ "SystemSignalLongSymbol" SG_ 822 SEMMediaSourceAvail_Source03_ISi "SEMMediaSourceAvail_Source03_ISig_4";
BA_ "GenSigCycleTime" SG_ 822 SEMMediaSourceAvail_Source11_ISi 100;
BA_ "GenSigCycleTimeActive" SG_ 822 SEMMediaSourceAvail_Source11_ISi 100;
BA_ "Platform_VMCU1_Sig" SG_ 822 SEMMediaSourceAvail_Source11_ISi 1;
BA_ "SystemSignalLongSymbol" SG_ 822 SEMMediaSourceAvail_Source11_ISi "SEMMediaSourceAvail_Source11_ISig_4";
BA_ "GenSigCycleTime" SG_ 822 SEM_AudioVolValIndCmd_ISig_4 100;
BA_ "GenSigCycleTimeActive" SG_ 822 SEM_AudioVolValIndCmd_ISig_4 100;
BA_ "Platform_VMCU1_Sig" SG_ 822 SEM_AudioVolValIndCmd_ISig_4 1;
BA_ "GenSigCycleTime" SG_ 822 SEMMediaSourceAvail_Source02_ISi 100;
BA_ "GenSigCycleTimeActive" SG_ 822 SEMMediaSourceAvail_Source02_ISi 100;
BA_ "Platform_VMCU1_Sig" SG_ 822 SEMMediaSourceAvail_Source02_ISi 1;
BA_ "SystemSignalLongSymbol" SG_ 822 SEMMediaSourceAvail_Source02_ISi "SEMMediaSourceAvail_Source02_ISig_4";
BA_ "GenSigCycleTime" SG_ 822 AudioSourceStat_ISig_4 100;
BA_ "GenSigCycleTimeActive" SG_ 822 AudioSourceStat_ISig_4 100;
BA_ "GenSigStartValue" SG_ 822 AudioSourceStat_ISig_4 15;
BA_ "Platform_VMCU1_Sig" SG_ 822 AudioSourceStat_ISig_4 1;
BA_ "GenSigCycleTime" SG_ 822 SEMMediaSourceAvail_Source06_ISi 100;
BA_ "GenSigCycleTimeActive" SG_ 822 SEMMediaSourceAvail_Source06_ISi 100;
BA_ "Platform_VMCU1_Sig" SG_ 822 SEMMediaSourceAvail_Source06_ISi 1;
BA_ "SystemSignalLongSymbol" SG_ 822 SEMMediaSourceAvail_Source06_ISi "SEMMediaSourceAvail_Source06_ISig_4";
BA_ "GenSigCycleTime" SG_ 822 SEMMediaSourceAvail_Source00_ISi 100;
BA_ "GenSigCycleTimeActive" SG_ 822 SEMMediaSourceAvail_Source00_ISi 100;
BA_ "Platform_VMCU1_Sig" SG_ 822 SEMMediaSourceAvail_Source00_ISi 1;
BA_ "SystemSignalLongSymbol" SG_ 822 SEMMediaSourceAvail_Source00_ISi "SEMMediaSourceAvail_Source00_ISig_4";
BA_ "GenSigCycleTime" SG_ 822 SEMMediaSourceAvail_Source01_ISi 100;
BA_ "GenSigCycleTimeActive" SG_ 822 SEMMediaSourceAvail_Source01_ISi 100;
BA_ "Platform_VMCU1_Sig" SG_ 822 SEMMediaSourceAvail_Source01_ISi 1;
BA_ "SystemSignalLongSymbol" SG_ 822 SEMMediaSourceAvail_Source01_ISi "SEMMediaSourceAvail_Source01_ISig_4";
BA_ "GenSigCycleTime" SG_ 822 SEMMediaSourceAvail_Source08_ISi 100;
BA_ "GenSigCycleTimeActive" SG_ 822 SEMMediaSourceAvail_Source08_ISi 100;
BA_ "Platform_VMCU1_Sig" SG_ 822 SEMMediaSourceAvail_Source08_ISi 1;
BA_ "SystemSignalLongSymbol" SG_ 822 SEMMediaSourceAvail_Source08_ISi "SEMMediaSourceAvail_Source08_ISig_4";
BA_ "GenSigCycleTime" SG_ 822 SEM_AudioMuteStat_ISig_4 100;
BA_ "GenSigCycleTimeActive" SG_ 822 SEM_AudioMuteStat_ISig_4 100;
BA_ "GenSigStartValue" SG_ 822 SEM_AudioMuteStat_ISig_4 7;
BA_ "Platform_VMCU1_Sig" SG_ 822 SEM_AudioMuteStat_ISig_4 1;
BA_ "GenSigCycleTime" SG_ 822 SEMMediaSourceAvail_Source13_ISi 100;
BA_ "GenSigCycleTimeActive" SG_ 822 SEMMediaSourceAvail_Source13_ISi 100;
BA_ "Platform_VMCU1_Sig" SG_ 822 SEMMediaSourceAvail_Source13_ISi 1;
BA_ "SystemSignalLongSymbol" SG_ 822 SEMMediaSourceAvail_Source13_ISi "SEMMediaSourceAvail_Source13_ISig_4";
BA_ "GenSigCycleTime" SG_ 822 SEMMediaSourceAvail_Source05_ISi 100;
BA_ "GenSigCycleTimeActive" SG_ 822 SEMMediaSourceAvail_Source05_ISi 100;
BA_ "Platform_VMCU1_Sig" SG_ 822 SEMMediaSourceAvail_Source05_ISi 1;
BA_ "SystemSignalLongSymbol" SG_ 822 SEMMediaSourceAvail_Source05_ISi "SEMMediaSourceAvail_Source05_ISig_4";
BA_ "GenSigSendType" SG_ 1337 TPMPosOfWMReq_sg_UB_ISig_4 7;
BA_ "GenSigCycleTime" SG_ 1337 TPMPosOfWMReq_sg_UB_ISig_4 100;
BA_ "GenSigCycleTimeActive" SG_ 1337 TPMPosOfWMReq_sg_UB_ISig_4 100;
BA_ "Platform_VMCU1_Sig" SG_ 1337 TPMPosOfWMReq_sg_UB_ISig_4 1;
BA_ "GenSigCycleTime" SG_ 1337 TPMUnmateTrailerReq_ISig_4 100;
BA_ "GenSigCycleTimeActive" SG_ 1337 TPMUnmateTrailerReq_ISig_4 100;
BA_ "GenSigStartValue" SG_ 1337 TPMUnmateTrailerReq_ISig_4 3;
BA_ "NeedsUpdateBit" SG_ 1337 TPMUnmateTrailerReq_ISig_4 1;
BA_ "Platform_VMCU1_Sig" SG_ 1337 TPMUnmateTrailerReq_ISig_4 1;
BA_ "GenSigCycleTime" SG_ 1337 TPMSetAxleRefPres_Axle4_ISig_4 100;
BA_ "GenSigCycleTimeActive" SG_ 1337 TPMSetAxleRefPres_Axle4_ISig_4 100;
BA_ "GenSigStartValue" SG_ 1337 TPMSetAxleRefPres_Axle4_ISig_4 255;
BA_ "NeedsUpdateBit" SG_ 1337 TPMSetAxleRefPres_Axle4_ISig_4 1;
BA_ "Platform_VMCU1_Sig" SG_ 1337 TPMSetAxleRefPres_Axle4_ISig_4 1;
BA_ "GenSigSendType" SG_ 1337 TPMMateTrailerReq_UB_ISig_4 7;
BA_ "GenSigCycleTime" SG_ 1337 TPMMateTrailerReq_UB_ISig_4 100;
BA_ "GenSigCycleTimeActive" SG_ 1337 TPMMateTrailerReq_UB_ISig_4 100;
BA_ "Platform_VMCU1_Sig" SG_ 1337 TPMMateTrailerReq_UB_ISig_4 1;
BA_ "GenSigSendType" SG_ 1337 TPMSetAxleRefPres_sg_UB_ISig_4 7;
BA_ "GenSigCycleTime" SG_ 1337 TPMSetAxleRefPres_sg_UB_ISig_4 100;
BA_ "GenSigCycleTimeActive" SG_ 1337 TPMSetAxleRefPres_sg_UB_ISig_4 100;
BA_ "Platform_VMCU1_Sig" SG_ 1337 TPMSetAxleRefPres_sg_UB_ISig_4 1;
BA_ "GenSigCycleTime" SG_ 1337 TPMPosOfWMReq_VehiclePos_ISig_4 100;
BA_ "GenSigCycleTimeActive" SG_ 1337 TPMPosOfWMReq_VehiclePos_ISig_4 100;
BA_ "GenSigStartValue" SG_ 1337 TPMPosOfWMReq_VehiclePos_ISig_4 7;
BA_ "NeedsUpdateBit" SG_ 1337 TPMPosOfWMReq_VehiclePos_ISig_4 1;
BA_ "Platform_VMCU1_Sig" SG_ 1337 TPMPosOfWMReq_VehiclePos_ISig_4 1;
BA_ "GenSigCycleTime" SG_ 1337 TPMSetAxleRefPres_Axle1_ISig_4 100;
BA_ "GenSigCycleTimeActive" SG_ 1337 TPMSetAxleRefPres_Axle1_ISig_4 100;
BA_ "GenSigStartValue" SG_ 1337 TPMSetAxleRefPres_Axle1_ISig_4 255;
BA_ "NeedsUpdateBit" SG_ 1337 TPMSetAxleRefPres_Axle1_ISig_4 1;
BA_ "Platform_VMCU1_Sig" SG_ 1337 TPMSetAxleRefPres_Axle1_ISig_4 1;
BA_ "GenSigCycleTime" SG_ 1337 TPMSetAxleRefPres_Axle2_ISig_4 100;
BA_ "GenSigCycleTimeActive" SG_ 1337 TPMSetAxleRefPres_Axle2_ISig_4 100;
BA_ "GenSigStartValue" SG_ 1337 TPMSetAxleRefPres_Axle2_ISig_4 255;
BA_ "NeedsUpdateBit" SG_ 1337 TPMSetAxleRefPres_Axle2_ISig_4 1;
BA_ "Platform_VMCU1_Sig" SG_ 1337 TPMSetAxleRefPres_Axle2_ISig_4 1;
BA_ "GenSigCycleTime" SG_ 1337 TPMSetAxleRefPres_Axle3_ISig_4 100;
BA_ "GenSigCycleTimeActive" SG_ 1337 TPMSetAxleRefPres_Axle3_ISig_4 100;
BA_ "GenSigStartValue" SG_ 1337 TPMSetAxleRefPres_Axle3_ISig_4 255;
BA_ "NeedsUpdateBit" SG_ 1337 TPMSetAxleRefPres_Axle3_ISig_4 1;
BA_ "Platform_VMCU1_Sig" SG_ 1337 TPMSetAxleRefPres_Axle3_ISig_4 1;
BA_ "GenSigCycleTime" SG_ 1337 TPMMateTrailerReq_ISig_4 100;
BA_ "GenSigCycleTimeActive" SG_ 1337 TPMMateTrailerReq_ISig_4 100;
BA_ "GenSigStartValue" SG_ 1337 TPMMateTrailerReq_ISig_4 3;
BA_ "NeedsUpdateBit" SG_ 1337 TPMMateTrailerReq_ISig_4 1;
BA_ "Platform_VMCU1_Sig" SG_ 1337 TPMMateTrailerReq_ISig_4 1;
BA_ "GenSigCycleTime" SG_ 1337 TPMPosOfWMReq_TireId_ISig_4 100;
BA_ "GenSigCycleTimeActive" SG_ 1337 TPMPosOfWMReq_TireId_ISig_4 100;
BA_ "NeedsUpdateBit" SG_ 1337 TPMPosOfWMReq_TireId_ISig_4 1;
BA_ "Platform_VMCU1_Sig" SG_ 1337 TPMPosOfWMReq_TireId_ISig_4 1;
BA_ "GenSigSendType" SG_ 1337 TPMUnmateTrailerReq_UB_ISig_4 7;
BA_ "GenSigCycleTime" SG_ 1337 TPMUnmateTrailerReq_UB_ISig_4 100;
BA_ "GenSigCycleTimeActive" SG_ 1337 TPMUnmateTrailerReq_UB_ISig_4 100;
BA_ "Platform_VMCU1_Sig" SG_ 1337 TPMUnmateTrailerReq_UB_ISig_4 1;
BA_ "GenSigCycleTime" SG_ 1337 TPMSetAxleRefPres_Axle5_ISig_4 100;
BA_ "GenSigCycleTimeActive" SG_ 1337 TPMSetAxleRefPres_Axle5_ISig_4 100;
BA_ "GenSigStartValue" SG_ 1337 TPMSetAxleRefPres_Axle5_ISig_4 255;
BA_ "NeedsUpdateBit" SG_ 1337 TPMSetAxleRefPres_Axle5_ISig_4 1;
BA_ "Platform_VMCU1_Sig" SG_ 1337 TPMSetAxleRefPres_Axle5_ISig_4 1;
BA_ "GenSigCycleTime" SG_ 1337 TPMSetAxleRefPres_VehiclePos_ISi 100;
BA_ "GenSigCycleTimeActive" SG_ 1337 TPMSetAxleRefPres_VehiclePos_ISi 100;
BA_ "GenSigStartValue" SG_ 1337 TPMSetAxleRefPres_VehiclePos_ISi 7;
BA_ "NeedsUpdateBit" SG_ 1337 TPMSetAxleRefPres_VehiclePos_ISi 1;
BA_ "Platform_VMCU1_Sig" SG_ 1337 TPMSetAxleRefPres_VehiclePos_ISi 1;
BA_ "SystemSignalLongSymbol" SG_ 1337 TPMSetAxleRefPres_VehiclePos_ISi "TPMSetAxleRefPres_VehiclePos_ISig_4";
BA_ "GenSigSendType" SG_ 1336 TPMSetPresThresCfg_sg_UB_ISig_4 7;
BA_ "GenSigCycleTime" SG_ 1336 TPMSetPresThresCfg_sg_UB_ISig_4 100;
BA_ "GenSigCycleTimeActive" SG_ 1336 TPMSetPresThresCfg_sg_UB_ISig_4 100;
BA_ "Platform_VMCU1_Sig" SG_ 1336 TPMSetPresThresCfg_sg_UB_ISig_4 1;
BA_ "GenSigCycleTime" SG_ 1336 TPMSetAxleTireConfig_Axle4_ISig_ 100;
BA_ "GenSigCycleTimeActive" SG_ 1336 TPMSetAxleTireConfig_Axle4_ISig_ 100;
BA_ "GenSigStartValue" SG_ 1336 TPMSetAxleTireConfig_Axle4_ISig_ 7;
BA_ "NeedsUpdateBit" SG_ 1336 TPMSetAxleTireConfig_Axle4_ISig_ 1;
BA_ "Platform_VMCU1_Sig" SG_ 1336 TPMSetAxleTireConfig_Axle4_ISig_ 1;
BA_ "SystemSignalLongSymbol" SG_ 1336 TPMSetAxleTireConfig_Axle4_ISig_ "TPMSetAxleTireConfig_Axle4_ISig_4";
BA_ "GenSigCycleTime" SG_ 1336 TPMSetAxleTireConfig_Axle5_ISig_ 100;
BA_ "GenSigCycleTimeActive" SG_ 1336 TPMSetAxleTireConfig_Axle5_ISig_ 100;
BA_ "GenSigStartValue" SG_ 1336 TPMSetAxleTireConfig_Axle5_ISig_ 7;
BA_ "NeedsUpdateBit" SG_ 1336 TPMSetAxleTireConfig_Axle5_ISig_ 1;
BA_ "Platform_VMCU1_Sig" SG_ 1336 TPMSetAxleTireConfig_Axle5_ISig_ 1;
BA_ "SystemSignalLongSymbol" SG_ 1336 TPMSetAxleTireConfig_Axle5_ISig_ "TPMSetAxleTireConfig_Axle5_ISig_4";
BA_ "GenSigCycleTime" SG_ 1336 TPMSetPresThresCfg_VehiclePos_IS 100;
BA_ "GenSigCycleTimeActive" SG_ 1336 TPMSetPresThresCfg_VehiclePos_IS 100;
BA_ "GenSigStartValue" SG_ 1336 TPMSetPresThresCfg_VehiclePos_IS 7;
BA_ "NeedsUpdateBit" SG_ 1336 TPMSetPresThresCfg_VehiclePos_IS 1;
BA_ "Platform_VMCU1_Sig" SG_ 1336 TPMSetPresThresCfg_VehiclePos_IS 1;
BA_ "SystemSignalLongSymbol" SG_ 1336 TPMSetPresThresCfg_VehiclePos_IS "TPMSetPresThresCfg_VehiclePos_ISig_4";
BA_ "GenSigCycleTime" SG_ 1336 TPMSetPresThresCfg_ExtOverPres_I 100;
BA_ "GenSigCycleTimeActive" SG_ 1336 TPMSetPresThresCfg_ExtOverPres_I 100;
BA_ "GenSigStartValue" SG_ 1336 TPMSetPresThresCfg_ExtOverPres_I 255;
BA_ "NeedsUpdateBit" SG_ 1336 TPMSetPresThresCfg_ExtOverPres_I 1;
BA_ "Platform_VMCU1_Sig" SG_ 1336 TPMSetPresThresCfg_ExtOverPres_I 1;
BA_ "SystemSignalLongSymbol" SG_ 1336 TPMSetPresThresCfg_ExtOverPres_I "TPMSetPresThresCfg_ExtOverPres_ISig_4";
BA_ "GenSigCycleTime" SG_ 1336 TPMSetAxleTireConfig_Axle2_ISig_ 100;
BA_ "GenSigCycleTimeActive" SG_ 1336 TPMSetAxleTireConfig_Axle2_ISig_ 100;
BA_ "GenSigStartValue" SG_ 1336 TPMSetAxleTireConfig_Axle2_ISig_ 7;
BA_ "NeedsUpdateBit" SG_ 1336 TPMSetAxleTireConfig_Axle2_ISig_ 1;
BA_ "Platform_VMCU1_Sig" SG_ 1336 TPMSetAxleTireConfig_Axle2_ISig_ 1;
BA_ "SystemSignalLongSymbol" SG_ 1336 TPMSetAxleTireConfig_Axle2_ISig_ "TPMSetAxleTireConfig_Axle2_ISig_4";
BA_ "GenSigCycleTime" SG_ 1336 TPMSetAxleTireConfig_VehiclePos_ 100;
BA_ "GenSigCycleTimeActive" SG_ 1336 TPMSetAxleTireConfig_VehiclePos_ 100;
BA_ "GenSigStartValue" SG_ 1336 TPMSetAxleTireConfig_VehiclePos_ 7;
BA_ "NeedsUpdateBit" SG_ 1336 TPMSetAxleTireConfig_VehiclePos_ 1;
BA_ "Platform_VMCU1_Sig" SG_ 1336 TPMSetAxleTireConfig_VehiclePos_ 1;
BA_ "SystemSignalLongSymbol" SG_ 1336 TPMSetAxleTireConfig_VehiclePos_ "TPMSetAxleTireConfig_VehiclePos_ISig_4";
BA_ "GenSigCycleTime" SG_ 1336 TPMSetAxleTireConfig_Axle3_ISig_ 100;
BA_ "GenSigCycleTimeActive" SG_ 1336 TPMSetAxleTireConfig_Axle3_ISig_ 100;
BA_ "GenSigStartValue" SG_ 1336 TPMSetAxleTireConfig_Axle3_ISig_ 7;
BA_ "NeedsUpdateBit" SG_ 1336 TPMSetAxleTireConfig_Axle3_ISig_ 1;
BA_ "Platform_VMCU1_Sig" SG_ 1336 TPMSetAxleTireConfig_Axle3_ISig_ 1;
BA_ "SystemSignalLongSymbol" SG_ 1336 TPMSetAxleTireConfig_Axle3_ISig_ "TPMSetAxleTireConfig_Axle3_ISig_4";
BA_ "GenSigCycleTime" SG_ 1336 TPMSetAxleTireConfig_Axle1_ISig_ 100;
BA_ "GenSigCycleTimeActive" SG_ 1336 TPMSetAxleTireConfig_Axle1_ISig_ 100;
BA_ "GenSigStartValue" SG_ 1336 TPMSetAxleTireConfig_Axle1_ISig_ 7;
BA_ "NeedsUpdateBit" SG_ 1336 TPMSetAxleTireConfig_Axle1_ISig_ 1;
BA_ "Platform_VMCU1_Sig" SG_ 1336 TPMSetAxleTireConfig_Axle1_ISig_ 1;
BA_ "SystemSignalLongSymbol" SG_ 1336 TPMSetAxleTireConfig_Axle1_ISig_ "TPMSetAxleTireConfig_Axle1_ISig_4";
BA_ "GenSigCycleTime" SG_ 1336 TPMSetPresThresCfg_AxleNr_ISig_4 100;
BA_ "GenSigCycleTimeActive" SG_ 1336 TPMSetPresThresCfg_AxleNr_ISig_4 100;
BA_ "GenSigStartValue" SG_ 1336 TPMSetPresThresCfg_AxleNr_ISig_4 7;
BA_ "NeedsUpdateBit" SG_ 1336 TPMSetPresThresCfg_AxleNr_ISig_4 1;
BA_ "Platform_VMCU1_Sig" SG_ 1336 TPMSetPresThresCfg_AxleNr_ISig_4 1;
BA_ "GenSigSendType" SG_ 1336 TPMSetAxleTireConfig_sg_UB_ISig_ 7;
BA_ "GenSigCycleTime" SG_ 1336 TPMSetAxleTireConfig_sg_UB_ISig_ 100;
BA_ "GenSigCycleTimeActive" SG_ 1336 TPMSetAxleTireConfig_sg_UB_ISig_ 100;
BA_ "Platform_VMCU1_Sig" SG_ 1336 TPMSetAxleTireConfig_sg_UB_ISig_ 1;
BA_ "SystemSignalLongSymbol" SG_ 1336 TPMSetAxleTireConfig_sg_UB_ISig_ "TPMSetAxleTireConfig_sg_UB_ISig_4";
BA_ "GenSigCycleTime" SG_ 1336 TPMSetPresThresCfg_OverPres_ISig 100;
BA_ "GenSigCycleTimeActive" SG_ 1336 TPMSetPresThresCfg_OverPres_ISig 100;
BA_ "GenSigStartValue" SG_ 1336 TPMSetPresThresCfg_OverPres_ISig 255;
BA_ "NeedsUpdateBit" SG_ 1336 TPMSetPresThresCfg_OverPres_ISig 1;
BA_ "Platform_VMCU1_Sig" SG_ 1336 TPMSetPresThresCfg_OverPres_ISig 1;
BA_ "SystemSignalLongSymbol" SG_ 1336 TPMSetPresThresCfg_OverPres_ISig "TPMSetPresThresCfg_OverPres_ISig_4";
BA_ "GenSigCycleTime" SG_ 1336 TPMSetPresThresCfg_ExtUnderPres_ 100;
BA_ "GenSigCycleTimeActive" SG_ 1336 TPMSetPresThresCfg_ExtUnderPres_ 100;
BA_ "GenSigStartValue" SG_ 1336 TPMSetPresThresCfg_ExtUnderPres_ 255;
BA_ "NeedsUpdateBit" SG_ 1336 TPMSetPresThresCfg_ExtUnderPres_ 1;
BA_ "Platform_VMCU1_Sig" SG_ 1336 TPMSetPresThresCfg_ExtUnderPres_ 1;
BA_ "SystemSignalLongSymbol" SG_ 1336 TPMSetPresThresCfg_ExtUnderPres_ "TPMSetPresThresCfg_ExtUnderPres_ISig_4";
BA_ "GenSigCycleTime" SG_ 1336 TPMSetPresThresCfg_UnderPres_ISi 100;
BA_ "GenSigCycleTimeActive" SG_ 1336 TPMSetPresThresCfg_UnderPres_ISi 100;
BA_ "GenSigStartValue" SG_ 1336 TPMSetPresThresCfg_UnderPres_ISi 255;
BA_ "NeedsUpdateBit" SG_ 1336 TPMSetPresThresCfg_UnderPres_ISi 1;
BA_ "Platform_VMCU1_Sig" SG_ 1336 TPMSetPresThresCfg_UnderPres_ISi 1;
BA_ "SystemSignalLongSymbol" SG_ 1336 TPMSetPresThresCfg_UnderPres_ISi "TPMSetPresThresCfg_UnderPres_ISig_4";
BA_ "GenSigSendType" SG_ 1476 HillDataPkgTGW_ISig_4 1;
BA_ "GenSigMaxLatency" SG_ 1476 HillDataPkgTGW_ISig_4 2500;
BA_ "Platform_VMCU1_Sig" SG_ 1476 HillDataPkgTGW_ISig_4 1;
BA_ "GenSigCycleTime" SG_ 837 TPMIndicationLightReq 100;
BA_ "GenSigCycleTimeActive" SG_ 837 TPMIndicationLightReq 100;
BA_ "GenSigStartValue" SG_ 837 TPMIndicationLightReq 3;
BA_ "GenSigSendType" SG_ 837 TPMIndicationLightReq_UB 7;
BA_ "GenSigCycleTime" SG_ 837 TPMIndicationLightReq_UB 100;
BA_ "GenSigCycleTimeActive" SG_ 837 TPMIndicationLightReq_UB 100;
BA_ "GenSigCycleTime" SG_ 837 Regeneration_DeviceInd 100;
BA_ "GenSigCycleTimeActive" SG_ 837 Regeneration_DeviceInd 100;
BA_ "GenSigStartValue" SG_ 837 Regeneration_DeviceInd 15;
BA_ "Platform_VMCU1_Sig" SG_ 837 Regeneration_DeviceInd 1;
BA_ "GenSigCycleTime" SG_ 1056 BBDtcResetOffBoardApiRqst_ISig_4 100;
BA_ "GenSigCycleTimeActive" SG_ 1056 BBDtcResetOffBoardApiRqst_ISig_4 100;
BA_ "GenSigStartValue" SG_ 1056 BBDtcResetOffBoardApiRqst_ISig_4 15;
BA_ "GenSigCycleTime" SG_ 1056 ParkingHeaterCleaning_cmd_ISig_4 100;
BA_ "GenSigCycleTimeActive" SG_ 1056 ParkingHeaterCleaning_cmd_ISig_4 100;
BA_ "GenSigStartValue" SG_ 1056 ParkingHeaterCleaning_cmd_ISig_4 3;
BA_ "GenSigCycleTime" SG_ 1056 ExteriorLightsAFSAllowed_ISig_4 100;
BA_ "GenSigCycleTimeActive" SG_ 1056 ExteriorLightsAFSAllowed_ISig_4 100;
BA_ "GenSigStartValue" SG_ 1056 ExteriorLightsAFSAllowed_ISig_4 3;
BA_ "GenSigCycleTime" SG_ 1056 BBDtcResetOnBoardApiRqst_ISig_4 100;
BA_ "GenSigCycleTimeActive" SG_ 1056 BBDtcResetOnBoardApiRqst_ISig_4 100;
BA_ "GenSigStartValue" SG_ 1056 BBDtcResetOnBoardApiRqst_ISig_4 15;
BA_ "GenSigCycleTime" SG_ 1056 BBDtcListButtonGuiRqst 100;
BA_ "GenSigCycleTimeActive" SG_ 1056 BBDtcListButtonGuiRqst 100;
BA_ "GenSigStartValue" SG_ 1056 BBDtcListButtonGuiRqst 3;
BA_ "GenSigCycleTime" SG_ 1056 SetTimeOffset_rqst 100;
BA_ "GenSigCycleTimeActive" SG_ 1056 SetTimeOffset_rqst 100;
BA_ "GenSigStartValue" SG_ 1056 SetTimeOffset_rqst 4294967295;
BA_ "GenSigCycleTime" SG_ 1056 BBDtcResetButtonGuiRqst 100;
BA_ "GenSigCycleTimeActive" SG_ 1056 BBDtcResetButtonGuiRqst 100;
BA_ "GenSigStartValue" SG_ 1056 BBDtcResetButtonGuiRqst 15;
BA_ "GenSigCycleTime" SG_ 1056 ExtraHeating_rqst_ISig_4 100;
BA_ "GenSigCycleTimeActive" SG_ 1056 ExtraHeating_rqst_ISig_4 100;
BA_ "GenSigStartValue" SG_ 1056 ExtraHeating_rqst_ISig_4 7;
BA_ "GenSigCycleTime" SG_ 1056 HillDataCtrlTGW_State_ISig_4 100;
BA_ "GenSigCycleTimeActive" SG_ 1056 HillDataCtrlTGW_State_ISig_4 100;
BA_ "GenSigStartValue" SG_ 1056 HillDataCtrlTGW_State_ISig_4 7;
BA_ "Platform_VMCU1_Sig" SG_ 1056 HillDataCtrlTGW_State_ISig_4 1;
BA_ "GenSigCycleTime" SG_ 1056 HillDataCtrlTGW_AckCnt_ISig_4 100;
BA_ "GenSigCycleTimeActive" SG_ 1056 HillDataCtrlTGW_AckCnt_ISig_4 100;
BA_ "Platform_VMCU1_Sig" SG_ 1056 HillDataCtrlTGW_AckCnt_ISig_4 1;
BA_ "GenSigCycleTime" SG_ 1056 BBDtcListButtonSpApiRqst_ISig_4 100;
BA_ "GenSigCycleTimeActive" SG_ 1056 BBDtcListButtonSpApiRqst_ISig_4 100;
BA_ "GenSigStartValue" SG_ 1056 BBDtcListButtonSpApiRqst_ISig_4 3;
BA_ "GenSigCycleTime" SG_ 1334 Snooze_EventTimerReq_Id 100;
BA_ "GenSigCycleTimeActive" SG_ 1334 Snooze_EventTimerReq_Id 100;
BA_ "GenSigStartValue" SG_ 1334 Snooze_EventTimerReq_Id 255;
BA_ "GenSigSendType" SG_ 1334 BacklightLevelHighRes2_ISig_4 3;
BA_ "GenSigCycleTime" SG_ 1334 BacklightLevelHighRes2_ISig_4 100;
BA_ "GenSigCycleTimeActive" SG_ 1334 BacklightLevelHighRes2_ISig_4 100;
BA_ "GenSigStartValue" SG_ 1334 BacklightLevelHighRes2_ISig_4 255;
BA_ "Platform_VMCU1_Sig" SG_ 1334 BacklightLevelHighRes2_ISig_4 1;
BA_ "GenSigCycleTime" SG_ 1334 MovingUnitTracRollerBench_ISig_4 100;
BA_ "GenSigCycleTimeActive" SG_ 1334 MovingUnitTracRollerBench_ISig_4 100;
BA_ "GenSigStartValue" SG_ 1334 MovingUnitTracRollerBench_ISig_4 3;
BA_ "GenSigCycleTime" SG_ 1334 MaintReset_rqst_Selection 100;
BA_ "GenSigCycleTimeActive" SG_ 1334 MaintReset_rqst_Selection 100;
BA_ "GenSigStartValue" SG_ 1334 MaintReset_rqst_Selection 15;
BA_ "Platform_VMCU1_Sig" SG_ 1334 MaintReset_rqst_Selection 1;
BA_ "GenSigCycleTime" SG_ 1334 MaintReset_rqst_Request 100;
BA_ "GenSigCycleTimeActive" SG_ 1334 MaintReset_rqst_Request 100;
BA_ "GenSigStartValue" SG_ 1334 MaintReset_rqst_Request 3;
BA_ "Platform_VMCU1_Sig" SG_ 1334 MaintReset_rqst_Request 1;
BA_ "GenSigSendType" SG_ 1334 DPF_ManualRegenerateInhibit 3;
BA_ "GenSigCycleTime" SG_ 1334 DPF_ManualRegenerateInhibit 100;
BA_ "GenSigCycleTimeActive" SG_ 1334 DPF_ManualRegenerateInhibit 100;
BA_ "GenSigStartValue" SG_ 1334 DPF_ManualRegenerateInhibit 3;
BA_ "Platform_VMCU1_Sig" SG_ 1334 DPF_ManualRegenerateInhibit 1;
BA_ "GenSigCycleTime" SG_ 1334 Snooze_EventTimerReq_Oper 100;
BA_ "GenSigCycleTimeActive" SG_ 1334 Snooze_EventTimerReq_Oper 100;
BA_ "GenSigStartValue" SG_ 1334 Snooze_EventTimerReq_Oper 7;
BA_ "GenSigSendType" SG_ 1334 BlackPanel_stat_ISig_4 3;
BA_ "GenSigCycleTime" SG_ 1334 BlackPanel_stat_ISig_4 100;
BA_ "GenSigCycleTimeActive" SG_ 1334 BlackPanel_stat_ISig_4 100;
BA_ "GenSigStartValue" SG_ 1334 BlackPanel_stat_ISig_4 3;
BA_ "GenSigCycleTime" SG_ 1334 Snooze_EventTimerReq_Time 100;
BA_ "GenSigCycleTimeActive" SG_ 1334 Snooze_EventTimerReq_Time 100;
BA_ "GenSigStartValue" SG_ 1334 Snooze_EventTimerReq_Time 2097151;
BA_ "GenSigCycleTime" SG_ 1334 MaintReset_rqst_ID 100;
BA_ "GenSigCycleTimeActive" SG_ 1334 MaintReset_rqst_ID 100;
BA_ "GenSigStartValue" SG_ 1334 MaintReset_rqst_ID 63;
BA_ "Platform_VMCU1_Sig" SG_ 1334 MaintReset_rqst_ID 1;
BA_ "GenSigCycleTime" SG_ 1334 PS_BlackPanelStatBtnInd_ISig_4 100;
BA_ "GenSigCycleTimeActive" SG_ 1334 PS_BlackPanelStatBtnInd_ISig_4 100;
BA_ "GenSigStartValue" SG_ 1334 PS_BlackPanelStatBtnInd_ISig_4 3;
BA_ "GenSigSendType" SG_ 1334 DPF_ManualRegenerateRequest 3;
BA_ "GenSigCycleTime" SG_ 1334 DPF_ManualRegenerateRequest 100;
BA_ "GenSigCycleTimeActive" SG_ 1334 DPF_ManualRegenerateRequest 100;
BA_ "GenSigStartValue" SG_ 1334 DPF_ManualRegenerateRequest 3;
BA_ "Platform_VMCU1_Sig" SG_ 1334 DPF_ManualRegenerateRequest 1;
BA_ "GenSigSendType" SG_ 1344 HMIIOM_BB2_20S_FCS 7;
BA_ "Platform_VMCU1_Sig" SG_ 1344 HMIIOM_BB2_20S_FCS 1;
BA_ "GenSigSendType" SG_ 1343 ECU3VIN_stat 1;
BA_ "GenSigMaxLatency" SG_ 1343 ECU3VIN_stat 137;
BA_ "Platform_VMCU1_Sig" SG_ 1343 ECU3VIN_stat 1;
BA_ "GenSigSendType" SG_ 1379 HMIIOM_BB2_19P_FCS_563 7;
BA_ "Platform_VMCU1_Sig" SG_ 1379 HMIIOM_BB2_19P_FCS_563 1;
BA_ "GenSigSendType" SG_ 1377 GPSData_Longitude_ISig_4_561 1;
BA_ "GenSigStartValue" SG_ 1377 GPSData_Longitude_ISig_4_561 4294967295;
BA_ "GenSigMaxLatency" SG_ 1377 GPSData_Longitude_ISig_4_561 523;
BA_ "NeedsUpdateBit" SG_ 1377 GPSData_Longitude_ISig_4_561 1;
BA_ "Platform_VMCU1_Sig" SG_ 1377 GPSData_Longitude_ISig_4_561 1;
BA_ "GenSigSendType" SG_ 1377 GPSData_sg_UB_ISig_4_561 7;
BA_ "Platform_VMCU1_Sig" SG_ 1377 GPSData_sg_UB_ISig_4_561 1;
BA_ "GenSigSendType" SG_ 1377 GPSData_Direction_ISig_4_561 1;
BA_ "GenSigMaxLatency" SG_ 1377 GPSData_Direction_ISig_4_561 523;
BA_ "NeedsUpdateBit" SG_ 1377 GPSData_Direction_ISig_4_561 1;
BA_ "Platform_VMCU1_Sig" SG_ 1377 GPSData_Direction_ISig_4_561 1;
BA_ "GenSigSendType" SG_ 1377 GPSData_Latitude_ISig_4_561 1;
BA_ "GenSigStartValue" SG_ 1377 GPSData_Latitude_ISig_4_561 4294967295;
BA_ "GenSigMaxLatency" SG_ 1377 GPSData_Latitude_ISig_4_561 523;
BA_ "NeedsUpdateBit" SG_ 1377 GPSData_Latitude_ISig_4_561 1;
BA_ "Platform_VMCU1_Sig" SG_ 1377 GPSData_Latitude_ISig_4_561 1;
BA_ "GenSigSendType" SG_ 1377 GPSData_Altitude_ISig_4_561 1;
BA_ "GenSigStartValue" SG_ 1377 GPSData_Altitude_ISig_4_561 65535;
BA_ "GenSigMaxLatency" SG_ 1377 GPSData_Altitude_ISig_4_561 523;
BA_ "NeedsUpdateBit" SG_ 1377 GPSData_Altitude_ISig_4_561 1;
BA_ "Platform_VMCU1_Sig" SG_ 1377 GPSData_Altitude_ISig_4_561 1;
BA_ "GenSigSendType" SG_ 1377 GPSData_HDOP_ISig_4_561 1;
BA_ "GenSigMaxLatency" SG_ 1377 GPSData_HDOP_ISig_4_561 523;
BA_ "NeedsUpdateBit" SG_ 1377 GPSData_HDOP_ISig_4_561 1;
BA_ "Platform_VMCU1_Sig" SG_ 1377 GPSData_HDOP_ISig_4_561 1;
BA_ "GenSigSendType" SG_ 1377 GPSData_Time_ISig_4_561 1;
BA_ "GenSigStartValue" SG_ 1377 GPSData_Time_ISig_4_561 4294967295;
BA_ "GenSigMaxLatency" SG_ 1377 GPSData_Time_ISig_4_561 523;
BA_ "NeedsUpdateBit" SG_ 1377 GPSData_Time_ISig_4_561 1;
BA_ "Platform_VMCU1_Sig" SG_ 1377 GPSData_Time_ISig_4_561 1;
BA_ "GenSigSendType" SG_ 1377 GPSData_VehSpeed_ISig_4_561 1;
BA_ "GenSigStartValue" SG_ 1377 GPSData_VehSpeed_ISig_4_561 65535;
BA_ "GenSigMaxLatency" SG_ 1377 GPSData_VehSpeed_ISig_4_561 523;
BA_ "NeedsUpdateBit" SG_ 1377 GPSData_VehSpeed_ISig_4_561 1;
BA_ "Platform_VMCU1_Sig" SG_ 1377 GPSData_VehSpeed_ISig_4_561 1;
BA_ "GenSigSendType" SG_ 1377 GPSData_AntennaStat_ISig_4_561 1;
BA_ "GenSigStartValue" SG_ 1377 GPSData_AntennaStat_ISig_4_561 7;
BA_ "GenSigMaxLatency" SG_ 1377 GPSData_AntennaStat_ISig_4_561 523;
BA_ "NeedsUpdateBit" SG_ 1377 GPSData_AntennaStat_ISig_4_561 1;
BA_ "Platform_VMCU1_Sig" SG_ 1377 GPSData_AntennaStat_ISig_4_561 1;
BA_ "GenSigSendType" SG_ 1376 HMIIOM_BB2_19P_FCS_560 7;
BA_ "Platform_VMCU1_Sig" SG_ 1376 HMIIOM_BB2_19P_FCS_560 1;
BA_ "GenSigSendType" SG_ 1375 GPSData_HDOP_ISig_4_55f 1;
BA_ "GenSigMaxLatency" SG_ 1375 GPSData_HDOP_ISig_4_55f 523;
BA_ "NeedsUpdateBit" SG_ 1375 GPSData_HDOP_ISig_4_55f 1;
BA_ "Platform_VMCU1_Sig" SG_ 1375 GPSData_HDOP_ISig_4_55f 1;
BA_ "GenSigSendType" SG_ 1375 GPSData_VehSpeed_ISig_4_55f 1;
BA_ "GenSigStartValue" SG_ 1375 GPSData_VehSpeed_ISig_4_55f 65535;
BA_ "GenSigMaxLatency" SG_ 1375 GPSData_VehSpeed_ISig_4_55f 523;
BA_ "NeedsUpdateBit" SG_ 1375 GPSData_VehSpeed_ISig_4_55f 1;
BA_ "Platform_VMCU1_Sig" SG_ 1375 GPSData_VehSpeed_ISig_4_55f 1;
BA_ "GenSigSendType" SG_ 1375 GPSData_Direction_ISig_4_55f 1;
BA_ "GenSigMaxLatency" SG_ 1375 GPSData_Direction_ISig_4_55f 523;
BA_ "NeedsUpdateBit" SG_ 1375 GPSData_Direction_ISig_4_55f 1;
BA_ "Platform_VMCU1_Sig" SG_ 1375 GPSData_Direction_ISig_4_55f 1;
BA_ "GenSigSendType" SG_ 1375 GPSData_Longitude_ISig_4_55f 1;
BA_ "GenSigStartValue" SG_ 1375 GPSData_Longitude_ISig_4_55f 4294967295;
BA_ "GenSigMaxLatency" SG_ 1375 GPSData_Longitude_ISig_4_55f 523;
BA_ "NeedsUpdateBit" SG_ 1375 GPSData_Longitude_ISig_4_55f 1;
BA_ "Platform_VMCU1_Sig" SG_ 1375 GPSData_Longitude_ISig_4_55f 1;
BA_ "GenSigSendType" SG_ 1375 GPSData_sg_UB_ISig_4_55f 7;
BA_ "Platform_VMCU1_Sig" SG_ 1375 GPSData_sg_UB_ISig_4_55f 1;
BA_ "GenSigSendType" SG_ 1375 GPSData_Time_ISig_4_55f 1;
BA_ "GenSigStartValue" SG_ 1375 GPSData_Time_ISig_4_55f 4294967295;
BA_ "GenSigMaxLatency" SG_ 1375 GPSData_Time_ISig_4_55f 523;
BA_ "NeedsUpdateBit" SG_ 1375 GPSData_Time_ISig_4_55f 1;
BA_ "Platform_VMCU1_Sig" SG_ 1375 GPSData_Time_ISig_4_55f 1;
BA_ "GenSigSendType" SG_ 1375 GPSData_Latitude_ISig_4_55f 1;
BA_ "GenSigStartValue" SG_ 1375 GPSData_Latitude_ISig_4_55f 4294967295;
BA_ "GenSigMaxLatency" SG_ 1375 GPSData_Latitude_ISig_4_55f 523;
BA_ "NeedsUpdateBit" SG_ 1375 GPSData_Latitude_ISig_4_55f 1;
BA_ "Platform_VMCU1_Sig" SG_ 1375 GPSData_Latitude_ISig_4_55f 1;
BA_ "GenSigSendType" SG_ 1375 GPSData_AntennaStat_ISig_4_55f 1;
BA_ "GenSigStartValue" SG_ 1375 GPSData_AntennaStat_ISig_4_55f 7;
BA_ "GenSigMaxLatency" SG_ 1375 GPSData_AntennaStat_ISig_4_55f 523;
BA_ "NeedsUpdateBit" SG_ 1375 GPSData_AntennaStat_ISig_4_55f 1;
BA_ "Platform_VMCU1_Sig" SG_ 1375 GPSData_AntennaStat_ISig_4_55f 1;
BA_ "GenSigSendType" SG_ 1375 GPSData_Altitude_ISig_4_55f 1;
BA_ "GenSigStartValue" SG_ 1375 GPSData_Altitude_ISig_4_55f 65535;
BA_ "GenSigMaxLatency" SG_ 1375 GPSData_Altitude_ISig_4_55f 523;
BA_ "NeedsUpdateBit" SG_ 1375 GPSData_Altitude_ISig_4_55f 1;
BA_ "Platform_VMCU1_Sig" SG_ 1375 GPSData_Altitude_ISig_4_55f 1;
BA_ "GenSigSendType" SG_ 1415 HMIIOM_BB2_19P_FCS_587 7;
BA_ "Platform_VMCU1_Sig" SG_ 1415 HMIIOM_BB2_19P_FCS_587 1;
BA_REL_ "GenSigFirstTimeoutTime" BU_SG_REL_ IC3 SG_ 1041 GearShiftingRec_Steps 3000;
BA_REL_ "GenSigTimeoutTime" BU_SG_REL_ IC3 SG_ 1041 GearShiftingRec_Steps 600;
BA_REL_ "GenSigFirstTimeoutTime" BU_SG_REL_ IC3 SG_ 1041 GearShiftingRec_Direction 3000;
BA_REL_ "GenSigTimeoutTime" BU_SG_REL_ IC3 SG_ 1041 GearShiftingRec_Direction 600;
BA_REL_ "GenSigFirstTimeoutTime" BU_SG_REL_ IC3 SG_ 1041 BrakeInterlockStatus 3000;
BA_REL_ "GenSigTimeoutTime" BU_SG_REL_ IC3 SG_ 1041 BrakeInterlockStatus 600;
BA_REL_ "GenSigFirstTimeoutTime" BU_SG_REL_ VMCU SG_ 1041 BrakeInterlockStatus 3000;
BA_REL_ "GenSigTimeoutTime" BU_SG_REL_ VMCU SG_ 1041 BrakeInterlockStatus 600;
BA_REL_ "GenSigFirstTimeoutTime" BU_SG_REL_ IC3 SG_ 1041 AutGearSplitPosition_ISig_4 3000;
BA_REL_ "GenSigTimeoutTime" BU_SG_REL_ IC3 SG_ 1041 AutGearSplitPosition_ISig_4 600;
BA_REL_ "GenSigFirstTimeoutTime" BU_SG_REL_ BBM SG_ 1041 AutGearSplitPosition_ISig_4 3000;
BA_REL_ "GenSigTimeoutTime" BU_SG_REL_ BBM SG_ 1041 AutGearSplitPosition_ISig_4 600;
BA_REL_ "GenSigFirstTimeoutTime" BU_SG_REL_ IC3 SG_ 1041 TransmissionBrakeMode 3000;
BA_REL_ "GenSigTimeoutTime" BU_SG_REL_ IC3 SG_ 1041 TransmissionBrakeMode 600;
BA_REL_ "GenSigFirstTimeoutTime" BU_SG_REL_ IC3 SG_ 1041 AvailableGearsWithLowerRatio 3000;
BA_REL_ "GenSigTimeoutTime" BU_SG_REL_ IC3 SG_ 1041 AvailableGearsWithLowerRatio 600;
BA_REL_ "GenSigFirstTimeoutTime" BU_SG_REL_ VMCU SG_ 1041 FuelEcoDrvStatus 3000;
BA_REL_ "GenSigTimeoutTime" BU_SG_REL_ VMCU SG_ 1041 FuelEcoDrvStatus 600;
BA_REL_ "GenSigFirstTimeoutTime" BU_SG_REL_ IC3 SG_ 1041 EcoCruiseStatus_ISig_4 3000;
BA_REL_ "GenSigTimeoutTime" BU_SG_REL_ IC3 SG_ 1041 EcoCruiseStatus_ISig_4 600;
BA_REL_ "GenSigFirstTimeoutTime" BU_SG_REL_ EMS SG_ 1041 EcoCruiseStatus_ISig_4 3000;
BA_REL_ "GenSigTimeoutTime" BU_SG_REL_ EMS SG_ 1041 EcoCruiseStatus_ISig_4 600;
BA_REL_ "GenSigFirstTimeoutTime" BU_SG_REL_ VMCU SG_ 1041 TransmissionDrivingMode_ISig_4 3000;
BA_REL_ "GenSigTimeoutTime" BU_SG_REL_ VMCU SG_ 1041 TransmissionDrivingMode_ISig_4 600;
BA_REL_ "GenSigFirstTimeoutTime" BU_SG_REL_ DACU SG_ 1041 TransmissionDrivingMode_ISig_4 3000;
BA_REL_ "GenSigTimeoutTime" BU_SG_REL_ DACU SG_ 1041 TransmissionDrivingMode_ISig_4 600;
BA_REL_ "GenSigFirstTimeoutTime" BU_SG_REL_ IC3 SG_ 1041 TransmissionDrivingMode_ISig_4 3000;
BA_REL_ "GenSigTimeoutTime" BU_SG_REL_ IC3 SG_ 1041 TransmissionDrivingMode_ISig_4 600;
BA_REL_ "GenSigFirstTimeoutTime" BU_SG_REL_ VMCU SG_ 1041 ClutchWearStatus 3000;
BA_REL_ "GenSigTimeoutTime" BU_SG_REL_ VMCU SG_ 1041 ClutchWearStatus 600;
BA_REL_ "GenSigFirstTimeoutTime" BU_SG_REL_ EMS SG_ 1041 AutoWheelBrakeInhibited 3000;
BA_REL_ "GenSigTimeoutTime" BU_SG_REL_ EMS SG_ 1041 AutoWheelBrakeInhibited 600;
BA_REL_ "GenSigFirstTimeoutTime" BU_SG_REL_ VMCU SG_ 1041 DrivingMode_ISig_4 3000;
BA_REL_ "GenSigTimeoutTime" BU_SG_REL_ VMCU SG_ 1041 DrivingMode_ISig_4 600;
BA_REL_ "GenSigFirstTimeoutTime" BU_SG_REL_ IC3 SG_ 1041 DrivingMode_ISig_4 3000;
BA_REL_ "GenSigTimeoutTime" BU_SG_REL_ IC3 SG_ 1041 DrivingMode_ISig_4 600;
BA_REL_ "GenSigFirstTimeoutTime" BU_SG_REL_ IC3 SG_ 1041 AutoWheelBrakesDownshiftSugges 3000;
BA_REL_ "GenSigTimeoutTime" BU_SG_REL_ IC3 SG_ 1041 AutoWheelBrakesDownshiftSugges 600;
BA_REL_ "GenSigFirstTimeoutTime" BU_SG_REL_ BBM SG_ 1041 TransmissionOilTempHigh_ISig_4 3000;
BA_REL_ "GenSigTimeoutTime" BU_SG_REL_ BBM SG_ 1041 TransmissionOilTempHigh_ISig_4 600;
BA_REL_ "GenSigFirstTimeoutTime" BU_SG_REL_ IC3 SG_ 1041 TransmissionOilTempHigh_ISig_4 3000;
BA_REL_ "GenSigTimeoutTime" BU_SG_REL_ IC3 SG_ 1041 TransmissionOilTempHigh_ISig_4 600;
BA_REL_ "GenSigFirstTimeoutTime" BU_SG_REL_ VMCU SG_ 1041 AvailableGearsWithHigherRatio 3000;
BA_REL_ "GenSigTimeoutTime" BU_SG_REL_ VMCU SG_ 1041 AvailableGearsWithHigherRatio 600;
BA_REL_ "GenSigFirstTimeoutTime" BU_SG_REL_ IC3 SG_ 1041 AvailableGearsWithHigherRatio 3000;
BA_REL_ "GenSigTimeoutTime" BU_SG_REL_ IC3 SG_ 1041 AvailableGearsWithHigherRatio 600;
BA_REL_ "GenSigFirstTimeoutTime" BU_SG_REL_ BBM SG_ 516 Pto1Consent_ISig_4 3000;
BA_REL_ "GenSigTimeoutTime" BU_SG_REL_ BBM SG_ 516 Pto1Consent_ISig_4 150;
BA_REL_ "GenSigFirstTimeoutTime" BU_SG_REL_ VMCU SG_ 516 Pto1Consent_ISig_4 3000;
BA_REL_ "GenSigTimeoutTime" BU_SG_REL_ VMCU SG_ 516 Pto1Consent_ISig_4 150;
BA_REL_ "GenSigFirstTimeoutTime" BU_SG_REL_ BBM SG_ 516 Pto2Consent_ISig_4 3000;
BA_REL_ "GenSigTimeoutTime" BU_SG_REL_ BBM SG_ 516 Pto2Consent_ISig_4 150;
BA_REL_ "GenSigFirstTimeoutTime" BU_SG_REL_ VMCU SG_ 516 Pto2Consent_ISig_4 3000;
BA_REL_ "GenSigTimeoutTime" BU_SG_REL_ VMCU SG_ 516 Pto2Consent_ISig_4 150;
BA_REL_ "GenSigFirstTimeoutTime" BU_SG_REL_ VMCU SG_ 516 DirectionGearAllowed 3000;
BA_REL_ "GenSigTimeoutTime" BU_SG_REL_ VMCU SG_ 516 DirectionGearAllowed 150;
BA_REL_ "GenSigFirstTimeoutTime" BU_SG_REL_ VMCU SG_ 516 TransmissionSystemPowerDownAck 3000;
BA_REL_ "GenSigTimeoutTime" BU_SG_REL_ VMCU SG_ 516 TransmissionSystemPowerDownAck 150;
BA_REL_ "GenSigFirstTimeoutTime" BU_SG_REL_ IC3 SG_ 516 EcoRollActiveStatus_ISig_4 3000;
BA_REL_ "GenSigTimeoutTime" BU_SG_REL_ IC3 SG_ 516 EcoRollActiveStatus_ISig_4 150;
BA_REL_ "GenSigFirstTimeoutTime" BU_SG_REL_ VMCU SG_ 516 EcoRollActiveStatus_ISig_4 3000;
BA_REL_ "GenSigTimeoutTime" BU_SG_REL_ VMCU SG_ 516 EcoRollActiveStatus_ISig_4 150;
BA_REL_ "GenSigFirstTimeoutTime" BU_SG_REL_ IC3 SG_ 516 TransmissionAirPressureLow 3000;
BA_REL_ "GenSigTimeoutTime" BU_SG_REL_ IC3 SG_ 516 TransmissionAirPressureLow 150;
BA_REL_ "GenSigFirstTimeoutTime" BU_SG_REL_ CIOM SG_ 516 GearBoxUnlockAuth_rqst 3000;
BA_REL_ "GenSigTimeoutTime" BU_SG_REL_ CIOM SG_ 516 GearBoxUnlockAuth_rqst 150;
BA_REL_ "GenSigFirstTimeoutTime" BU_SG_REL_ EMS SG_ 516 TransmEngineStop_req 3000;
BA_REL_ "GenSigTimeoutTime" BU_SG_REL_ EMS SG_ 516 TransmEngineStop_req 150;
BA_REL_ "GenSigFirstTimeoutTime" BU_SG_REL_ IC3 SG_ 516 RoadInclination_ISig_4 3000;
BA_REL_ "GenSigTimeoutTime" BU_SG_REL_ IC3 SG_ 516 RoadInclination_ISig_4 150;
BA_REL_ "GenSigFirstTimeoutTime" BU_SG_REL_ VMCU SG_ 516 RoadInclination_ISig_4 3000;
BA_REL_ "GenSigTimeoutTime" BU_SG_REL_ VMCU SG_ 516 RoadInclination_ISig_4 150;
BA_REL_ "GenSigFirstTimeoutTime" BU_SG_REL_ EMS SG_ 516 RoadInclination_ISig_4 3000;
BA_REL_ "GenSigTimeoutTime" BU_SG_REL_ EMS SG_ 516 RoadInclination_ISig_4 150;
BA_REL_ "GenSigFirstTimeoutTime" BU_SG_REL_ DACU SG_ 516 RoadInclination_ISig_4 3000;
BA_REL_ "GenSigTimeoutTime" BU_SG_REL_ DACU SG_ 516 RoadInclination_ISig_4 150;
BA_REL_ "GenSigFirstTimeoutTime" BU_SG_REL_ EMS SG_ 516 ACC_SGO_TransmissionStatus 3000;
BA_REL_ "GenSigTimeoutTime" BU_SG_REL_ EMS SG_ 516 ACC_SGO_TransmissionStatus 150;
BA_REL_ "GenSigFirstTimeoutTime" BU_SG_REL_ DACU SG_ 516 ACC_SGO_TransmissionStatus 3000;
BA_REL_ "GenSigTimeoutTime" BU_SG_REL_ DACU SG_ 516 ACC_SGO_TransmissionStatus 150;
BA_REL_ "GenSigFirstTimeoutTime" BU_SG_REL_ DACU SG_ 516 TransmOutputShaftSpeedSigned_ISi 3000;
BA_REL_ "GenSigTimeoutTime" BU_SG_REL_ DACU SG_ 516 TransmOutputShaftSpeedSigned_ISi 150;
BA_REL_ "GenSigFirstTimeoutTime" BU_SG_REL_ VMCU SG_ 516 TransmOutputShaftSpeedSigned_ISi 3000;
BA_REL_ "GenSigTimeoutTime" BU_SG_REL_ VMCU SG_ 516 TransmOutputShaftSpeedSigned_ISi 150;
BA_REL_ "GenSigFirstTimeoutTime" BU_SG_REL_ IC3 SG_ 516 ClutchOverloadStatus_ISig_4 3000;
BA_REL_ "GenSigTimeoutTime" BU_SG_REL_ IC3 SG_ 516 ClutchOverloadStatus_ISig_4 150;
BA_REL_ "GenSigFirstTimeoutTime" BU_SG_REL_ BBM SG_ 516 ClutchOverloadStatus_ISig_4 3000;
BA_REL_ "GenSigTimeoutTime" BU_SG_REL_ BBM SG_ 516 ClutchOverloadStatus_ISig_4 150;
BA_REL_ "GenSigFirstTimeoutTime" BU_SG_REL_ CIOM SG_ 2564445169 PhysDiagReqSig_53_F1_ISig_4 3000;
BA_REL_ "GenSigTimeoutTime" BU_SG_REL_ CIOM SG_ 2564445169 PhysDiagReqSig_53_F1_ISig_4 600;
BA_REL_ "GenSigFirstTimeoutTime" BU_SG_REL_ VMCU SG_ 1280 ExteriorLightsAFSAllowedFAKE 12000;
BA_REL_ "GenSigTimeoutTime" BU_SG_REL_ VMCU SG_ 1280 ExteriorLightsAFSAllowedFAKE 3000;
BA_REL_ "GenSigFirstTimeoutTime" BU_SG_REL_ VMCU SG_ 1280 CamerasPowerSupply_rqstFAKE 12000;
BA_REL_ "GenSigTimeoutTime" BU_SG_REL_ VMCU SG_ 1280 CamerasPowerSupply_rqstFAKE 3000;
BA_REL_ "GenSigFirstTimeoutTime" BU_SG_REL_ CIOM SG_ 1129 AlarmClkAl_LECM_stat_SetMin_ISig 3600;
BA_REL_ "GenSigTimeoutTime" BU_SG_REL_ CIOM SG_ 1129 AlarmClkAl_LECM_stat_SetMin_ISig 900;
BA_REL_ "GenSigFirstTimeoutTime" BU_SG_REL_ CIOM SG_ 1129 AlarmClkAl_LECM_stat_SetHr_ISig_ 3600;
BA_REL_ "GenSigTimeoutTime" BU_SG_REL_ CIOM SG_ 1129 AlarmClkAl_LECM_stat_SetHr_ISig_ 900;
BA_REL_ "GenSigFirstTimeoutTime" BU_SG_REL_ CIOM SG_ 1129 AlarmClkAl_LECM_stat_Stat_ISig_4 3600;
BA_REL_ "GenSigTimeoutTime" BU_SG_REL_ CIOM SG_ 1129 AlarmClkAl_LECM_stat_Stat_ISig_4 900;
BA_REL_ "GenSigFirstTimeoutTime" BU_SG_REL_ CIOM SG_ 1129 AlarmClkAl_LECM_stat_Mode_ISig_4 3600;
BA_REL_ "GenSigTimeoutTime" BU_SG_REL_ CIOM SG_ 1129 AlarmClkAl_LECM_stat_Mode_ISig_4 900;
BA_REL_ "GenSigFirstTimeoutTime" BU_SG_REL_ CIOM SG_ 1129 AlarmClkAl_LECM_stat_ID_ISig_4 3600;
BA_REL_ "GenSigTimeoutTime" BU_SG_REL_ CIOM SG_ 1129 AlarmClkAl_LECM_stat_ID_ISig_4 900;
BA_REL_ "GenSigFirstTimeoutTime" BU_SG_REL_ CIOM SG_ 1129 AlarmClkAl_LECM_stat_Type_ISig_4 3600;
BA_REL_ "GenSigTimeoutTime" BU_SG_REL_ CIOM SG_ 1129 AlarmClkAl_LECM_stat_Type_ISig_4 900;
BA_REL_ "GenSigFirstTimeoutTime" BU_SG_REL_ CIOM SG_ 1129 AlarmClkAl_LECM_stat_DaySet_ISig 3600;
BA_REL_ "GenSigTimeoutTime" BU_SG_REL_ CIOM SG_ 1129 AlarmClkAl_LECM_stat_DaySet_ISig 900;
BA_REL_ "GenSigFirstTimeoutTime" BU_SG_REL_ CIOM SG_ 839 UpdParkClimTimerRqst_TimerCmd_IS 6000;
BA_REL_ "GenSigTimeoutTime" BU_SG_REL_ CIOM SG_ 839 UpdParkClimTimerRqst_TimerCmd_IS 1500;
BA_REL_ "GenSigFirstTimeoutTime" BU_SG_REL_ VMCU SG_ 839 CombinationScaleLoad_ScaleLoad 6000;
BA_REL_ "GenSigTimeoutTime" BU_SG_REL_ VMCU SG_ 839 CombinationScaleLoad_ScaleLoad 1500;
BA_REL_ "GenSigFirstTimeoutTime" BU_SG_REL_ CIOM SG_ 839 UpdParkClimTimerRqst_TimRqst_ISi 6000;
BA_REL_ "GenSigTimeoutTime" BU_SG_REL_ CIOM SG_ 839 UpdParkClimTimerRqst_TimRqst_ISi 1500;
BA_REL_ "GenSigFirstTimeoutTime" BU_SG_REL_ VMCU SG_ 839 CombinationScaleLoad_FirstAxleID 6000;
BA_REL_ "GenSigTimeoutTime" BU_SG_REL_ VMCU SG_ 839 CombinationScaleLoad_FirstAxleID 1500;
BA_REL_ "GenSigFirstTimeoutTime" BU_SG_REL_ VMCU SG_ 839 CombinationScaleLoad_LastAxleID 6000;
BA_REL_ "GenSigTimeoutTime" BU_SG_REL_ VMCU SG_ 839 CombinationScaleLoad_LastAxleID 1500;
BA_REL_ "GenSigFirstTimeoutTime" BU_SG_REL_ CIOM SG_ 838 PhoneButtonIndication_cmd 3000;
BA_REL_ "GenSigTimeoutTime" BU_SG_REL_ CIOM SG_ 838 PhoneButtonIndication_cmd 300;
BA_REL_ "GenSigFirstTimeoutTime" BU_SG_REL_ CIOM SG_ 838 AirbagTelltale_stat_ISig_4 3000;
BA_REL_ "GenSigTimeoutTime" BU_SG_REL_ CIOM SG_ 838 AirbagTelltale_stat_ISig_4 300;
BA_REL_ "GenSigFirstTimeoutTime" BU_SG_REL_ CIOM SG_ 838 AudioSystemStatus_ISig_4 3000;
BA_REL_ "GenSigTimeoutTime" BU_SG_REL_ CIOM SG_ 838 AudioSystemStatus_ISig_4 300;
BA_REL_ "GenSigFirstTimeoutTime" BU_SG_REL_ CIOM SG_ 838 AudioSourceUsbAvailable_ISig_4 3000;
BA_REL_ "GenSigTimeoutTime" BU_SG_REL_ CIOM SG_ 838 AudioSourceUsbAvailable_ISig_4 300;
BA_REL_ "GenSigFirstTimeoutTime" BU_SG_REL_ CIOM SG_ 838 AQSModeRqst_ISig_4 3000;
BA_REL_ "GenSigTimeoutTime" BU_SG_REL_ CIOM SG_ 838 AQSModeRqst_ISig_4 300;
BA_REL_ "GenSigFirstTimeoutTime" BU_SG_REL_ CIOM SG_ 838 PresetIndicationCmd_ISig_4 3000;
BA_REL_ "GenSigTimeoutTime" BU_SG_REL_ CIOM SG_ 838 PresetIndicationCmd_ISig_4 300;
BA_REL_ "GenSigFirstTimeoutTime" BU_SG_REL_ CIOM SG_ 838 AudioSourceCdAvailable_ISig_4 3000;
BA_REL_ "GenSigTimeoutTime" BU_SG_REL_ CIOM SG_ 838 AudioSourceCdAvailable_ISig_4 300;
BA_REL_ "GenSigFirstTimeoutTime" BU_SG_REL_ CIOM SG_ 838 AudioVolumeIndicationCmd_ISig_4 3000;
BA_REL_ "GenSigTimeoutTime" BU_SG_REL_ CIOM SG_ 838 AudioVolumeIndicationCmd_ISig_4 300;
BA_REL_ "GenSigFirstTimeoutTime" BU_SG_REL_ CIOM SG_ 838 AudioSourceStatus2_ISig_4 3000;
BA_REL_ "GenSigTimeoutTime" BU_SG_REL_ CIOM SG_ 838 AudioSourceStatus2_ISig_4 300;
BA_REL_ "GenSigFirstTimeoutTime" BU_SG_REL_ CIOM SG_ 838 BTStatus 3000;
BA_REL_ "GenSigTimeoutTime" BU_SG_REL_ CIOM SG_ 838 BTStatus 300;
BA_REL_ "GenSigFirstTimeoutTime" BU_SG_REL_ VMCU SG_ 838 VCSystPowerSupply_rqst 3000;
BA_REL_ "GenSigTimeoutTime" BU_SG_REL_ VMCU SG_ 838 VCSystPowerSupply_rqst 300;
BA_REL_ "GenSigFirstTimeoutTime" BU_SG_REL_ CIOM SG_ 838 AudioSourceBtStreamAvailable_ISi 3000;
BA_REL_ "GenSigTimeoutTime" BU_SG_REL_ CIOM SG_ 838 AudioSourceBtStreamAvailable_ISi 300;
BA_REL_ "GenSigFirstTimeoutTime" BU_SG_REL_ CIOM SG_ 838 AudioMuteStat_ISig_4 3000;
BA_REL_ "GenSigTimeoutTime" BU_SG_REL_ CIOM SG_ 838 AudioMuteStat_ISig_4 300;
BA_REL_ "GenSigFirstTimeoutTime" BU_SG_REL_ TECU SG_ 838 ISeeEnableRequest 3000;
BA_REL_ "GenSigTimeoutTime" BU_SG_REL_ TECU SG_ 838 ISeeEnableRequest 300;
BA_REL_ "GenSigFirstTimeoutTime" BU_SG_REL_ CIOM SG_ 838 ACModeRqst_ISig_4 3000;
BA_REL_ "GenSigTimeoutTime" BU_SG_REL_ CIOM SG_ 838 ACModeRqst_ISig_4 300;
BA_REL_ "GenSigFirstTimeoutTime" BU_SG_REL_ CIOM SG_ 838 AudioSourceStatus_ISig_4 3000;
BA_REL_ "GenSigTimeoutTime" BU_SG_REL_ CIOM SG_ 838 AudioSourceStatus_ISig_4 300;
BA_REL_ "GenSigFirstTimeoutTime" BU_SG_REL_ VMCU SG_ 838 CalDataLoad_rqst_VehicleID 6000;
BA_REL_ "GenSigTimeoutTime" BU_SG_REL_ VMCU SG_ 838 CalDataLoad_rqst_VehicleID 300;
BA_REL_ "GenSigFirstTimeoutTime" BU_SG_REL_ CIOM SG_ 838 AudioSourceIpodAvailable_ISig_4 3000;
BA_REL_ "GenSigTimeoutTime" BU_SG_REL_ CIOM SG_ 838 AudioSourceIpodAvailable_ISig_4 300;
BA_REL_ "GenSigFirstTimeoutTime" BU_SG_REL_ VMCU SG_ 838 CalDataLoad_rqst_AxleID 6000;
BA_REL_ "GenSigTimeoutTime" BU_SG_REL_ VMCU SG_ 838 CalDataLoad_rqst_AxleID 300;
BA_REL_ "GenSigFirstTimeoutTime" BU_SG_REL_ CIOM SG_ 838 AutoBlowerLevelRqst_ISig_4 3000;
BA_REL_ "GenSigTimeoutTime" BU_SG_REL_ CIOM SG_ 838 AutoBlowerLevelRqst_ISig_4 300;
BA_REL_ "GenSigFirstTimeoutTime" BU_SG_REL_ CIOM SG_ 838 AutoDefogModeRqst_ISig_4 3000;
BA_REL_ "GenSigTimeoutTime" BU_SG_REL_ CIOM SG_ 838 AutoDefogModeRqst_ISig_4 300;
BA_REL_ "GenSigFirstTimeoutTime" BU_SG_REL_ IC3 SG_ 1306 ChargeCordStatus 12000;
BA_REL_ "GenSigTimeoutTime" BU_SG_REL_ IC3 SG_ 1306 ChargeCordStatus 3000;
BA_REL_ "GenSigFirstTimeoutTime" BU_SG_REL_ VMCU SG_ 1306 ChargeCordStatus 12000;
BA_REL_ "GenSigTimeoutTime" BU_SG_REL_ VMCU SG_ 1306 ChargeCordStatus 3000;
BA_REL_ "GenSigFirstTimeoutTime" BU_SG_REL_ IC3 SG_ 1306 HVStateOfCharge 12000;
BA_REL_ "GenSigTimeoutTime" BU_SG_REL_ IC3 SG_ 1306 HVStateOfCharge 3000;
BA_REL_ "GenSigFirstTimeoutTime" BU_SG_REL_ IC3 SG_ 1306 HVTimeToFullyCharged 12000;
BA_REL_ "GenSigTimeoutTime" BU_SG_REL_ IC3 SG_ 1306 HVTimeToFullyCharged 3000;
BA_REL_ "GenSigFirstTimeoutTime" BU_SG_REL_ IC3 SG_ 1306 HVChargingStatus 12000;
BA_REL_ "GenSigTimeoutTime" BU_SG_REL_ IC3 SG_ 1306 HVChargingStatus 3000;
BA_REL_ "GenSigFirstTimeoutTime" BU_SG_REL_ IC3 SG_ 1306 ChargePortLockStatus 12000;
BA_REL_ "GenSigTimeoutTime" BU_SG_REL_ IC3 SG_ 1306 ChargePortLockStatus 3000;
BA_REL_ "GenSigFirstTimeoutTime" BU_SG_REL_ CIOM SG_ 1363 ChlrVlvPsnFlt_ISig_4 24000;
BA_REL_ "GenSigTimeoutTime" BU_SG_REL_ CIOM SG_ 1363 ChlrVlvPsnFlt_ISig_4 6000;
BA_REL_ "GenSigFirstTimeoutTime" BU_SG_REL_ CIOM SG_ 1363 ESSClntTmp_ISig_4 24000;
BA_REL_ "GenSigTimeoutTime" BU_SG_REL_ CIOM SG_ 1363 ESSClntTmp_ISig_4 6000;
BA_REL_ "GenSigFirstTimeoutTime" BU_SG_REL_ CIOM SG_ 1363 EMPmpSpd_ISig_4 24000;
BA_REL_ "GenSigTimeoutTime" BU_SG_REL_ CIOM SG_ 1363 EMPmpSpd_ISig_4 6000;
BA_REL_ "GenSigFirstTimeoutTime" BU_SG_REL_ CIOM SG_ 1363 ESSTmp_ISig_4 24000;
BA_REL_ "GenSigTimeoutTime" BU_SG_REL_ CIOM SG_ 1363 ESSTmp_ISig_4 6000;
BA_REL_ "GenSigFirstTimeoutTime" BU_SG_REL_ CIOM SG_ 1363 ESSPmpSpd_ISig_4 24000;
BA_REL_ "GenSigTimeoutTime" BU_SG_REL_ CIOM SG_ 1363 ESSPmpSpd_ISig_4 6000;
BA_REL_ "GenSigFirstTimeoutTime" BU_SG_REL_ CIOM SG_ 1363 ESSTmpTrgt_ISig_4 24000;
BA_REL_ "GenSigTimeoutTime" BU_SG_REL_ CIOM SG_ 1363 ESSTmpTrgt_ISig_4 6000;
BA_REL_ "GenSigFirstTimeoutTime" BU_SG_REL_ CIOM SG_ 1363 ChlrUsgRqst_ISig_4 24000;
BA_REL_ "GenSigTimeoutTime" BU_SG_REL_ CIOM SG_ 1363 ChlrUsgRqst_ISig_4 6000;
BA_REL_ "GenSigFirstTimeoutTime" BU_SG_REL_ VMCU SG_ 1110 EpsPowerSupplyAck 3000;
BA_REL_ "GenSigTimeoutTime" BU_SG_REL_ VMCU SG_ 1110 EpsPowerSupplyAck 600;
BA_REL_ "GenSigFirstTimeoutTime" BU_SG_REL_ VMCU SG_ 1110 ReqEpsAlive 3000;
BA_REL_ "GenSigTimeoutTime" BU_SG_REL_ VMCU SG_ 1110 ReqEpsAlive 600;
BA_REL_ "GenSigFirstTimeoutTime" BU_SG_REL_ VMCU SG_ 1422 FasUsrDefinedStorage_rqst_ISig_4 24000;
BA_REL_ "GenSigTimeoutTime" BU_SG_REL_ VMCU SG_ 1422 FasUsrDefinedStorage_rqst_ISig_4 6000;
BA_REL_ "GenSigFirstTimeoutTime" BU_SG_REL_ CIOM SG_ 1422 ATC_ButtonIndication 24000;
BA_REL_ "GenSigTimeoutTime" BU_SG_REL_ CIOM SG_ 1422 ATC_ButtonIndication 6000;
BA_REL_ "GenSigFirstTimeoutTime" BU_SG_REL_ VMCU SG_ 1422 FasLowSpeedReturnSetting_rqst_IS 24000;
BA_REL_ "GenSigTimeoutTime" BU_SG_REL_ VMCU SG_ 1422 FasLowSpeedReturnSetting_rqst_IS 6000;
BA_REL_ "GenSigFirstTimeoutTime" BU_SG_REL_ VMCU SG_ 1422 FasManualOffsetSetting_rqst_ISig 24000;
BA_REL_ "GenSigTimeoutTime" BU_SG_REL_ VMCU SG_ 1422 FasManualOffsetSetting_rqst_ISig 6000;
BA_REL_ "GenSigFirstTimeoutTime" BU_SG_REL_ VMCU SG_ 1422 FasPersonalSettingsButton_rqst_I 24000;
BA_REL_ "GenSigTimeoutTime" BU_SG_REL_ VMCU SG_ 1422 FasPersonalSettingsButton_rqst_I 6000;
BA_REL_ "GenSigFirstTimeoutTime" BU_SG_REL_ VMCU SG_ 1422 FasStiffnessCurveSetting_rqst_IS 24000;
BA_REL_ "GenSigTimeoutTime" BU_SG_REL_ VMCU SG_ 1422 FasStiffnessCurveSetting_rqst_IS 6000;
BA_REL_ "GenSigFirstTimeoutTime" BU_SG_REL_ VMCU SG_ 1422 FasStiffStraightSetting_rqst_ISi 24000;
BA_REL_ "GenSigTimeoutTime" BU_SG_REL_ VMCU SG_ 1422 FasStiffStraightSetting_rqst_ISi 6000;
BA_REL_ "GenSigFirstTimeoutTime" BU_SG_REL_ VMCU SG_ 1422 FasDriver_rqst_ISig_4 24000;
BA_REL_ "GenSigTimeoutTime" BU_SG_REL_ VMCU SG_ 1422 FasDriver_rqst_ISig_4 6000;
BA_REL_ "GenSigFirstTimeoutTime" BU_SG_REL_ VMCU SG_ 1422 FasDampingSetting_rqst_ISig_4 24000;
BA_REL_ "GenSigTimeoutTime" BU_SG_REL_ VMCU SG_ 1422 FasDampingSetting_rqst_ISig_4 6000;
BA_REL_ "GenSigFirstTimeoutTime" BU_SG_REL_ CIOM SG_ 1422 ESC_ButtonIndication2 24000;
BA_REL_ "GenSigTimeoutTime" BU_SG_REL_ CIOM SG_ 1422 ESC_ButtonIndication2 6000;
BA_REL_ "GenSigFirstTimeoutTime" BU_SG_REL_ CIOM SG_ 1422 TCS_ButtonIndication 24000;
BA_REL_ "GenSigTimeoutTime" BU_SG_REL_ CIOM SG_ 1422 TCS_ButtonIndication 6000;
BA_REL_ "GenSigFirstTimeoutTime" BU_SG_REL_ CIOM SG_ 1422 ABS_ButtonIndication 24000;
BA_REL_ "GenSigTimeoutTime" BU_SG_REL_ CIOM SG_ 1422 ABS_ButtonIndication 6000;
BA_REL_ "GenSigFirstTimeoutTime" BU_SG_REL_ CIOM SG_ 1421 ESCOff_DeviceIndication 3000;
BA_REL_ "GenSigTimeoutTime" BU_SG_REL_ CIOM SG_ 1421 ESCOff_DeviceIndication 600;
BA_REL_ "GenSigFirstTimeoutTime" BU_SG_REL_ VMCU SG_ 1421 CCUnderSpeedRequest 3000;
BA_REL_ "GenSigTimeoutTime" BU_SG_REL_ VMCU SG_ 1421 CCUnderSpeedRequest 600;
BA_REL_ "GenSigFirstTimeoutTime" BU_SG_REL_ CIOM SG_ 1421 RollerBenchGUIDeviceStatus 3000;
BA_REL_ "GenSigTimeoutTime" BU_SG_REL_ CIOM SG_ 1421 RollerBenchGUIDeviceStatus 600;
BA_REL_ "GenSigFirstTimeoutTime" BU_SG_REL_ VMCU SG_ 1421 DHCSetSpeedAdjustRequest 3000;
BA_REL_ "GenSigTimeoutTime" BU_SG_REL_ VMCU SG_ 1421 DHCSetSpeedAdjustRequest 600;
BA_REL_ "GenSigFirstTimeoutTime" BU_SG_REL_ CIOM SG_ 1421 TemporaryRSLDeviceIndication 3000;
BA_REL_ "GenSigTimeoutTime" BU_SG_REL_ CIOM SG_ 1421 TemporaryRSLDeviceIndication 600;
BA_REL_ "GenSigFirstTimeoutTime" BU_SG_REL_ DACU SG_ 1421 AutomaticCMenableStatus 3000;
BA_REL_ "GenSigTimeoutTime" BU_SG_REL_ DACU SG_ 1421 AutomaticCMenableStatus 600;
BA_REL_ "GenSigFirstTimeoutTime" BU_SG_REL_ VMCU SG_ 1421 SetDaylightSaving_rqst 3000;
BA_REL_ "GenSigTimeoutTime" BU_SG_REL_ VMCU SG_ 1421 SetDaylightSaving_rqst 600;
BA_REL_ "GenSigFirstTimeoutTime" BU_SG_REL_ VMCU SG_ 1421 CamerasPowerSupply_rqst_ISig_4 3000;
BA_REL_ "GenSigTimeoutTime" BU_SG_REL_ VMCU SG_ 1421 CamerasPowerSupply_rqst_ISig_4 600;
BA_REL_ "GenSigFirstTimeoutTime" BU_SG_REL_ VMCU SG_ 1421 AFSActiveAllowed_GUIrqst 3000;
BA_REL_ "GenSigTimeoutTime" BU_SG_REL_ VMCU SG_ 1421 AFSActiveAllowed_GUIrqst 600;
BA_REL_ "GenSigFirstTimeoutTime" BU_SG_REL_ CIOM SG_ 822 SEMMediaSourceAvail_Source04_ISi 3000;
BA_REL_ "GenSigTimeoutTime" BU_SG_REL_ CIOM SG_ 822 SEMMediaSourceAvail_Source04_ISi 300;
BA_REL_ "GenSigFirstTimeoutTime" BU_SG_REL_ CIOM SG_ 822 SEMMediaSourceAvail_Source10_ISi 3000;
BA_REL_ "GenSigTimeoutTime" BU_SG_REL_ CIOM SG_ 822 SEMMediaSourceAvail_Source10_ISi 300;
BA_REL_ "GenSigFirstTimeoutTime" BU_SG_REL_ CIOM SG_ 822 SEMMediaSourceAvail_SInfo_ISig_4 3000;
BA_REL_ "GenSigTimeoutTime" BU_SG_REL_ CIOM SG_ 822 SEMMediaSourceAvail_SInfo_ISig_4 300;
BA_REL_ "GenSigFirstTimeoutTime" BU_SG_REL_ CIOM SG_ 822 SEM_PresetIndicationCmd_ISig_4 3000;
BA_REL_ "GenSigTimeoutTime" BU_SG_REL_ CIOM SG_ 822 SEM_PresetIndicationCmd_ISig_4 300;
BA_REL_ "GenSigFirstTimeoutTime" BU_SG_REL_ CIOM SG_ 822 SEMMediaSourceAvail_Source09_ISi 3000;
BA_REL_ "GenSigTimeoutTime" BU_SG_REL_ CIOM SG_ 822 SEMMediaSourceAvail_Source09_ISi 300;
BA_REL_ "GenSigFirstTimeoutTime" BU_SG_REL_ CIOM SG_ 822 SEMMediaSourceAvail_Source12_ISi 3000;
BA_REL_ "GenSigTimeoutTime" BU_SG_REL_ CIOM SG_ 822 SEMMediaSourceAvail_Source12_ISi 300;
BA_REL_ "GenSigFirstTimeoutTime" BU_SG_REL_ CIOM SG_ 822 SEMMediaSourceAvail_Source07_ISi 3000;
BA_REL_ "GenSigTimeoutTime" BU_SG_REL_ CIOM SG_ 822 SEMMediaSourceAvail_Source07_ISi 300;
BA_REL_ "GenSigFirstTimeoutTime" BU_SG_REL_ CIOM SG_ 822 SEMMediaSourceAvail_Source03_ISi 3000;
BA_REL_ "GenSigTimeoutTime" BU_SG_REL_ CIOM SG_ 822 SEMMediaSourceAvail_Source03_ISi 300;
BA_REL_ "GenSigFirstTimeoutTime" BU_SG_REL_ CIOM SG_ 822 SEMMediaSourceAvail_Source11_ISi 3000;
BA_REL_ "GenSigTimeoutTime" BU_SG_REL_ CIOM SG_ 822 SEMMediaSourceAvail_Source11_ISi 300;
BA_REL_ "GenSigFirstTimeoutTime" BU_SG_REL_ CIOM SG_ 822 SEM_AudioVolValIndCmd_ISig_4 3000;
BA_REL_ "GenSigTimeoutTime" BU_SG_REL_ CIOM SG_ 822 SEM_AudioVolValIndCmd_ISig_4 300;
BA_REL_ "GenSigFirstTimeoutTime" BU_SG_REL_ CIOM SG_ 822 SEMMediaSourceAvail_Source02_ISi 3000;
BA_REL_ "GenSigTimeoutTime" BU_SG_REL_ CIOM SG_ 822 SEMMediaSourceAvail_Source02_ISi 300;
BA_REL_ "GenSigFirstTimeoutTime" BU_SG_REL_ CIOM SG_ 822 AudioSourceStat_ISig_4 3000;
BA_REL_ "GenSigTimeoutTime" BU_SG_REL_ CIOM SG_ 822 AudioSourceStat_ISig_4 300;
BA_REL_ "GenSigFirstTimeoutTime" BU_SG_REL_ CIOM SG_ 822 SEMMediaSourceAvail_Source06_ISi 3000;
BA_REL_ "GenSigTimeoutTime" BU_SG_REL_ CIOM SG_ 822 SEMMediaSourceAvail_Source06_ISi 300;
BA_REL_ "GenSigFirstTimeoutTime" BU_SG_REL_ CIOM SG_ 822 SEMMediaSourceAvail_Source00_ISi 3000;
BA_REL_ "GenSigTimeoutTime" BU_SG_REL_ CIOM SG_ 822 SEMMediaSourceAvail_Source00_ISi 300;
BA_REL_ "GenSigFirstTimeoutTime" BU_SG_REL_ CIOM SG_ 822 SEMMediaSourceAvail_Source01_ISi 3000;
BA_REL_ "GenSigTimeoutTime" BU_SG_REL_ CIOM SG_ 822 SEMMediaSourceAvail_Source01_ISi 300;
BA_REL_ "GenSigFirstTimeoutTime" BU_SG_REL_ CIOM SG_ 822 SEMMediaSourceAvail_Source08_ISi 3000;
BA_REL_ "GenSigTimeoutTime" BU_SG_REL_ CIOM SG_ 822 SEMMediaSourceAvail_Source08_ISi 300;
BA_REL_ "GenSigFirstTimeoutTime" BU_SG_REL_ CIOM SG_ 822 SEM_AudioMuteStat_ISig_4 3000;
BA_REL_ "GenSigTimeoutTime" BU_SG_REL_ CIOM SG_ 822 SEM_AudioMuteStat_ISig_4 300;
BA_REL_ "GenSigFirstTimeoutTime" BU_SG_REL_ CIOM SG_ 822 SEMMediaSourceAvail_Source13_ISi 3000;
BA_REL_ "GenSigTimeoutTime" BU_SG_REL_ CIOM SG_ 822 SEMMediaSourceAvail_Source13_ISi 300;
BA_REL_ "GenSigFirstTimeoutTime" BU_SG_REL_ CIOM SG_ 822 SEMMediaSourceAvail_Source05_ISi 3000;
BA_REL_ "GenSigTimeoutTime" BU_SG_REL_ CIOM SG_ 822 SEMMediaSourceAvail_Source05_ISi 300;
BA_REL_ "GenSigFirstTimeoutTime" BU_SG_REL_ VMCU SG_ 1337 TPMUnmateTrailerReq_ISig_4 12000;
BA_REL_ "GenSigTimeoutTime" BU_SG_REL_ VMCU SG_ 1337 TPMUnmateTrailerReq_ISig_4 3000;
BA_REL_ "GenSigFirstTimeoutTime" BU_SG_REL_ VMCU SG_ 1337 TPMSetAxleRefPres_Axle4_ISig_4 12000;
BA_REL_ "GenSigTimeoutTime" BU_SG_REL_ VMCU SG_ 1337 TPMSetAxleRefPres_Axle4_ISig_4 3000;
BA_REL_ "GenSigFirstTimeoutTime" BU_SG_REL_ VMCU SG_ 1337 TPMPosOfWMReq_VehiclePos_ISig_4 12000;
BA_REL_ "GenSigTimeoutTime" BU_SG_REL_ VMCU SG_ 1337 TPMPosOfWMReq_VehiclePos_ISig_4 3000;
BA_REL_ "GenSigFirstTimeoutTime" BU_SG_REL_ VMCU SG_ 1337 TPMSetAxleRefPres_Axle1_ISig_4 12000;
BA_REL_ "GenSigTimeoutTime" BU_SG_REL_ VMCU SG_ 1337 TPMSetAxleRefPres_Axle1_ISig_4 3000;
BA_REL_ "GenSigFirstTimeoutTime" BU_SG_REL_ VMCU SG_ 1337 TPMSetAxleRefPres_Axle2_ISig_4 12000;
BA_REL_ "GenSigTimeoutTime" BU_SG_REL_ VMCU SG_ 1337 TPMSetAxleRefPres_Axle2_ISig_4 3000;
BA_REL_ "GenSigFirstTimeoutTime" BU_SG_REL_ VMCU SG_ 1337 TPMSetAxleRefPres_Axle3_ISig_4 12000;
BA_REL_ "GenSigTimeoutTime" BU_SG_REL_ VMCU SG_ 1337 TPMSetAxleRefPres_Axle3_ISig_4 3000;
BA_REL_ "GenSigFirstTimeoutTime" BU_SG_REL_ VMCU SG_ 1337 TPMMateTrailerReq_ISig_4 12000;
BA_REL_ "GenSigTimeoutTime" BU_SG_REL_ VMCU SG_ 1337 TPMMateTrailerReq_ISig_4 3000;
BA_REL_ "GenSigFirstTimeoutTime" BU_SG_REL_ VMCU SG_ 1337 TPMPosOfWMReq_TireId_ISig_4 12000;
BA_REL_ "GenSigTimeoutTime" BU_SG_REL_ VMCU SG_ 1337 TPMPosOfWMReq_TireId_ISig_4 3000;
BA_REL_ "GenSigFirstTimeoutTime" BU_SG_REL_ VMCU SG_ 1337 TPMSetAxleRefPres_Axle5_ISig_4 12000;
BA_REL_ "GenSigTimeoutTime" BU_SG_REL_ VMCU SG_ 1337 TPMSetAxleRefPres_Axle5_ISig_4 3000;
BA_REL_ "GenSigFirstTimeoutTime" BU_SG_REL_ VMCU SG_ 1337 TPMSetAxleRefPres_VehiclePos_ISi 12000;
BA_REL_ "GenSigTimeoutTime" BU_SG_REL_ VMCU SG_ 1337 TPMSetAxleRefPres_VehiclePos_ISi 3000;
BA_REL_ "GenSigFirstTimeoutTime" BU_SG_REL_ VMCU SG_ 1336 TPMSetAxleTireConfig_Axle4_ISig_ 12000;
BA_REL_ "GenSigTimeoutTime" BU_SG_REL_ VMCU SG_ 1336 TPMSetAxleTireConfig_Axle4_ISig_ 3000;
BA_REL_ "GenSigFirstTimeoutTime" BU_SG_REL_ VMCU SG_ 1336 TPMSetAxleTireConfig_Axle5_ISig_ 12000;
BA_REL_ "GenSigTimeoutTime" BU_SG_REL_ VMCU SG_ 1336 TPMSetAxleTireConfig_Axle5_ISig_ 3000;
BA_REL_ "GenSigFirstTimeoutTime" BU_SG_REL_ VMCU SG_ 1336 TPMSetPresThresCfg_VehiclePos_IS 12000;
BA_REL_ "GenSigTimeoutTime" BU_SG_REL_ VMCU SG_ 1336 TPMSetPresThresCfg_VehiclePos_IS 3000;
BA_REL_ "GenSigFirstTimeoutTime" BU_SG_REL_ VMCU SG_ 1336 TPMSetPresThresCfg_ExtOverPres_I 12000;
BA_REL_ "GenSigTimeoutTime" BU_SG_REL_ VMCU SG_ 1336 TPMSetPresThresCfg_ExtOverPres_I 3000;
BA_REL_ "GenSigFirstTimeoutTime" BU_SG_REL_ VMCU SG_ 1336 TPMSetAxleTireConfig_Axle2_ISig_ 12000;
BA_REL_ "GenSigTimeoutTime" BU_SG_REL_ VMCU SG_ 1336 TPMSetAxleTireConfig_Axle2_ISig_ 3000;
BA_REL_ "GenSigFirstTimeoutTime" BU_SG_REL_ VMCU SG_ 1336 TPMSetAxleTireConfig_VehiclePos_ 12000;
BA_REL_ "GenSigTimeoutTime" BU_SG_REL_ VMCU SG_ 1336 TPMSetAxleTireConfig_VehiclePos_ 3000;
BA_REL_ "GenSigFirstTimeoutTime" BU_SG_REL_ VMCU SG_ 1336 TPMSetAxleTireConfig_Axle3_ISig_ 12000;
BA_REL_ "GenSigTimeoutTime" BU_SG_REL_ VMCU SG_ 1336 TPMSetAxleTireConfig_Axle3_ISig_ 3000;
BA_REL_ "GenSigFirstTimeoutTime" BU_SG_REL_ VMCU SG_ 1336 TPMSetAxleTireConfig_Axle1_ISig_ 12000;
BA_REL_ "GenSigTimeoutTime" BU_SG_REL_ VMCU SG_ 1336 TPMSetAxleTireConfig_Axle1_ISig_ 3000;
BA_REL_ "GenSigFirstTimeoutTime" BU_SG_REL_ VMCU SG_ 1336 TPMSetPresThresCfg_AxleNr_ISig_4 12000;
BA_REL_ "GenSigTimeoutTime" BU_SG_REL_ VMCU SG_ 1336 TPMSetPresThresCfg_AxleNr_ISig_4 3000;
BA_REL_ "GenSigFirstTimeoutTime" BU_SG_REL_ VMCU SG_ 1336 TPMSetPresThresCfg_OverPres_ISig 12000;
BA_REL_ "GenSigTimeoutTime" BU_SG_REL_ VMCU SG_ 1336 TPMSetPresThresCfg_OverPres_ISig 3000;
BA_REL_ "GenSigFirstTimeoutTime" BU_SG_REL_ VMCU SG_ 1336 TPMSetPresThresCfg_ExtUnderPres_ 12000;
BA_REL_ "GenSigTimeoutTime" BU_SG_REL_ VMCU SG_ 1336 TPMSetPresThresCfg_ExtUnderPres_ 3000;
BA_REL_ "GenSigFirstTimeoutTime" BU_SG_REL_ VMCU SG_ 1336 TPMSetPresThresCfg_UnderPres_ISi 12000;
BA_REL_ "GenSigTimeoutTime" BU_SG_REL_ VMCU SG_ 1336 TPMSetPresThresCfg_UnderPres_ISi 3000;
BA_REL_ "GenSigFirstTimeoutTime" BU_SG_REL_ VMCU SG_ 837 TPMIndicationLightReq 3000;
BA_REL_ "GenSigTimeoutTime" BU_SG_REL_ VMCU SG_ 837 TPMIndicationLightReq 300;
BA_REL_ "GenSigFirstTimeoutTime" BU_SG_REL_ CIOM SG_ 837 Regeneration_DeviceInd 3000;
BA_REL_ "GenSigTimeoutTime" BU_SG_REL_ CIOM SG_ 837 Regeneration_DeviceInd 600;
BA_REL_ "GenSigFirstTimeoutTime" BU_SG_REL_ BBM SG_ 1056 BBDtcResetOffBoardApiRqst_ISig_4 3600;
BA_REL_ "GenSigTimeoutTime" BU_SG_REL_ BBM SG_ 1056 BBDtcResetOffBoardApiRqst_ISig_4 900;
BA_REL_ "GenSigFirstTimeoutTime" BU_SG_REL_ CIOM SG_ 1056 ParkingHeaterCleaning_cmd_ISig_4 3600;
BA_REL_ "GenSigTimeoutTime" BU_SG_REL_ CIOM SG_ 1056 ParkingHeaterCleaning_cmd_ISig_4 900;
BA_REL_ "GenSigFirstTimeoutTime" BU_SG_REL_ VMCU SG_ 1056 ExteriorLightsAFSAllowed_ISig_4 3600;
BA_REL_ "GenSigTimeoutTime" BU_SG_REL_ VMCU SG_ 1056 ExteriorLightsAFSAllowed_ISig_4 900;
BA_REL_ "GenSigFirstTimeoutTime" BU_SG_REL_ BBM SG_ 1056 BBDtcResetOnBoardApiRqst_ISig_4 3600;
BA_REL_ "GenSigTimeoutTime" BU_SG_REL_ BBM SG_ 1056 BBDtcResetOnBoardApiRqst_ISig_4 900;
BA_REL_ "GenSigFirstTimeoutTime" BU_SG_REL_ BBM SG_ 1056 BBDtcListButtonGuiRqst 3600;
BA_REL_ "GenSigTimeoutTime" BU_SG_REL_ BBM SG_ 1056 BBDtcListButtonGuiRqst 900;
BA_REL_ "GenSigFirstTimeoutTime" BU_SG_REL_ VMCU SG_ 1056 SetTimeOffset_rqst 3000;
BA_REL_ "GenSigTimeoutTime" BU_SG_REL_ VMCU SG_ 1056 SetTimeOffset_rqst 900;
BA_REL_ "GenSigFirstTimeoutTime" BU_SG_REL_ BBM SG_ 1056 BBDtcResetButtonGuiRqst 3600;
BA_REL_ "GenSigTimeoutTime" BU_SG_REL_ BBM SG_ 1056 BBDtcResetButtonGuiRqst 900;
BA_REL_ "GenSigFirstTimeoutTime" BU_SG_REL_ CIOM SG_ 1056 ExtraHeating_rqst_ISig_4 3600;
BA_REL_ "GenSigTimeoutTime" BU_SG_REL_ CIOM SG_ 1056 ExtraHeating_rqst_ISig_4 900;
BA_REL_ "GenSigFirstTimeoutTime" BU_SG_REL_ TECU SG_ 1056 HillDataCtrlTGW_State_ISig_4 12000;
BA_REL_ "GenSigTimeoutTime" BU_SG_REL_ TECU SG_ 1056 HillDataCtrlTGW_State_ISig_4 900;
BA_REL_ "GenSigFirstTimeoutTime" BU_SG_REL_ TECU SG_ 1056 HillDataCtrlTGW_AckCnt_ISig_4 12000;
BA_REL_ "GenSigTimeoutTime" BU_SG_REL_ TECU SG_ 1056 HillDataCtrlTGW_AckCnt_ISig_4 900;
BA_REL_ "GenSigFirstTimeoutTime" BU_SG_REL_ BBM SG_ 1056 BBDtcListButtonSpApiRqst_ISig_4 3600;
BA_REL_ "GenSigTimeoutTime" BU_SG_REL_ BBM SG_ 1056 BBDtcListButtonSpApiRqst_ISig_4 900;
BA_REL_ "GenSigFirstTimeoutTime" BU_SG_REL_ VMCU SG_ 1334 Snooze_EventTimerReq_Id 12000;
BA_REL_ "GenSigTimeoutTime" BU_SG_REL_ VMCU SG_ 1334 Snooze_EventTimerReq_Id 3000;
BA_REL_ "GenSigFirstTimeoutTime" BU_SG_REL_ CIOM SG_ 1334 BacklightLevelHighRes2_ISig_4 12000;
BA_REL_ "GenSigTimeoutTime" BU_SG_REL_ CIOM SG_ 1334 BacklightLevelHighRes2_ISig_4 3000;
BA_REL_ "GenSigFirstTimeoutTime" BU_SG_REL_ BBM SG_ 1334 BacklightLevelHighRes2_ISig_4 12000;
BA_REL_ "GenSigTimeoutTime" BU_SG_REL_ BBM SG_ 1334 BacklightLevelHighRes2_ISig_4 3000;
BA_REL_ "GenSigFirstTimeoutTime" BU_SG_REL_ VMCU SG_ 1334 BacklightLevelHighRes2_ISig_4 12000;
BA_REL_ "GenSigTimeoutTime" BU_SG_REL_ VMCU SG_ 1334 BacklightLevelHighRes2_ISig_4 3000;
BA_REL_ "GenSigFirstTimeoutTime" BU_SG_REL_ CIOM SG_ 1334 MovingUnitTracRollerBench_ISig_4 12000;
BA_REL_ "GenSigTimeoutTime" BU_SG_REL_ CIOM SG_ 1334 MovingUnitTracRollerBench_ISig_4 3000;
BA_REL_ "GenSigFirstTimeoutTime" BU_SG_REL_ VMCU SG_ 1334 MaintReset_rqst_Selection 12000;
BA_REL_ "GenSigTimeoutTime" BU_SG_REL_ VMCU SG_ 1334 MaintReset_rqst_Selection 3000;
BA_REL_ "GenSigFirstTimeoutTime" BU_SG_REL_ VMCU SG_ 1334 MaintReset_rqst_Request 12000;
BA_REL_ "GenSigTimeoutTime" BU_SG_REL_ VMCU SG_ 1334 MaintReset_rqst_Request 3000;
BA_REL_ "GenSigFirstTimeoutTime" BU_SG_REL_ EMS SG_ 1334 DPF_ManualRegenerateInhibit 12000;
BA_REL_ "GenSigTimeoutTime" BU_SG_REL_ EMS SG_ 1334 DPF_ManualRegenerateInhibit 3000;
BA_REL_ "GenSigFirstTimeoutTime" BU_SG_REL_ VMCU SG_ 1334 Snooze_EventTimerReq_Oper 12000;
BA_REL_ "GenSigTimeoutTime" BU_SG_REL_ VMCU SG_ 1334 Snooze_EventTimerReq_Oper 3000;
BA_REL_ "GenSigFirstTimeoutTime" BU_SG_REL_ VMCU SG_ 1334 BlackPanel_stat_ISig_4 12000;
BA_REL_ "GenSigTimeoutTime" BU_SG_REL_ VMCU SG_ 1334 BlackPanel_stat_ISig_4 3000;
BA_REL_ "GenSigFirstTimeoutTime" BU_SG_REL_ CIOM SG_ 1334 BlackPanel_stat_ISig_4 12000;
BA_REL_ "GenSigTimeoutTime" BU_SG_REL_ CIOM SG_ 1334 BlackPanel_stat_ISig_4 3000;
BA_REL_ "GenSigFirstTimeoutTime" BU_SG_REL_ VMCU SG_ 1334 Snooze_EventTimerReq_Time 12000;
BA_REL_ "GenSigTimeoutTime" BU_SG_REL_ VMCU SG_ 1334 Snooze_EventTimerReq_Time 3000;
BA_REL_ "GenSigFirstTimeoutTime" BU_SG_REL_ VMCU SG_ 1334 MaintReset_rqst_ID 12000;
BA_REL_ "GenSigTimeoutTime" BU_SG_REL_ VMCU SG_ 1334 MaintReset_rqst_ID 3000;
BA_REL_ "GenSigFirstTimeoutTime" BU_SG_REL_ CIOM SG_ 1334 PS_BlackPanelStatBtnInd_ISig_4 12000;
BA_REL_ "GenSigTimeoutTime" BU_SG_REL_ CIOM SG_ 1334 PS_BlackPanelStatBtnInd_ISig_4 3000;
BA_REL_ "GenSigFirstTimeoutTime" BU_SG_REL_ EMS SG_ 1334 DPF_ManualRegenerateRequest 12000;
BA_REL_ "GenSigTimeoutTime" BU_SG_REL_ EMS SG_ 1334 DPF_ManualRegenerateRequest 3000;
BA_REL_ "GenSigFirstTimeoutTime" BU_SG_REL_ VMCU SG_ 1377 GPSData_Longitude_ISig_4_561 12000;
BA_REL_ "GenSigTimeoutTime" BU_SG_REL_ VMCU SG_ 1377 GPSData_Longitude_ISig_4_561 3000;
BA_REL_ "GenSigFirstTimeoutTime" BU_SG_REL_ VMCU SG_ 1377 GPSData_Direction_ISig_4_561 12000;
BA_REL_ "GenSigTimeoutTime" BU_SG_REL_ VMCU SG_ 1377 GPSData_Direction_ISig_4_561 3000;
BA_REL_ "GenSigFirstTimeoutTime" BU_SG_REL_ VMCU SG_ 1377 GPSData_Latitude_ISig_4_561 12000;
BA_REL_ "GenSigTimeoutTime" BU_SG_REL_ VMCU SG_ 1377 GPSData_Latitude_ISig_4_561 3000;
BA_REL_ "GenSigFirstTimeoutTime" BU_SG_REL_ VMCU SG_ 1377 GPSData_Altitude_ISig_4_561 12000;
BA_REL_ "GenSigTimeoutTime" BU_SG_REL_ VMCU SG_ 1377 GPSData_Altitude_ISig_4_561 3000;
BA_REL_ "GenSigFirstTimeoutTime" BU_SG_REL_ VMCU SG_ 1377 GPSData_HDOP_ISig_4_561 12000;
BA_REL_ "GenSigTimeoutTime" BU_SG_REL_ VMCU SG_ 1377 GPSData_HDOP_ISig_4_561 3000;
BA_REL_ "GenSigFirstTimeoutTime" BU_SG_REL_ VMCU SG_ 1377 GPSData_Time_ISig_4_561 12000;
BA_REL_ "GenSigTimeoutTime" BU_SG_REL_ VMCU SG_ 1377 GPSData_Time_ISig_4_561 3000;
BA_REL_ "GenSigFirstTimeoutTime" BU_SG_REL_ VMCU SG_ 1377 GPSData_VehSpeed_ISig_4_561 12000;
BA_REL_ "GenSigTimeoutTime" BU_SG_REL_ VMCU SG_ 1377 GPSData_VehSpeed_ISig_4_561 3000;
BA_REL_ "GenSigFirstTimeoutTime" BU_SG_REL_ VMCU SG_ 1377 GPSData_AntennaStat_ISig_4_561 12000;
BA_REL_ "GenSigTimeoutTime" BU_SG_REL_ VMCU SG_ 1377 GPSData_AntennaStat_ISig_4_561 3000;
BA_REL_ "GenSigFirstTimeoutTime" BU_SG_REL_ TECU SG_ 1375 GPSData_HDOP_ISig_4_55f 12000;
BA_REL_ "GenSigTimeoutTime" BU_SG_REL_ TECU SG_ 1375 GPSData_HDOP_ISig_4_55f 3000;
BA_REL_ "GenSigFirstTimeoutTime" BU_SG_REL_ TECU SG_ 1375 GPSData_VehSpeed_ISig_4_55f 12000;
BA_REL_ "GenSigTimeoutTime" BU_SG_REL_ TECU SG_ 1375 GPSData_VehSpeed_ISig_4_55f 3000;
BA_REL_ "GenSigFirstTimeoutTime" BU_SG_REL_ TECU SG_ 1375 GPSData_Direction_ISig_4_55f 12000;
BA_REL_ "GenSigTimeoutTime" BU_SG_REL_ TECU SG_ 1375 GPSData_Direction_ISig_4_55f 3000;
BA_REL_ "GenSigFirstTimeoutTime" BU_SG_REL_ TECU SG_ 1375 GPSData_Longitude_ISig_4_55f 12000;
BA_REL_ "GenSigTimeoutTime" BU_SG_REL_ TECU SG_ 1375 GPSData_Longitude_ISig_4_55f 3000;
BA_REL_ "GenSigFirstTimeoutTime" BU_SG_REL_ TECU SG_ 1375 GPSData_Time_ISig_4_55f 12000;
BA_REL_ "GenSigTimeoutTime" BU_SG_REL_ TECU SG_ 1375 GPSData_Time_ISig_4_55f 3000;
BA_REL_ "GenSigFirstTimeoutTime" BU_SG_REL_ TECU SG_ 1375 GPSData_Latitude_ISig_4_55f 12000;
BA_REL_ "GenSigTimeoutTime" BU_SG_REL_ TECU SG_ 1375 GPSData_Latitude_ISig_4_55f 3000;
BA_REL_ "GenSigFirstTimeoutTime" BU_SG_REL_ TECU SG_ 1375 GPSData_AntennaStat_ISig_4_55f 12000;
BA_REL_ "GenSigTimeoutTime" BU_SG_REL_ TECU SG_ 1375 GPSData_AntennaStat_ISig_4_55f 3000;
BA_REL_ "GenSigFirstTimeoutTime" BU_SG_REL_ TECU SG_ 1375 GPSData_Altitude_ISig_4_55f 12000;
BA_REL_ "GenSigTimeoutTime" BU_SG_REL_ TECU SG_ 1375 GPSData_Altitude_ISig_4_55f 3000;
VAL_ 1041 GearShiftingRec_Steps 7 "GearShiftingSteps_NotAvailable" 6 "GearShiftingSteps_Error" 5 "GearShiftingSteps_6step" 4 "GearShiftingSteps_5step" 3 "GearShiftingSteps_4step" 2 "GearShiftingSteps_3step" 1 "GearShiftingSteps_2step" 0 "GearShiftingSteps_1step" ;
VAL_ 1041 GearShiftingRec_Direction 7 "GearShiftingDirection_NotAvailable" 6 "GearShiftingDirection_Error" 5 "GearShiftingDirection_Spare3" 4 "GearShiftingDirection_Spare2" 3 "GearShiftingDirection_Spare1" 2 "GearShiftingDirection_Down" 1 "GearShiftingDirection_Up" 0 "GearShiftingDirection_NoShiftRecommendation" ;
VAL_ 1041 BrakeInterlockStatus 3 "OffOn_NotAvailable" 2 "OffOn_Error" 1 "OffOn_On" 0 "OffOn_Off" ;
VAL_ 1041 AutGearSplitPosition_ISig_4 7 "GearSplitPosition_NotAvailable" 6 "GearSplitPosition_Error" 5 "GearSplitPosition_Spare2" 4 "GearSplitPosition_Spare1" 3 "GearSplitPosition_Crawler" 2 "GearSplitPosition_NoSplit" 1 "GearSplitPosition_HighSplit" 0 "GearSplitPosition_LowSplit" ;
VAL_ 1041 TransmissionBrakeMode 3 "InactiveActive_NotAvailable" 2 "InactiveActive_Error" 1 "InactiveActive_Active" 0 "InactiveActive_Inactive" ;
VAL_ 1041 FuelEcoDrvStatus 3 "InactiveActive_NotAvailable" 2 "InactiveActive_Error" 1 "InactiveActive_Active" 0 "InactiveActive_Inactive" ;
VAL_ 1041 EcoCruiseStatus_ISig_4 7 "EcoCruiseStatus_NotAvailable" 6 "EcoCruiseStatus_Error" 5 "EcoCruiseStatus_Spare02" 4 "EcoCruiseStatus_Spare01" 3 "EcoCruiseStatus_Spare" 2 "EcoCruiseStatus_TemporarilyInactive" 1 "EcoCruiseStatus_Active" 0 "EcoCruiseStatus_Inactive" ;
VAL_ 1041 TransmissionDrivingMode_ISig_4 7 "TransmissionDrivingMode_NotAvailable" 6 "TransmissionDrivingMode_KickDown" 5 "TransmissionDrivingMode_Dynamometer" 4 "TransmissionDrivingMode_HeavyDuty" 3 "TransmissionDrivingMode_OffRoad" 2 "TransmissionDrivingMode_Performance" 1 "TransmissionDrivingMode_Balanced" 0 "TransmissionDrivingMode_EconomyExtra" ;
VAL_ 1041 AutoWheelBrakeInhibited 3 "InhibitedStatus_NotAvailable" 2 "InhibitedStatus_Error" 1 "InhibitedStatus_Inhibited" 0 "InhibitedStatus_NotInhibited" ;
VAL_ 1041 AutoWheelBrakesDownshiftSugges 3 "DownshiftSuggest_NotAvailable" 2 "DownshiftSuggest_Error" 1 "DownshiftSuggest_SuggestDownshift" 0 "DownshiftSuggest_NoSuggestion" ;
VAL_ 1041 TransmissionOilTempHigh_ISig_4 7 "TransmissionOilTempHigh_NotAvailable" 6 "TransmissionOilTempHigh_ErrorIndicator" 5 "TransmissionOilTempHigh_SpareValue_02" 4 "TransmissionOilTempHigh_SpareValue_01" 3 "TransmissionOilTempHigh_SpareValue" 2 "TransmissionOilTempHigh_ActiveVeryHighTemp" 1 "TransmissionOilTempHigh_ActiveHighTemp" 0 "TransmissionOilTempHigh_Inactive" ;
VAL_ 516 Pto1Consent_ISig_4 3 "PtoConsent_NotAvailable" 2 "PtoConsent_Error" 1 "PtoConsent_ConsentGivenPTODriveMayBeEngaged" 0 "PtoConsent_ConsentNotGivenPTODriveShouldNotBeEngaged" ;
VAL_ 516 Pto2Consent_ISig_4 3 "PtoConsent_NotAvailable" 2 "PtoConsent_Error" 1 "PtoConsent_ConsentGivenPTODriveMayBeEngaged" 0 "PtoConsent_ConsentNotGivenPTODriveShouldNotBeEngaged" ;
VAL_ 516 DirectionGearAllowed 7 "DirectionGearAllowed_NotAvailable" 6 "DirectionGearAllowed_Error" 5 "DirectionGearAllowed_NotUsed_01" 4 "DirectionGearAllowed_NotUsed" 3 "DirectionGearAllowed_ForwardOrReverseGearAllowed" 2 "DirectionGearAllowed_ReverseGearAllowed" 1 "DirectionGearAllowed_ForwardGearAllowed" 0 "DirectionGearAllowed_NoChangePossible" ;
VAL_ 516 TransmissionSystemPowerDownAck 3 "TransmissionSystemPowerDownAck_DontCare" 2 "TransmissionSystemPowerDownAck_NotDefined" 1 "TransmissionSystemPowerDownAck_OKToPowerDownTECU" 0 "TransmissionSystemPowerDownAck_NotOKToPowerDownTECU" ;
VAL_ 516 EcoRollActiveStatus_ISig_4 3 "InactiveActive_NotAvailable" 2 "InactiveActive_Error" 1 "InactiveActive_Active" 0 "InactiveActive_Inactive" ;
VAL_ 516 TransmissionAirPressureLow 3 "TransmissionAirPressureLow_NotAvailable" 2 "TransmissionAirPressureLow_Error" 1 "TransmissionAirPressureLow_AirPressureLow" 0 "TransmissionAirPressureLow_AirPressureOk" ;
VAL_ 516 GearBoxUnlockAuth_rqst 3 "GearBoxUnlockAuth_rqst_NotAvaiable" 2 "GearBoxUnlockAuth_rqst_Error" 1 "GearBoxUnlockAuth_rqst_GearEngagementRequested" 0 "GearBoxUnlockAuth_rqst_GearEngagementNotRequested" ;
VAL_ 516 TransmEngineStop_req 3 "InactiveActive_NotAvailable" 2 "InactiveActive_Error" 1 "InactiveActive_Active" 0 "InactiveActive_Inactive" ;
VAL_ 516 ACC_SGO_TransmissionStatus 7 "ACC_SGO_TransmissionStatus_NotAvailable" 6 "ACC_SGO_TransmissionStatus_Error" 5 "ACC_SGO_TransmissionStatus_Spare2" 4 "ACC_SGO_TransmissionStatus_ReadyForTakeOff" 3 "ACC_SGO_TransmissionStatus_LowestPossibleSpeedReached" 2 "ACC_SGO_TransmissionStatus_Normal" 1 "ACC_SGO_TransmissionStatus_Take_off_InProgress" 0 "ACC_SGO_TransmissionStatus_ACC_SGO_CanNotBeSupported" ;
VAL_ 516 ClutchOverloadStatus_ISig_4 3 "ClutchOverloadStatus_NotAvailable" 2 "ClutchOverloadStatus_Error" 1 "ClutchOverloadStatus_Overloaded" 0 "ClutchOverloadStatus_NotOverloaded" ;
VAL_ 1280 ExteriorLightsAFSAllowedFAKE 3 "InactiveActive_NotAvailable" 2 "InactiveActive_Error" 1 "InactiveActive_Active" 0 "InactiveActive_Inactive" ;
VAL_ 1280 CamerasPowerSupply_rqstFAKE 3 "InactiveActive_NotAvailable" 2 "InactiveActive_Error" 1 "InactiveActive_Active" 0 "InactiveActive_Inactive" ;
VAL_ 1129 AlarmClkAl_LECM_stat_Stat_ISig_4 3 "AlarmClkStat2_Snoozed" 2 "AlarmClkStat2_Ringing" 1 "AlarmClkStat2_Active" 0 "AlarmClkStat2_Inactive" ;
VAL_ 1129 AlarmClkAl_LECM_stat_Mode_ISig_4 3 "AlarmClkMode_Spare" 2 "AlarmClkMode_Timer" 1 "AlarmClkMode_Recurrent" 0 "AlarmClkMode_OneTime" ;
VAL_ 1129 AlarmClkAl_LECM_stat_ID_ISig_4 127 "AlarmClkID_NotAvailable" 126 "AlarmClkID_Error" 10 "AlarmClkID_Alarm10" 9 "AlarmClkID_Alarm9" 8 "AlarmClkID_Alarm8" 7 "AlarmClkID_Alarm7" 6 "AlarmClkID_Alarm6" 5 "AlarmClkID_Alarm5" 4 "AlarmClkID_Alarm4" 3 "AlarmClkID_Alarm3" 2 "AlarmClkID_Alarm2" 1 "AlarmClkID_Alarm1" 0 "AlarmClkID_NotUsed" ;
VAL_ 1129 AlarmClkAl_LECM_stat_Type_ISig_4 7 "AlarmClkType_NotAvailable" 6 "AlarmClkType_Error" 5 "AlarmClkType_Reserved_02" 4 "AlarmClkType_Reserved_01" 3 "AlarmClkType_Reserved" 2 "AlarmClkType_Radio" 1 "AlarmClkType_Buzzer" 0 "AlarmClkType_NoAudibleNotification" ;
VAL_ 1443 SaveTrlrName_rqst_Request 3 "InactiveActive_NotAvailable" 2 "InactiveActive_Error" 1 "InactiveActive_Active" 0 "InactiveActive_Inactive" ;
VAL_ 1443 SaveTrlrName_rqst_Position 31 "TrailerPosition5bit_NotAvailable" 30 "TrailerPosition5bit_Spare4" 29 "TrailerPosition5bit_Spare3" 28 "TrailerPosition5bit_Spare2" 27 "TrailerPosition5bit_Spare1" 26 "TrailerPosition5bit_Truck" 25 "TrailerPosition5bit_ConnectedTrailer5" 24 "TrailerPosition5bit_ConnectedTrailer4" 23 "TrailerPosition5bit_ConnectedTrailer3" 22 "TrailerPosition5bit_ConnectedTrailer2" 21 "TrailerPosition5bit_ConnectedTrailer1" 20 "TrailerPosition5bit_Trailer20" 19 "TrailerPosition5bit_Trailer19" 18 "TrailerPosition5bit_Trailer18" 17 "TrailerPosition5bit_Trailer17" 16 "TrailerPosition5bit_Trailer16" 15 "TrailerPosition5bit_Trailer15" 14 "TrailerPosition5bit_Trailer14" 13 "TrailerPosition5bit_Trailer13" 12 "TrailerPosition5bit_Trailer12" 11 "TrailerPosition5bit_Trailer11" 10 "TrailerPosition5bit_Trailer10" 9 "TrailerPosition5bit_Trailer9" 8 "TrailerPosition5bit_Trailer8" 7 "TrailerPosition5bit_Trailer7" 6 "TrailerPosition5bit_Trailer6" 5 "TrailerPosition5bit_Trailer5" 4 "TrailerPosition5bit_Trailer4" 3 "TrailerPosition5bit_Trailer3" 2 "TrailerPosition5bit_Trailer2" 1 "TrailerPosition5bit_Trailer1" 0 "TrailerPosition5bit_NoRequest" ;
VAL_ 1256 AlmClkSetAlarm_rqst_Stat 3 "AlarmClkStat2_Snoozed" 2 "AlarmClkStat2_Ringing" 1 "AlarmClkStat2_Active" 0 "AlarmClkStat2_Inactive" ;
VAL_ 1256 AlmClkSetAlarm_rqst_Mode 3 "AlarmClkMode_Spare" 2 "AlarmClkMode_Timer" 1 "AlarmClkMode_Recurrent" 0 "AlarmClkMode_OneTime" ;
VAL_ 1256 AlmClkSetAlarm_rqst_ID 127 "AlarmClkID_NotAvailable" 126 "AlarmClkID_Error" 10 "AlarmClkID_Alarm10" 9 "AlarmClkID_Alarm9" 8 "AlarmClkID_Alarm8" 7 "AlarmClkID_Alarm7" 6 "AlarmClkID_Alarm6" 5 "AlarmClkID_Alarm5" 4 "AlarmClkID_Alarm4" 3 "AlarmClkID_Alarm3" 2 "AlarmClkID_Alarm2" 1 "AlarmClkID_Alarm1" 0 "AlarmClkID_NotUsed" ;
VAL_ 1256 AlmClkSetAlarm_rqst_Type 7 "AlarmClkType_NotAvailable" 6 "AlarmClkType_Error" 5 "AlarmClkType_Reserved_02" 4 "AlarmClkType_Reserved_01" 3 "AlarmClkType_Reserved" 2 "AlarmClkType_Radio" 1 "AlarmClkType_Buzzer" 0 "AlarmClkType_NoAudibleNotification" ;
VAL_ 839 UpdParkClimTimerRqst_TimerCmd_IS 7 "PhTimer_cmd_NotAvailable" 6 "PhTimer_cmd_Error" 5 "PhTimer_cmd_Spare_02" 4 "PhTimer_cmd_Spare_01" 3 "PhTimer_cmd_TimerDeleted" 2 "PhTimer_cmd_TimerDisable" 1 "PhTimer_cmd_TimerEnable" 0 "PhTimer_cmd_NoAction" ;
VAL_ 838 PhoneButtonIndication_cmd 3 "DeviceIndication_SpareValue" 2 "DeviceIndication_Blink" 1 "DeviceIndication_On" 0 "DeviceIndication_Off" ;
VAL_ 838 AirbagTelltale_stat_ISig_4 3 "OffOn_NotAvailable" 2 "OffOn_Error" 1 "OffOn_On" 0 "OffOn_Off" ;
VAL_ 838 AudioSystemStatus_ISig_4 3 "OffOn_NotAvailable" 2 "OffOn_Error" 1 "OffOn_On" 0 "OffOn_Off" ;
VAL_ 838 AudioSourceUsbAvailable_ISig_4 3 "FalseTrue_NotAvaiable" 2 "FalseTrue_Error" 1 "FalseTrue_True" 0 "FalseTrue_False" ;
VAL_ 838 AQSModeRqst_ISig_4 7 "AQSModeRqst_NotAvailable" 6 "AQSModeRqst_Error" 5 "AQSModeRqst_Spare3" 4 "AQSModeRqst_Spare2" 3 "AQSModeRqst_Spare1" 2 "AQSModeRqst_Auto" 1 "AQSModeRqst_Off" 0 "AQSModeRqst_NoAction" ;
VAL_ 838 AudioSourceCdAvailable_ISig_4 3 "FalseTrue_NotAvaiable" 2 "FalseTrue_Error" 1 "FalseTrue_True" 0 "FalseTrue_False" ;
VAL_ 838 AudioSourceStatus2_ISig_4 15 "AudioSource_stat4bit_NotAvailable" 14 "AudioSource_stat4bit_Error" 13 "AudioSource_stat4bit_Spare7" 12 "AudioSource_stat4bit_Spare6" 11 "AudioSource_stat4bit_Spare5" 10 "AudioSource_stat4bit_Spare4" 9 "AudioSource_stat4bit_Spare3" 8 "AudioSource_stat4bit_Spare2" 7 "AudioSource_stat4bit_Spare1" 6 "AudioSource_stat4bit_BtStream" 5 "AudioSource_stat4bit_AUX1" 4 "AudioSource_stat4bit_IPOD" 3 "AudioSource_stat4bit_AUX2" 2 "AudioSource_stat4bit_USB" 1 "AudioSource_stat4bit_CD" 0 "AudioSource_stat4bit_Radio" ;
VAL_ 838 BTStatus 3 "BTStatus_NotAvailable" 2 "BTStatus_BTOnAndDeviceConnected" 1 "BTStatus_BTOnAndNoDeviceConnected" 0 "BTStatus_BTOff" ;
VAL_ 838 VCSystPowerSupply_rqst 3 "InactiveActive_NotAvailable" 2 "InactiveActive_Error" 1 "InactiveActive_Active" 0 "InactiveActive_Inactive" ;
VAL_ 838 AudioSourceBtStreamAvailable_ISi 3 "FalseTrue_NotAvaiable" 2 "FalseTrue_Error" 1 "FalseTrue_True" 0 "FalseTrue_False" ;
VAL_ 838 AudioMuteStat_ISig_4 7 "AudioMute_NotAvailable" 6 "AudioMute_ErrorIndication" 5 "AudioMute_Spare_03" 4 "AudioMute_Spare_02" 3 "AudioMute_Spare_01" 2 "AudioMute_Spare" 1 "AudioMute_Mute" 0 "AudioMute_Off" ;
VAL_ 838 ISeeEnableRequest 3 "InactiveActive_NotAvailable" 2 "InactiveActive_Error" 1 "InactiveActive_Active" 0 "InactiveActive_Inactive" ;
VAL_ 838 ACModeRqst_ISig_4 7 "ACModeReq_NotAvailable" 6 "ACModeReq_Error" 5 "ACModeReq_Spare" 4 "ACModeReq_ExtraDryCabAir" 3 "ACModeReq_HumidCabAir" 2 "ACModeReq_Standard" 1 "ACModeReq_Economy" 0 "ACModeReq_NoAction" ;
VAL_ 838 AudioSourceStatus_ISig_4 7 "AudioSourceStatus_NotAvailable" 6 "AudioSourceStatus_Error" 5 "AudioSourceStatus_AUX1" 4 "AudioSourceStatus_iPod" 3 "AudioSourceStatus_AUX2" 2 "AudioSourceStatus_USB" 1 "AudioSourceStatus_CD" 0 "AudioSourceStatus_Radio" ;
VAL_ 838 CalDataLoad_rqst_VehicleID 7 "VehicleID_NotAvailable" 6 "VehicleID_Error" 5 "VehicleID_Trailer5" 4 "VehicleID_Trailer4" 3 "VehicleID_Trailer3" 2 "VehicleID_Trailer2" 1 "VehicleID_Trailer1" 0 "VehicleID_Truck" ;
VAL_ 838 AudioSourceIpodAvailable_ISig_4 3 "FalseTrue_NotAvaiable" 2 "FalseTrue_Error" 1 "FalseTrue_True" 0 "FalseTrue_False" ;
VAL_ 838 CalDataLoad_rqst_AxleID 15 "AxleIdEnum_NotAvailable" 14 "AxleIdEnum_Error" 13 "AxleIdEnum_Reserved8" 12 "AxleIdEnum_Reserved7" 11 "AxleIdEnum_Reserved6" 10 "AxleIdEnum_Reserved5" 9 "AxleIdEnum_Reserved4" 8 "AxleIdEnum_Reserved3" 7 "AxleIdEnum_Reserved2" 6 "AxleIdEnum_Reserved1" 5 "AxleIdEnum_AxleID6" 4 "AxleIdEnum_AxleID5" 3 "AxleIdEnum_AxleID4" 2 "AxleIdEnum_AxleID3" 1 "AxleIdEnum_AxleID2" 0 "AxleIdEnum_AxleID1" ;
VAL_ 838 AutoBlowerLevelRqst_ISig_4 7 "AutoBlowerLevelRqst_NotAvailable" 6 "AutoBlowerLevelRqst_Error" 3 "AutoBlowerLevelRqst_Low" 2 "AutoBlowerLevelRqst_Normal" 1 "AutoBlowerLevelRqst_High" 0 "AutoBlowerLevelRqst_NoAction" ;
VAL_ 838 AutoDefogModeRqst_ISig_4 7 "AutoDefogModeRqst_NotAvailable" 6 "AutoDefogModeRqst_Error" 5 "AutoDefogModeRqst_Spare" 4 "AutoDefogModeRqst_Moderate" 3 "AutoDefogModeRqst_Normal" 2 "AutoDefogModeRqst_Sensitive" 1 "AutoDefogModeRqst_Off" 0 "AutoDefogModeRqst_NoAction" ;
VAL_ 515 SetParkClimTimerRqst_Mon_ISig_4 1 "NotSelectedSelected_Selected" 0 "NotSelectedSelected_NotSelected" ;
VAL_ 515 SetParkClimTimerRqst_Tue_ISig_4 1 "NotSelectedSelected_Selected" 0 "NotSelectedSelected_NotSelected" ;
VAL_ 515 SetParkClimTimerRqst_Sat_ISig_4 1 "NotSelectedSelected_Selected" 0 "NotSelectedSelected_NotSelected" ;
VAL_ 515 SetParkClimTimerRqst_Type_ISig_4 7 "TimerType_NotAvailable" 6 "TimerType_Error" 5 "TimerType_Spare3" 4 "TimerType_Spare2" 3 "TimerType_Spare1" 2 "TimerType_CabClimateTimerWithStartTime" 1 "TimerType_EngineTimerWithReadyTime" 0 "TimerType_CabClimateTimerWithReadyTime" ;
VAL_ 515 SetParkClimTimerRqst_Sun_ISig_4 1 "NotSelectedSelected_Selected" 0 "NotSelectedSelected_NotSelected" ;
VAL_ 515 SetParkClimTimerRqst_Wed_ISig_4 1 "NotSelectedSelected_Selected" 0 "NotSelectedSelected_NotSelected" ;
VAL_ 515 SetParkClimTimerRqst_Thu_ISig_4 1 "NotSelectedSelected_Selected" 0 "NotSelectedSelected_NotSelected" ;
VAL_ 515 SetParkClimTimerRqst_TimerCmd_IS 7 "PhTimer_cmd_NotAvailable" 6 "PhTimer_cmd_Error" 5 "PhTimer_cmd_Spare_02" 4 "PhTimer_cmd_Spare_01" 3 "PhTimer_cmd_TimerDeleted" 2 "PhTimer_cmd_TimerDisable" 1 "PhTimer_cmd_TimerEnable" 0 "PhTimer_cmd_NoAction" ;
VAL_ 515 SetParkClimTimerRqst_Fri_ISig_4 1 "NotSelectedSelected_Selected" 0 "NotSelectedSelected_NotSelected" ;
VAL_ 515 SetParkClimTimerRqst_Rec_ISig_4 1 "Rec_Recurrent" 0 "Rec_Once" ;
VAL_ 1306 ChargeCordStatus 3 "ChargeCordStatus_NotAvailable" 2 "ChargeCordStatus_Error" 1 "ChargeCordStatus_ChargeCordInserted" 0 "ChargeCordStatus_ChargeCordNotInserted" ;
VAL_ 1306 HVChargingStatus 7 "HVChargingStatus_NotAvailable" 6 "HVChargingStatus_Spare3" 5 "HVChargingStatus_Spare2" 4 "HVChargingStatus_Spare1" 3 "HVChargingStatus_ChargingCompleted" 2 "HVChargingStatus_Fault" 1 "HVChargingStatus_ChargingActive" 0 "HVChargingStatus_ChargingNotActive" ;
VAL_ 1306 ChargePortLockStatus 3 "UnlockedLocked_NotAvailable" 2 "UnlockedLocked_Error" 1 "UnlockedLocked_Locked" 0 "UnlockedLocked_Unlocked" ;
VAL_ 1363 ChlrVlvPsnFlt_ISig_4 3 "FalseTrue_NotAvaiable" 2 "FalseTrue_Error" 1 "FalseTrue_True" 0 "FalseTrue_False" ;
VAL_ 1110 EpsPowerSupplyAck 3 "EpsPowerSupplyAck_NotAvailable" 2 "EpsPowerSupplyAck_Error" 1 "EpsPowerSupplyAck_PowerOffAllowed" 0 "EpsPowerSupplyAck_PowerOffNotAllowed" ;
VAL_ 1110 ReqEpsAlive 3 "ActiveIndication_TakeNoAction" 2 "ActiveIndication_Reserved" 1 "ActiveIndication_Active" 0 "ActiveIndication_NotActive" ;
VAL_ 1422 FasUsrDefinedStorage_rqst_ISig_4 3 "FasUsrDefinedStorage_NotAvailable" 2 "FasUsrDefinedStorage_Error" 1 "FasUsrDefinedStorage_StoreUserDefinedSetting" 0 "FasUsrDefinedStorage_DoNotStoreUserDefinedSetting" ;
VAL_ 1422 ATC_ButtonIndication 3 "DeviceIndication_SpareValue" 2 "DeviceIndication_Blink" 1 "DeviceIndication_On" 0 "DeviceIndication_Off" ;
VAL_ 1422 FasPersonalSettingsButton_rqst_I 7 "FasPersSettingsButton_NotAvailable" 6 "FasPersSettingsButton_Error" 5 "FasPersSettingsButton_Spare" 4 "FasPersSettingsButton_UserDefinedButton" 3 "FasPersSettingsButton_PresetButtonHeavy" 2 "FasPersSettingsButton_PresetButtonFirm" 1 "FasPersSettingsButton_PresetButtonLight" 0 "FasPersSettingsButton_PresetButtonDefault" ;
VAL_ 1422 FasDriver_rqst_ISig_4 15 "FasDriver_NotAvailable" 14 "FasDriver_Error" 13 "FasDriver_Spare3" 12 "FasDriver_Spare2" 11 "FasDriver_Spare1" 10 "FasDriver_Driver10" 9 "FasDriver_Driver9" 8 "FasDriver_Driver8" 7 "FasDriver_Driver7" 6 "FasDriver_Driver6" 5 "FasDriver_Driver5" 4 "FasDriver_Driver4" 3 "FasDriver_Driver3" 2 "FasDriver_Driver2" 1 "FasDriver_Driver1" 0 "FasDriver_DefaultDriver" ;
VAL_ 1422 ESC_ButtonIndication2 3 "DeviceIndication_SpareValue" 2 "DeviceIndication_Blink" 1 "DeviceIndication_On" 0 "DeviceIndication_Off" ;
VAL_ 1422 TCS_ButtonIndication 3 "DeviceIndication_SpareValue" 2 "DeviceIndication_Blink" 1 "DeviceIndication_On" 0 "DeviceIndication_Off" ;
VAL_ 1422 ABS_ButtonIndication 3 "DeviceIndication_SpareValue" 2 "DeviceIndication_Blink" 1 "DeviceIndication_On" 0 "DeviceIndication_Off" ;
VAL_ 1421 ESCOff_DeviceIndication 3 "DeviceIndication_SpareValue" 2 "DeviceIndication_Blink" 1 "DeviceIndication_On" 0 "DeviceIndication_Off" ;
VAL_ 1421 RollerBenchGUIDeviceStatus 7 "RollerBenchGUIDeviceStatus_NotAvailable" 6 "RollerBenchGUIDeviceStatus_Error" 5 "RollerBenchGUIDeviceStatus_Spare3" 4 "RollerBenchGUIDeviceStatus_Spare2" 3 "RollerBenchGUIDeviceStatus_Spare1" 2 "RollerBenchGUIDeviceStatus_NoRequest" 1 "RollerBenchGUIDeviceStatus_On" 0 "RollerBenchGUIDeviceStatus_Off" ;
VAL_ 1421 DHCSetSpeedAdjustRequest 7 "SpeedAdjustRequest_NotAvailable" 6 "SpeedAdjustRequest_Error" 5 "SpeedAdjustRequest_Spare2" 4 "SpeedAdjustRequest_Spare1" 3 "SpeedAdjustRequest_Decrease" 2 "SpeedAdjustRequest_Increase" 1 "SpeedAdjustRequest_Set" 0 "SpeedAdjustRequest_NoRequest" ;
VAL_ 1421 TemporaryRSLDeviceIndication 3 "DeviceIndication_SpareValue" 2 "DeviceIndication_Blink" 1 "DeviceIndication_On" 0 "DeviceIndication_Off" ;
VAL_ 1421 AutomaticCMenableStatus 3 "OffOn_NotAvailable" 2 "OffOn_Error" 1 "OffOn_On" 0 "OffOn_Off" ;
VAL_ 1421 SetDaylightSaving_rqst 3 "DaylightSaving_NotAvailable" 2 "DaylightSaving_Error" 1 "DaylightSaving_DaylightSaving" 0 "DaylightSaving_Standard" ;
VAL_ 1421 CamerasPowerSupply_rqst_ISig_4 3 "InactiveActive_NotAvailable" 2 "InactiveActive_Error" 1 "InactiveActive_Active" 0 "InactiveActive_Inactive" ;
VAL_ 1421 AFSActiveAllowed_GUIrqst 3 "InactiveActive_NotAvailable" 2 "InactiveActive_Error" 1 "InactiveActive_Active" 0 "InactiveActive_Inactive" ;
VAL_ 949 MediaSourcesListRsp_SInfo_ISig_4 3 "SignalInfo2bitType_NotAvailable" 2 "SignalInfo2bitType_ErrorIndication" 1 "SignalInfo2bitType_Spare" 0 "SignalInfo2bitType_Valid" ;
VAL_ 822 SEMMediaSourceAvail_Source04_ISi 1 "Bitfield1BitType_True" 0 "Bitfield1BitType_False" ;
VAL_ 822 SEMMediaSourceAvail_Source10_ISi 1 "Bitfield1BitType_True" 0 "Bitfield1BitType_False" ;
VAL_ 822 SEMMediaSourceAvail_SInfo_ISig_4 3 "SignalInfo2bitType_NotAvailable" 2 "SignalInfo2bitType_ErrorIndication" 1 "SignalInfo2bitType_Spare" 0 "SignalInfo2bitType_Valid" ;
VAL_ 822 SEMMediaSourceAvail_Source09_ISi 1 "Bitfield1BitType_True" 0 "Bitfield1BitType_False" ;
VAL_ 822 SEMMediaSourceAvail_Source12_ISi 1 "Bitfield1BitType_True" 0 "Bitfield1BitType_False" ;
VAL_ 822 SEMMediaSourceAvail_Source07_ISi 1 "Bitfield1BitType_True" 0 "Bitfield1BitType_False" ;
VAL_ 822 SEMMediaSourceAvail_Source03_ISi 1 "Bitfield1BitType_True" 0 "Bitfield1BitType_False" ;
VAL_ 822 SEMMediaSourceAvail_Source11_ISi 1 "Bitfield1BitType_True" 0 "Bitfield1BitType_False" ;
VAL_ 822 SEMMediaSourceAvail_Source02_ISi 1 "Bitfield1BitType_True" 0 "Bitfield1BitType_False" ;
VAL_ 822 AudioSourceStat_ISig_4 15 "AudioSource_NotAvailable" 14 "AudioSource_Error" 13 "AudioSource_Source13" 12 "AudioSource_Source12" 11 "AudioSource_Source11" 10 "AudioSource_Source10" 9 "AudioSource_Source09" 8 "AudioSource_Source08" 7 "AudioSource_Source07" 6 "AudioSource_Source06" 5 "AudioSource_Source05" 4 "AudioSource_Source04" 3 "AudioSource_Source03" 2 "AudioSource_Source02" 1 "AudioSource_Source01" 0 "AudioSource_Source00" ;
VAL_ 822 SEMMediaSourceAvail_Source06_ISi 1 "Bitfield1BitType_True" 0 "Bitfield1BitType_False" ;
VAL_ 822 SEMMediaSourceAvail_Source00_ISi 1 "Bitfield1BitType_True" 0 "Bitfield1BitType_False" ;
VAL_ 822 SEMMediaSourceAvail_Source01_ISi 1 "Bitfield1BitType_True" 0 "Bitfield1BitType_False" ;
VAL_ 822 SEMMediaSourceAvail_Source08_ISi 1 "Bitfield1BitType_True" 0 "Bitfield1BitType_False" ;
VAL_ 822 SEM_AudioMuteStat_ISig_4 7 "AudioMute_NotAvailable" 6 "AudioMute_ErrorIndication" 5 "AudioMute_Spare_03" 4 "AudioMute_Spare_02" 3 "AudioMute_Spare_01" 2 "AudioMute_Spare" 1 "AudioMute_Mute" 0 "AudioMute_Off" ;
VAL_ 822 SEMMediaSourceAvail_Source13_ISi 1 "Bitfield1BitType_True" 0 "Bitfield1BitType_False" ;
VAL_ 822 SEMMediaSourceAvail_Source05_ISi 1 "Bitfield1BitType_True" 0 "Bitfield1BitType_False" ;
VAL_ 1337 TPMUnmateTrailerReq_ISig_4 3 "Request_NotAvailable" 2 "Request_Error" 1 "Request_RequestActive" 0 "Request_NotRequested" ;
VAL_ 1337 TPMPosOfWMReq_VehiclePos_ISig_4 7 "TPMVehiclePos_NotAvailable" 6 "TPMVehiclePos_Error" 5 "TPMVehiclePos_Trailer5Vehicle" 4 "TPMVehiclePos_Trailer4Vehicle" 3 "TPMVehiclePos_Trailer3Vehicle" 2 "TPMVehiclePos_Trailer2Vehicle" 1 "TPMVehiclePos_Trailer1Vehicle" 0 "TPMVehiclePos_TruckVehicle" ;
VAL_ 1337 TPMMateTrailerReq_ISig_4 3 "Request_NotAvailable" 2 "Request_Error" 1 "Request_RequestActive" 0 "Request_NotRequested" ;
VAL_ 1337 TPMSetAxleRefPres_VehiclePos_ISi 7 "TPMVehiclePos_NotAvailable" 6 "TPMVehiclePos_Error" 5 "TPMVehiclePos_Trailer5Vehicle" 4 "TPMVehiclePos_Trailer4Vehicle" 3 "TPMVehiclePos_Trailer3Vehicle" 2 "TPMVehiclePos_Trailer2Vehicle" 1 "TPMVehiclePos_Trailer1Vehicle" 0 "TPMVehiclePos_TruckVehicle" ;
VAL_ 1336 TPMSetAxleTireConfig_Axle4_ISig_ 7 "TPMAxleConfig_NotAvailable" 6 "TPMAxleConfig_Error" 5 "TPMAxleConfig_Spare" 4 "TPMAxleConfig_RearAxleWith4Tires" 3 "TPMAxleConfig_RearAxleWith2Tires" 2 "TPMAxleConfig_FrontAxleWith4Tires" 1 "TPMAxleConfig_FrontAxleWith2Tires" 0 "TPMAxleConfig_NotPresent" ;
VAL_ 1336 TPMSetAxleTireConfig_Axle5_ISig_ 7 "TPMAxleConfig_NotAvailable" 6 "TPMAxleConfig_Error" 5 "TPMAxleConfig_Spare" 4 "TPMAxleConfig_RearAxleWith4Tires" 3 "TPMAxleConfig_RearAxleWith2Tires" 2 "TPMAxleConfig_FrontAxleWith4Tires" 1 "TPMAxleConfig_FrontAxleWith2Tires" 0 "TPMAxleConfig_NotPresent" ;
VAL_ 1336 TPMSetPresThresCfg_VehiclePos_IS 7 "TPMVehiclePos_NotAvailable" 6 "TPMVehiclePos_Error" 5 "TPMVehiclePos_Trailer5Vehicle" 4 "TPMVehiclePos_Trailer4Vehicle" 3 "TPMVehiclePos_Trailer3Vehicle" 2 "TPMVehiclePos_Trailer2Vehicle" 1 "TPMVehiclePos_Trailer1Vehicle" 0 "TPMVehiclePos_TruckVehicle" ;
VAL_ 1336 TPMSetAxleTireConfig_Axle2_ISig_ 7 "TPMAxleConfig_NotAvailable" 6 "TPMAxleConfig_Error" 5 "TPMAxleConfig_Spare" 4 "TPMAxleConfig_RearAxleWith4Tires" 3 "TPMAxleConfig_RearAxleWith2Tires" 2 "TPMAxleConfig_FrontAxleWith4Tires" 1 "TPMAxleConfig_FrontAxleWith2Tires" 0 "TPMAxleConfig_NotPresent" ;
VAL_ 1336 TPMSetAxleTireConfig_VehiclePos_ 7 "TPMVehiclePos_NotAvailable" 6 "TPMVehiclePos_Error" 5 "TPMVehiclePos_Trailer5Vehicle" 4 "TPMVehiclePos_Trailer4Vehicle" 3 "TPMVehiclePos_Trailer3Vehicle" 2 "TPMVehiclePos_Trailer2Vehicle" 1 "TPMVehiclePos_Trailer1Vehicle" 0 "TPMVehiclePos_TruckVehicle" ;
VAL_ 1336 TPMSetAxleTireConfig_Axle3_ISig_ 7 "TPMAxleConfig_NotAvailable" 6 "TPMAxleConfig_Error" 5 "TPMAxleConfig_Spare" 4 "TPMAxleConfig_RearAxleWith4Tires" 3 "TPMAxleConfig_RearAxleWith2Tires" 2 "TPMAxleConfig_FrontAxleWith4Tires" 1 "TPMAxleConfig_FrontAxleWith2Tires" 0 "TPMAxleConfig_NotPresent" ;
VAL_ 1336 TPMSetAxleTireConfig_Axle1_ISig_ 7 "TPMAxleConfig_NotAvailable" 6 "TPMAxleConfig_Error" 5 "TPMAxleConfig_Spare" 4 "TPMAxleConfig_RearAxleWith4Tires" 3 "TPMAxleConfig_RearAxleWith2Tires" 2 "TPMAxleConfig_FrontAxleWith4Tires" 1 "TPMAxleConfig_FrontAxleWith2Tires" 0 "TPMAxleConfig_NotPresent" ;
VAL_ 1336 TPMSetPresThresCfg_AxleNr_ISig_4 7 "TPMAxleNr_NotAvailable" 6 "TPMAxleNr_Error" 5 "TPMAxleNr_Axle5" 4 "TPMAxleNr_Axle4" 3 "TPMAxleNr_Axle3" 2 "TPMAxleNr_Axle2" 1 "TPMAxleNr_Axle1" 0 "TPMAxleNr_NoRequest" ;
VAL_ 837 TPMIndicationLightReq 3 "Request_NotAvailable" 2 "Request_Error" 1 "Request_RequestActive" 0 "Request_NotRequested" ;
VAL_ 837 Regeneration_DeviceInd 15 "DualDeviceIndication_UpperDontCareLowerDontCare" 14 "DualDeviceIndication_UpperBlinkLowerDontCare" 13 "DualDeviceIndication_UpperOnLowerDontCare" 12 "DualDeviceIndication_UpperOffLowerDontCare" 11 "DualDeviceIndication_UpperDontCareLowerBlink" 10 "DualDeviceIndication_UpperBlinkLowerBlink" 9 "DualDeviceIndication_UpperOnLowerBlink" 8 "DualDeviceIndication_UpperOffLowerBlink" 7 "DualDeviceIndication_UpperDontCareLowerOn" 6 "DualDeviceIndication_UpperBlinkLowerOn" 5 "DualDeviceIndication_UpperOnLowerOn" 4 "DualDeviceIndication_UpperOffLowerOn" 3 "DualDeviceIndication_UpperDontCareLowerOff" 2 "DualDeviceIndication_UpperBlinkLowerOff" 1 "DualDeviceIndication_UpperOnLowerOff" 0 "DualDeviceIndication_UpperOffLowerOff" ;
VAL_ 1056 BBDtcResetOffBoardApiRqst_ISig_4 15 "DtcResetRqst_NotAvailable" 14 "DtcResetRqst_Error" 13 "DtcResetRqst_Spare3" 12 "DtcResetRqst_Spare2" 11 "DtcResetRqst_Spare1" 10 "DtcResetRqst_DTC10" 9 "DtcResetRqst_DTC9" 8 "DtcResetRqst_DTC8" 7 "DtcResetRqst_DTC7" 6 "DtcResetRqst_DTC6" 5 "DtcResetRqst_DTC5" 4 "DtcResetRqst_DTC4" 3 "DtcResetRqst_DTC3" 2 "DtcResetRqst_DTC2" 1 "DtcResetRqst_DTC1" 0 "DtcResetRqst_NoRequest" ;
VAL_ 1056 ParkingHeaterCleaning_cmd_ISig_4 3 "ParkingHeaterCleaning_cmd_NotAvailable" 2 "ParkingHeaterCleaning_cmd_Escaped" 1 "ParkingHeaterCleaning_cmd_Activated" 0 "ParkingHeaterCleaning_cmd_NoAction" ;
VAL_ 1056 ExteriorLightsAFSAllowed_ISig_4 3 "InactiveActive_NotAvailable" 2 "InactiveActive_Error" 1 "InactiveActive_Active" 0 "InactiveActive_Inactive" ;
VAL_ 1056 BBDtcResetOnBoardApiRqst_ISig_4 15 "DtcResetRqst_NotAvailable" 14 "DtcResetRqst_Error" 13 "DtcResetRqst_Spare3" 12 "DtcResetRqst_Spare2" 11 "DtcResetRqst_Spare1" 10 "DtcResetRqst_DTC10" 9 "DtcResetRqst_DTC9" 8 "DtcResetRqst_DTC8" 7 "DtcResetRqst_DTC7" 6 "DtcResetRqst_DTC6" 5 "DtcResetRqst_DTC5" 4 "DtcResetRqst_DTC4" 3 "DtcResetRqst_DTC3" 2 "DtcResetRqst_DTC2" 1 "DtcResetRqst_DTC1" 0 "DtcResetRqst_NoRequest" ;
VAL_ 1056 BBDtcListButtonGuiRqst 3 "Request_NotAvailable" 2 "Request_Error" 1 "Request_RequestActive" 0 "Request_NotRequested" ;
VAL_ 1056 BBDtcResetButtonGuiRqst 15 "DtcResetRqst_NotAvailable" 14 "DtcResetRqst_Error" 13 "DtcResetRqst_Spare3" 12 "DtcResetRqst_Spare2" 11 "DtcResetRqst_Spare1" 10 "DtcResetRqst_DTC10" 9 "DtcResetRqst_DTC9" 8 "DtcResetRqst_DTC8" 7 "DtcResetRqst_DTC7" 6 "DtcResetRqst_DTC6" 5 "DtcResetRqst_DTC5" 4 "DtcResetRqst_DTC4" 3 "DtcResetRqst_DTC3" 2 "DtcResetRqst_DTC2" 1 "DtcResetRqst_DTC1" 0 "DtcResetRqst_NoRequest" ;
VAL_ 1056 ExtraHeating_rqst_ISig_4 7 "ActivationRequest_NotAvailable" 6 "ActivationRequest_Error" 5 "ActivationRequest_Spare3" 4 "ActivationRequest_Spare2" 3 "ActivationRequest_Spare1" 2 "ActivationRequest_AutoStart" 1 "ActivationRequest_Off" 0 "ActivationRequest_NoAction" ;
VAL_ 1056 HillDataCtrlTGW_State_ISig_4 7 "HillDataState_NotAvailable" 6 "HillDataState_Error" 5 "HillDataState_Spare_03" 4 "HillDataState_Spare_02" 3 "HillDataState_Spare_01" 2 "HillDataState_Receive" 1 "HillDataState_Request" 0 "HillDataState_Idle" ;
VAL_ 1056 BBDtcListButtonSpApiRqst_ISig_4 3 "Request_NotAvailable" 2 "Request_Error" 1 "Request_RequestActive" 0 "Request_NotRequested" ;
VAL_ 1334 MovingUnitTracRollerBench_ISig_4 3 "OffOn_NotAvailable" 2 "OffOn_Error" 1 "OffOn_On" 0 "OffOn_Off" ;
VAL_ 1334 MaintReset_rqst_Request 3 "ResetRequest_NotAvailable" 2 "ResetRequest_Error" 1 "ResetRequest_ResetRequested" 0 "ResetRequest_NoResetRequested" ;
VAL_ 1334 DPF_ManualRegenerateInhibit 3 "InactiveActive_NotAvailable" 2 "InactiveActive_Error" 1 "InactiveActive_Active" 0 "InactiveActive_Inactive" ;
VAL_ 1334 Snooze_EventTimerReq_Oper 7 "TimerOper_NotAvailable" 6 "TimerOper_Error" 5 "TimerOper_Spare3" 4 "TimerOper_Spare2" 3 "TimerOper_Spare1" 2 "TimerOper_ResetTimer" 1 "TimerOper_StartTimer" 0 "TimerOper_NoAction" ;
VAL_ 1334 BlackPanel_stat_ISig_4 3 "InactiveActive_NotAvailable" 2 "InactiveActive_Error" 1 "InactiveActive_Active" 0 "InactiveActive_Inactive" ;
VAL_ 1334 PS_BlackPanelStatBtnInd_ISig_4 3 "InactiveActiveSpare_NotAvailable" 2 "InactiveActiveSpare_Spare" 1 "InactiveActiveSpare_Active" 0 "InactiveActiveSpare_Inactive" ;
VAL_ 1334 DPF_ManualRegenerateRequest 3 "Request_NotAvailable" 2 "Request_Error" 1 "Request_RequestActive" 0 "Request_NotRequested" ;
VAL_ 1377 GPSData_AntennaStat_ISig_4_561 7 "GPS_Antenna_status_NA" 6 "GPS_Antenna_status_ErrorIndicator" 5 "GPS_Antenna_status_SpareValue_01" 4 "GPS_Antenna_status_SpareValue" 3 "GPS_Antenna_status_AntennaStatusUnknown" 2 "GPS_Antenna_status_AntennaInit" 1 "GPS_Antenna_status_AntennaDisconnected" 0 "GPS_Antenna_status_AntennaStatusOK" ;
VAL_ 1375 GPSData_AntennaStat_ISig_4_55f 7 "GPS_Antenna_status_NA" 6 "GPS_Antenna_status_ErrorIndicator" 5 "GPS_Antenna_status_SpareValue_01" 4 "GPS_Antenna_status_SpareValue" 3 "GPS_Antenna_status_AntennaStatusUnknown" 2 "GPS_Antenna_status_AntennaInit" 1 "GPS_Antenna_status_AntennaDisconnected" 0 "GPS_Antenna_status_AntennaStatusOK" ;
SIG_GROUP_ 1041 GearShiftingRec_sg 1 : GearShiftingRec_Steps GearShiftingRec_Direction;
SIG_GROUP_ 1129 AlarmClkAl_LECM_stat_sg_ISig_4 1 : AlarmClkAl_LECM_stat_SetMin_ISig AlarmClkAl_LECM_stat_SetHr_ISig_ AlarmClkAl_LECM_stat_Stat_ISig_4 AlarmClkAl_LECM_stat_Mode_ISig_4 AlarmClkAl_LECM_stat_ID_ISig_4 AlarmClkAl_LECM_stat_Type_ISig_4 AlarmClkAl_LECM_stat_DaySet_ISig;
SIG_GROUP_ 1443 SaveTrlrName_rqst_sg 1 : SaveTrlrName_rqst_Request SaveTrlrName_rqst_NewName SaveTrlrName_rqst_Position;
SIG_GROUP_ 1214 ChangeDate_rqst_sg 1 : ChangeDate_rqst_Day ChangeDate_rqst_Year ChangeDate_rqst_Month;
SIG_GROUP_ 1214 ChangeTime_rqst_sg 1 : ChangeTime_rqst_Minutes ChangeTime_rqst_Hours;
SIG_GROUP_ 1256 AlmClkSetAlarm_rqst_sg 1 : AlmClkSetAlarm_rqst_Stat AlmClkSetAlarm_rqst_Mode AlmClkSetAlarm_rqst_SetHr AlmClkSetAlarm_rqst_ID AlmClkSetAlarm_rqst_SetMin AlmClkSetAlarm_rqst_Type AlmClkSetAlarm_rqst_DaySet;
SIG_GROUP_ 839 UpdParkClimTimerRqst_sg_ISig_4 1 : UpdParkClimTimerRqst_TimerCmd_IS UpdParkClimTimerRqst_TimRqst_ISi;
SIG_GROUP_ 839 CombinationScaleLoad_sg 1 : CombinationScaleLoad_ScaleLoad CombinationScaleLoad_FirstAxleID CombinationScaleLoad_LastAxleID;
SIG_GROUP_ 838 CalDataLoad_rqst_sg 1 : CalDataLoad_rqst_VehicleID CalDataLoad_rqst_AxleID;
SIG_GROUP_ 515 SetParkClimTimerRqst_sg_ISig_4 1 : SetParkClimTimerRqst_Mon_ISig_4 SetParkClimTimerRqst_Tue_ISig_4 SetParkClimTimerRqst_Sat_ISig_4 SetParkClimTimerRqst_Dur_ISig_4 SetParkClimTimerRqst_Type_ISig_4 SetParkClimTimerRqst_Sun_ISig_4 SetParkClimTimerRqst_Wed_ISig_4 SetParkClimTimerRqst_TimerNr_ISi SetParkClimTimerRqst_Min_ISig_4 SetParkClimTimerRqst_Hrs_ISig_4 SetParkClimTimerRqst_Temp_ISig_4 SetParkClimTimerRqst_Thu_ISig_4 SetParkClimTimerRqst_TimerCmd_IS SetParkClimTimerRqst_Fri_ISig_4 SetParkClimTimerRqst_Rec_ISig_4;
SIG_GROUP_ 949 MediaSourcesListRsp_sg_ISig_4 1 : MediaSourcesListRsp_SrcAttrib_IS MediaSourcesListRsp_SInfo_ISig_4 MediaSourcesListRsp_Name_ISig_4 MediaSourcesListRsp_PCI_ISig_4 MediaSourcesListRsp_ItemID_ISig_;
SIG_GROUP_ 822 SEMMediaSourceAvail_sg_ISig_4 1 : SEMMediaSourceAvail_Source04_ISi SEMMediaSourceAvail_Source10_ISi SEMMediaSourceAvail_SInfo_ISig_4 SEMMediaSourceAvail_Source09_ISi SEMMediaSourceAvail_Source12_ISi SEMMediaSourceAvail_Source07_ISi SEMMediaSourceAvail_Source03_ISi SEMMediaSourceAvail_Source11_ISi SEMMediaSourceAvail_Source02_ISi SEMMediaSourceAvail_Source06_ISi SEMMediaSourceAvail_Source00_ISi SEMMediaSourceAvail_Source01_ISi SEMMediaSourceAvail_Source08_ISi SEMMediaSourceAvail_Source13_ISi SEMMediaSourceAvail_Source05_ISi;
SIG_GROUP_ 1337 TPMPosOfWMReq_sg_ISig_4 1 : TPMPosOfWMReq_VehiclePos_ISig_4 TPMPosOfWMReq_TireId_ISig_4;
SIG_GROUP_ 1337 TPMSetAxleRefPres_sg_ISig_4 1 : TPMSetAxleRefPres_Axle4_ISig_4 TPMSetAxleRefPres_Axle1_ISig_4 TPMSetAxleRefPres_Axle2_ISig_4 TPMSetAxleRefPres_Axle3_ISig_4 TPMSetAxleRefPres_Axle5_ISig_4 TPMSetAxleRefPres_VehiclePos_ISi;
SIG_GROUP_ 1336 TPMSetPresThresCfg_sg_ISig_4 1 : TPMSetPresThresCfg_VehiclePos_IS TPMSetPresThresCfg_ExtOverPres_I TPMSetPresThresCfg_AxleNr_ISig_4 TPMSetPresThresCfg_OverPres_ISig TPMSetPresThresCfg_ExtUnderPres_ TPMSetPresThresCfg_UnderPres_ISi;
SIG_GROUP_ 1336 TPMSetAxleTireConfig_sg_ISig_4 1 : TPMSetAxleTireConfig_Axle4_ISig_ TPMSetAxleTireConfig_Axle5_ISig_ TPMSetAxleTireConfig_Axle2_ISig_ TPMSetAxleTireConfig_VehiclePos_ TPMSetAxleTireConfig_Axle3_ISig_ TPMSetAxleTireConfig_Axle1_ISig_;
SIG_GROUP_ 1056 HillDataCtrlTGW_sg_ISig_4 1 : HillDataCtrlTGW_State_ISig_4 HillDataCtrlTGW_AckCnt_ISig_4;
SIG_GROUP_ 1334 Snooze_EventTimerReq_sg 1 : Snooze_EventTimerReq_Id Snooze_EventTimerReq_Oper Snooze_EventTimerReq_Time;
SIG_GROUP_ 1334 MaintReset_rqst_sg 1 : MaintReset_rqst_Selection MaintReset_rqst_Request MaintReset_rqst_ID;
SIG_GROUP_ 1377 GPSData_sg_ISig_4_561 1 : GPSData_Longitude_ISig_4_561 GPSData_Direction_ISig_4_561 GPSData_Latitude_ISig_4_561 GPSData_Altitude_ISig_4_561 GPSData_HDOP_ISig_4_561 GPSData_Time_ISig_4_561 GPSData_VehSpeed_ISig_4_561 GPSData_AntennaStat_ISig_4_561;
SIG_GROUP_ 1375 GPSData_sg_ISig_4_55f 1 : GPSData_HDOP_ISig_4_55f GPSData_VehSpeed_ISig_4_55f GPSData_Direction_ISig_4_55f GPSData_Longitude_ISig_4_55f GPSData_Time_ISig_4_55f GPSData_Latitude_ISig_4_55f GPSData_AntennaStat_ISig_4_55f GPSData_Altitude_ISig_4_55f;
